VERSION "HNNBNNNYNNNNNNNNNNNNNNNNNNNNNNNNNNNNNNNNNN/4/%%%/4/'%**4NNN///"

NS_ :

BS_:

BU_: BAP_Tester BedienDisp_mi BedienDisp_vo_mi CDI ConMod_CD DashCAM Gateway_Max ICC_IO_Node LSH OCU RDK_RS3 Sound_MIB_ab_Gen3 STH ZR_MIB_EINSTIEG_ab_Gen3 ZR_MIB_OPTION_ab_Gen3 ZR_MIB_TOP_ab_Gen3

BO_ 2589283936 AC_FES_Atmosphere_01: 8 Gateway_Max
 SG_ AC_FES_Atmosphere_AMB_RGB_1 : 16|24@1+ (1,0) [0|16777215] "Unit_None"  BedienDisp_mi
 SG_ AC_FES_Atmosphere_AMB_RGB_2 : 40|24@1+ (1,0) [0|16777215] "Unit_None"  BedienDisp_mi

BO_ 2589283937 AC_FES_Atmosphere_02: 8 Gateway_Max
 SG_ AC_FES_Atmosphere_AMB_RGB_3 : 16|24@1+ (1,0) [0|16777215] "Unit_None"  BedienDisp_mi
 SG_ AC_FES_Atmosphere_AMB_RGB_4 : 40|24@1+ (1,0) [0|16777215] "Unit_None"  BedienDisp_mi

BO_ 2589283938 AC_FES_Atmosphere_03: 8 Gateway_Max
 SG_ AC_FES_Atmosphere_AMB_RGB_5 : 16|24@1+ (1,0) [0|16777215] "Unit_None"  BedienDisp_mi
 SG_ AC_FES_Atmosphere_AMB_RGB_6 : 40|24@1+ (1,0) [0|16777215] "Unit_None"  BedienDisp_mi

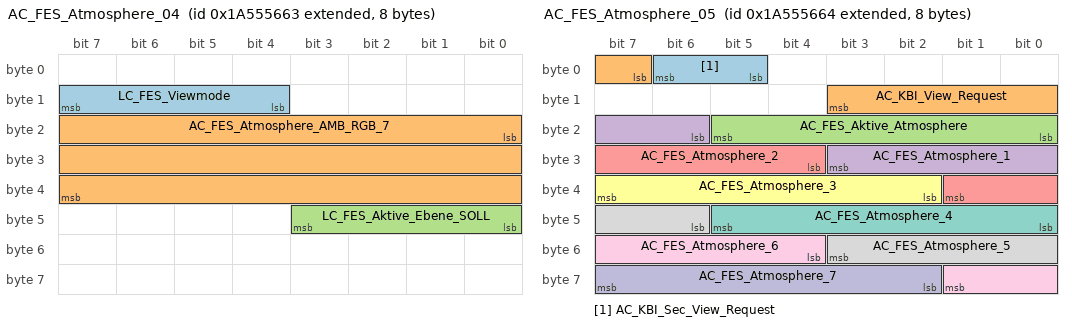
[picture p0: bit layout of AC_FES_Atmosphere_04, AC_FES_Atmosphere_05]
BO_ 2589283939 AC_FES_Atmosphere_04: 8 Gateway_Max
 SG_ LC_FES_Viewmode : 12|4@1+ (1.0,0.0) [0.0|15] ""  BedienDisp_mi
 SG_ AC_FES_Atmosphere_AMB_RGB_7 : 16|24@1+ (1,0) [0|16777215] "Unit_None"  BedienDisp_mi
 SG_ LC_FES_Aktive_Ebene_SOLL : 40|4@1+ (1.0,0.0) [0.0|15] ""  BedienDisp_mi

BO_ 2589283940 AC_FES_Atmosphere_05: 8 Gateway_Max
 SG_ AC_KBI_Sec_View_Request : 5|2@1+ (1.0,0.0) [0.0|3] ""  Gateway_Max
 SG_ AC_KBI_View_Request : 7|5@1+ (1.0,0.0) [0.0|31] ""  Gateway_Max
 SG_ AC_FES_Aktive_Atmosphere : 16|6@1+ (1.0,0.0) [0.0|63] ""  BedienDisp_mi,Gateway_Max
 SG_ AC_FES_Atmosphere_1 : 22|6@1+ (1.0,0.0) [0.0|63] ""  BedienDisp_mi,Gateway_Max
 SG_ AC_FES_Atmosphere_2 : 28|6@1+ (1.0,0.0) [0.0|63] ""  BedienDisp_mi,Gateway_Max
 SG_ AC_FES_Atmosphere_3 : 34|6@1+ (1.0,0.0) [0.0|63] ""  BedienDisp_mi,Gateway_Max
 SG_ AC_FES_Atmosphere_4 : 40|6@1+ (1.0,0.0) [0.0|63] ""  BedienDisp_mi,Gateway_Max
 SG_ AC_FES_Atmosphere_5 : 46|6@1+ (1.0,0.0) [0.0|63] ""  BedienDisp_mi,Gateway_Max
 SG_ AC_FES_Atmosphere_6 : 52|6@1+ (1.0,0.0) [0.0|63] ""  BedienDisp_mi,Gateway_Max
 SG_ AC_FES_Atmosphere_7 : 58|6@1+ (1.0,0.0) [0.0|63] ""  BedienDisp_mi,Gateway_Max

BO_ 680 ACC_14: 8 Gateway_Max
 SG_ ACA_Querfuehrung_Texte : 0|3@1+ (1.0,0.0) [0.0|7] ""  Vector__XXX
 SG_ ACA_Hinweistexte : 3|3@1+ (1.0,0.0) [0.0|7] ""  Vector__XXX
 SG_ ACC_FoD_Status : 6|2@1+ (1.0,0.0) [0.0|3] ""  Vector__XXX
 SG_ ACC_Texte_Abstandswarner : 8|2@1+ (1.0,0.0) [0.0|3] ""  Vector__XXX
 SG_ ACC_Vorz_Abstandswarner : 10|2@1+ (1.0,0.0) [0.0|3] ""  Vector__XXX
 SG_ ACC_Texte_Sekundaeranz : 12|4@1+ (1.0,0.0) [0.0|15] ""  Vector__XXX
 SG_ ACC_Status_Anzeige : 16|3@1+ (1.0,0.0) [0.0|7] ""  ZR_MIB_EINSTIEG_ab_Gen3,ZR_MIB_OPTION_ab_Gen3,ZR_MIB_TOP_ab_Gen3
 SG_ ACC_Akustik_03 : 19|3@1+ (1.0,0.0) [0.0|7] ""  Vector__XXX
 SG_ ACC_Geschw_Zielfahrzeug : 22|10@1+ (0.32,0) [0.00|326.72] "Unit_KiloMeterPerHour"  Vector__XXX
 SG_ ACC_Texte_02 : 32|6@1+ (1.0,0.0) [0.0|63] ""  Vector__XXX
 SG_ ACC_STA_Text : 38|1@1+ (1.0,0.0) [0.0|1] ""  Vector__XXX
 SG_ ACC_Status_Stauende : 39|1@1+ (1.0,0.0) [0.0|1] ""  Vector__XXX
 SG_ STA_Texte : 40|3@1+ (1.0,0.0) [0.0|7] ""  Vector__XXX
 SG_ AbstWarn_LRR_FAS_Fkt_Status : 43|2@1+ (1.0,0.0) [0.0|3] ""  Vector__XXX
 SG_ STA_Zusatzanz : 45|2@1+ (1.0,0.0) [0.0|3] ""  Vector__XXX
 SG_ FAS_Licht_Anf : 47|1@1+ (1.0,0.0) [0.0|1] ""  Vector__XXX
 SG_ ACC_Zeitluecke_Abstandswarner : 48|6@1+ (0.1,0) [0.0|6.0] "Unit_Secon"  Vector__XXX
 SG_ ACC_Abstand_Abstandswarner : 54|9@1+ (1,0) [0|508] ""  Vector__XXX
 SG_ ACC_Einheit_Abstandswarner : 63|1@1+ (1.0,0.0) [0.0|1] ""  Vector__XXX

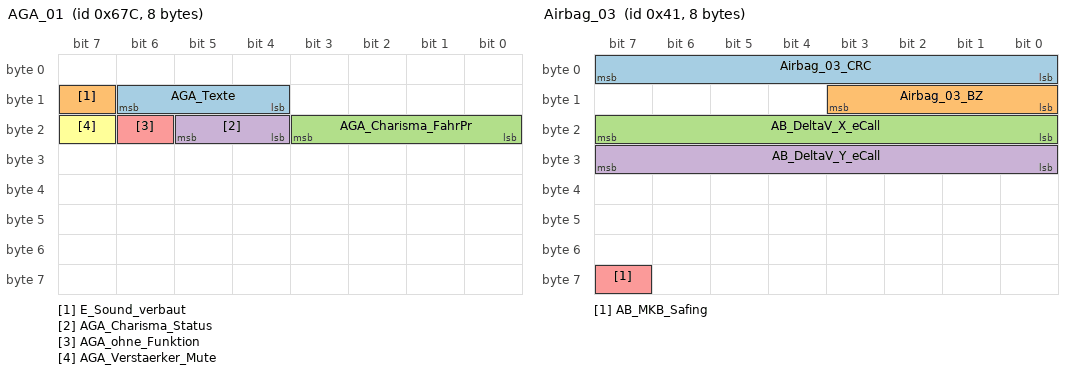
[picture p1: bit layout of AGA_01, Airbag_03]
BO_ 1660 AGA_01: 8 Gateway_Max
 SG_ AGA_Texte : 12|3@1+ (1.0,0.0) [0.0|7] ""  Vector__XXX
 SG_ E_Sound_verbaut : 15|1@1+ (1.0,0.0) [0.0|1] ""  Vector__XXX
 SG_ AGA_Charisma_FahrPr : 16|4@1+ (1.0,0.0) [0.0|15] ""  Vector__XXX
 SG_ AGA_Charisma_Status : 20|2@1+ (1.0,0.0) [0.0|3] ""  Vector__XXX
 SG_ AGA_ohne_Funktion : 22|1@1+ (1.0,0.0) [0.0|1] ""  Vector__XXX
 SG_ AGA_Verstaerker_Mute : 23|1@1+ (1.0,0.0) [0.0|1] ""  ZR_MIB_TOP_ab_Gen3

BO_ 64 Airbag_01: 8 Gateway_Max
 SG_ Airbag_01_CRC : 0|8@1+ (1,0) [0|255] ""  OCU
 SG_ Airbag_01_BZ : 8|4@1+ (1,0) [0|15] ""  OCU
 SG_ AB_RGS_Anst : 12|4@1+ (1.0,0.0) [0.0|15] ""  Vector__XXX
 SG_ AB_Front_Crash : 16|1@1+ (1.0,0.0) [0.0|1] ""  ConMod_CD,OCU
 SG_ AB_Heck_Crash : 17|1@1+ (1.0,0.0) [0.0|1] ""  ConMod_CD,OCU
 SG_ AB_SF_Crash : 18|1@1+ (1.0,0.0) [0.0|1] ""  ConMod_CD,OCU
 SG_ AB_SB_Crash : 19|1@1+ (1.0,0.0) [0.0|1] ""  ConMod_CD,OCU
 SG_ AB_Rollover_Crash : 20|1@1+ (1.0,0.0) [0.0|1] ""  ConMod_CD,OCU
 SG_ AB_Crash_Int : 21|3@1+ (1.0,0.0) [0.0|7] ""  ConMod_CD,LSH,OCU,STH,ZR_MIB_EINSTIEG_ab_Gen3,ZR_MIB_OPTION_ab_Gen3,ZR_MIB_TOP_ab_Gen3
 SG_ AB_Lampe : 24|1@1+ (1.0,0.0) [0.0|1] ""  OCU
 SG_ AB_Deaktiviert : 25|1@1+ (1.0,0.0) [0.0|1] ""  Vector__XXX
 SG_ AB_VB_deaktiviert : 26|1@1+ (1.0,0.0) [0.0|1] ""  OCU
 SG_ AB_Systemfehler : 27|1@1+ (1.0,0.0) [0.0|1] ""  ConMod_CD,OCU
 SG_ AB_Diagnose : 28|1@1+ (1.0,0.0) [0.0|1] ""  ConMod_CD,OCU
 SG_ AB_Stellgliedtest : 29|1@1+ (1.0,0.0) [0.0|1] ""  ConMod_CD,LSH,OCU,STH,ZR_MIB_EINSTIEG_ab_Gen3,ZR_MIB_OPTION_ab_Gen3,ZR_MIB_TOP_ab_Gen3
 SG_ AB_Erh_Auf_VB : 30|2@1+ (1.0,0.0) [0.0|3] ""  Vector__XXX
 SG_ AB_Gurtwarn_VF : 32|1@1+ (1.0,0.0) [0.0|1] ""  OCU
 SG_ AB_Gurtwarn_VB : 33|1@1+ (1.0,0.0) [0.0|1] ""  OCU
 SG_ AB_Anzeige_Fussg : 34|2@1+ (1.0,0.0) [0.0|3] ""  ConMod_CD,OCU
 SG_ AB_Texte_AKS : 36|2@1+ (1.0,0.0) [0.0|3] ""  OCU
 SG_ AB_PAO_Leuchte_Anf : 38|1@1+ (1.0,0.0) [0.0|1] ""  Vector__XXX
 SG_ AB_MKB_gueltig : 39|1@1+ (1.0,0.0) [0.0|1] ""  Vector__XXX
 SG_ AB_MKB_Anforderung : 40|1@1+ (1.0,0.0) [0.0|1] ""  Vector__XXX
 SG_ AB_Versorgungsspannung : 41|1@1+ (1.0,0.0) [0.0|1] ""  Vector__XXX
 SG_ AB_Deaktivierung_HV : 42|3@1+ (1.0,0.0) [0.0|7] ""  OCU
 SG_ AB_EDR_Trigger : 45|2@1+ (1.0,0.0) [0.0|3] ""  OCU
 SG_ AB_Belegung_VF : 47|2@1+ (1.0,0.0) [0.0|3] ""  BedienDisp_mi,OCU
 SG_ AB_Gurtschloss_FA_ext : 49|3@1+ (1.0,0.0) [0.0|7] ""  OCU
 SG_ AB_Gurtschloss_FA_ext_aktiv : 52|1@1+ (1.0,0.0) [0.0|1] ""  Vector__XXX
 SG_ AB_eCS_Error : 53|1@1+ (1.0,0.0) [0.0|1] ""  Vector__XXX
 SG_ ASM_Masterzeit_02 : 56|8@1+ (0.04,0) [0.00|10.16] "Unit_Secon"  Vector__XXX

BO_ 1312 Airbag_02: 8 Gateway_Max
 SG_ Airbag_02_CRC : 0|8@1+ (1,0) [0|255] ""  Vector__XXX
 SG_ Airbag_02_BZ : 8|4@1+ (1,0) [0|15] ""  Vector__XXX
 SG_ LoGeWa_Event_Kombiwarnung : 12|4@1+ (1.0,0.0) [0.0|15] ""  Vector__XXX
 SG_ AB_Anforderung_eCall : 16|1@1+ (1.0,0.0) [0.0|1] ""  Vector__XXX
 SG_ AB_Anprall_Seite_Beifahrer : 17|1@1+ (1.0,0.0) [0.0|1] ""  OCU
 SG_ AB_Anprall_Rollover : 18|1@1+ (1.0,0.0) [0.0|1] ""  Vector__XXX
 SG_ AB_Anprall_FGS : 19|1@1+ (1.0,0.0) [0.0|1] ""  OCU
 SG_ AB_Anprall_Front_Beifahrer : 20|1@1+ (1.0,0.0) [0.0|1] ""  OCU
 SG_ AB_Anprall_Front_Fahrer : 21|1@1+ (1.0,0.0) [0.0|1] ""  OCU
 SG_ AB_Anprall_Heck_Beifahrer : 22|1@1+ (1.0,0.0) [0.0|1] ""  Vector__XXX
 SG_ AB_Anprall_Heck_Fahrer : 23|1@1+ (1.0,0.0) [0.0|1] ""  Vector__XXX
 SG_ AB_Wickelklappung_Reihe2_MI : 24|2@1+ (1.0,0.0) [0.0|3] ""  Vector__XXX
 SG_ AB_Belegung_VB : 26|2@1+ (1.0,0.0) [0.0|3] ""  ConMod_CD,OCU,ZR_MIB_EINSTIEG_ab_Gen3,ZR_MIB_OPTION_ab_Gen3,ZR_MIB_TOP_ab_Gen3
 SG_ AB_Abschaltanf_SIH_BF : 28|1@1+ (1.0,0.0) [0.0|1] ""  Vector__XXX
 SG_ AB_Anprall_Seite_Fahrer : 29|1@1+ (1.0,0.0) [0.0|1] ""  OCU
 SG_ SC_PAO_Schriftzug_Anf : 30|2@1+ (1.0,0.0) [0.0|3] ""  Vector__XXX
 SG_ SC_PAO_ON_Anf : 32|2@1+ (1.0,0.0) [0.0|3] ""  Vector__XXX
 SG_ SC_PAO_OFF_Anf : 34|2@1+ (1.0,0.0) [0.0|3] ""  Vector__XXX
 SG_ AB_Crashschwere : 36|3@1+ (1.0,0.0) [0.0|7] ""  DashCAM,OCU
 SG_ AB_Anforderung_USM : 39|1@1+ (1.0,0.0) [0.0|1] ""  OCU
 SG_ AB_Gurtschloss_FA : 40|2@1+ (1.0,0.0) [0.0|3] ""  BedienDisp_mi,ConMod_CD,OCU,ZR_MIB_EINSTIEG_ab_Gen3,ZR_MIB_OPTION_ab_Gen3
 SG_ AB_Gurtschloss_BF : 42|2@1+ (1.0,0.0) [0.0|3] ""  ConMod_CD,OCU,ZR_MIB_EINSTIEG_ab_Gen3,ZR_MIB_OPTION_ab_Gen3,ZR_MIB_TOP_ab_Gen3
 SG_ AB_Gurtschloss_Reihe2_FA : 44|2@1+ (1.0,0.0) [0.0|3] ""  ConMod_CD,OCU,ZR_MIB_EINSTIEG_ab_Gen3,ZR_MIB_OPTION_ab_Gen3,ZR_MIB_TOP_ab_Gen3
 SG_ AB_Gurtschloss_Reihe2_MI : 46|2@1+ (1.0,0.0) [0.0|3] ""  ConMod_CD,OCU,ZR_MIB_EINSTIEG_ab_Gen3,ZR_MIB_OPTION_ab_Gen3,ZR_MIB_TOP_ab_Gen3
 SG_ AB_Gurtschloss_Reihe2_BF : 48|2@1+ (1.0,0.0) [0.0|3] ""  ConMod_CD,OCU,ZR_MIB_EINSTIEG_ab_Gen3,ZR_MIB_OPTION_ab_Gen3,ZR_MIB_TOP_ab_Gen3
 SG_ AB_Gurtschloss_Reihe3_FA : 50|2@1+ (1.0,0.0) [0.0|3] ""  ConMod_CD,OCU,ZR_MIB_EINSTIEG_ab_Gen3,ZR_MIB_OPTION_ab_Gen3
 SG_ AB_Gurtschloss_Reihe3_MI : 52|2@1+ (1.0,0.0) [0.0|3] ""  ConMod_CD,OCU,ZR_MIB_EINSTIEG_ab_Gen3,ZR_MIB_OPTION_ab_Gen3
 SG_ AB_Gurtschloss_Reihe3_BF : 54|2@1+ (1.0,0.0) [0.0|3] ""  ConMod_CD,OCU,ZR_MIB_EINSTIEG_ab_Gen3,ZR_MIB_OPTION_ab_Gen3
 SG_ AB_Sitzpos_Sens_FA : 56|2@1+ (1.0,0.0) [0.0|3] ""  OCU
 SG_ AB_Sitzpos_Sens_BF : 58|2@1+ (1.0,0.0) [0.0|3] ""  OCU
 SG_ AB_Wickelklappung_Reihe2_BF : 60|2@1+ (1.0,0.0) [0.0|3] ""  Vector__XXX
 SG_ AB_Wickelklappung_Reihe2_FA : 62|2@1+ (1.0,0.0) [0.0|3] ""  Vector__XXX

BO_ 65 Airbag_03: 8 Gateway_Max
 SG_ Airbag_03_CRC : 0|8@1+ (1,0) [0|255] ""  Vector__XXX
 SG_ Airbag_03_BZ : 8|4@1+ (1,0) [0|15] ""  Vector__XXX
 SG_ AB_DeltaV_X_eCall : 16|8@1+ (1,-128) [-126|126] "Unit_KiloMeterPerHour"  ConMod_CD
 SG_ AB_DeltaV_Y_eCall : 24|8@1+ (1,-128) [-126|126] "Unit_KiloMeterPerHour"  ConMod_CD
 SG_ AB_MKB_Safing : 63|1@1+ (1.0,0.0) [0.0|1] ""  Vector__XXX

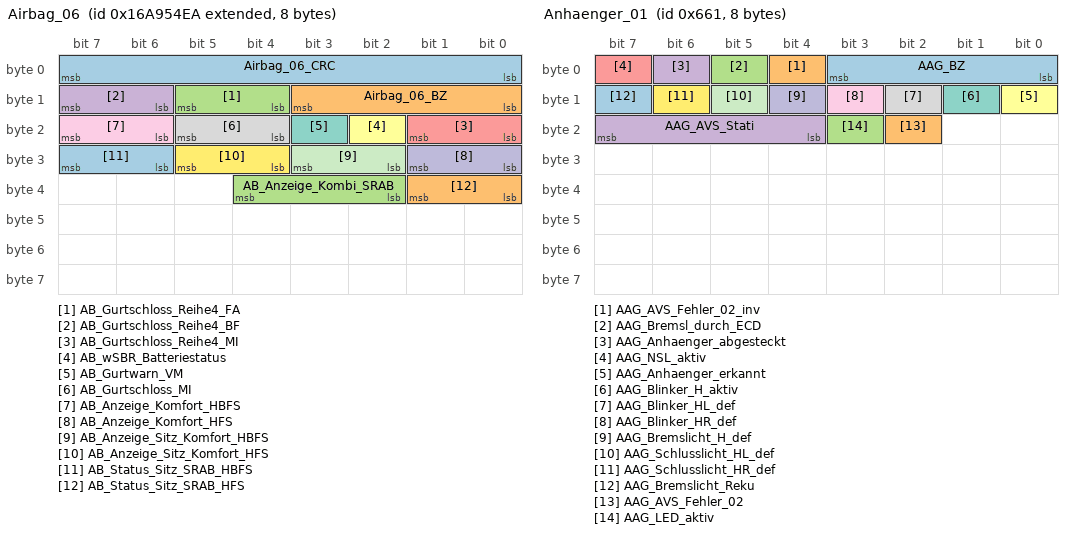
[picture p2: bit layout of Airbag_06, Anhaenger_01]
BO_ 2527679722 Airbag_06: 8 Gateway_Max
 SG_ Airbag_06_CRC : 0|8@1+ (1,0) [0|255] ""  Vector__XXX
 SG_ Airbag_06_BZ : 8|4@1+ (1,0) [0|15] ""  Vector__XXX
 SG_ AB_Gurtschloss_Reihe4_FA : 12|2@1+ (1.0,0.0) [0.0|3] ""  Vector__XXX
 SG_ AB_Gurtschloss_Reihe4_BF : 14|2@1+ (1.0,0.0) [0.0|3] ""  Vector__XXX
 SG_ AB_Gurtschloss_Reihe4_MI : 16|2@1+ (1.0,0.0) [0.0|3] ""  Vector__XXX
 SG_ AB_wSBR_Batteriestatus : 18|1@1+ (1.0,0.0) [0.0|1] ""  Vector__XXX
 SG_ AB_Gurtwarn_VM : 19|1@1+ (1.0,0.0) [0.0|1] ""  Vector__XXX
 SG_ AB_Gurtschloss_MI : 20|2@1+ (1.0,0.0) [0.0|3] ""  ConMod_CD
 SG_ AB_Anzeige_Komfort_HBFS : 22|2@1+ (1.0,0.0) [0.0|3] ""  Vector__XXX
 SG_ AB_Anzeige_Komfort_HFS : 24|2@1+ (1.0,0.0) [0.0|3] ""  Vector__XXX
 SG_ AB_Anzeige_Sitz_Komfort_HBFS : 26|2@1+ (1.0,0.0) [0.0|3] ""  Vector__XXX
 SG_ AB_Anzeige_Sitz_Komfort_HFS : 28|2@1+ (1.0,0.0) [0.0|3] ""  Vector__XXX
 SG_ AB_Status_Sitz_SRAB_HBFS : 30|2@1+ (1.0,0.0) [0.0|3] ""  Vector__XXX
 SG_ AB_Status_Sitz_SRAB_HFS : 32|2@1+ (1.0,0.0) [0.0|3] ""  Vector__XXX
 SG_ AB_Anzeige_Kombi_SRAB : 34|3@1+ (1.0,0.0) [0.0|7] ""  Vector__XXX

BO_ 1633 Anhaenger_01: 8 Gateway_Max
 SG_ AAG_BZ : 0|4@1+ (1,0) [0|15] ""  Vector__XXX
 SG_ AAG_AVS_Fehler_02_inv : 4|1@1+ (1.0,0.0) [0.0|1] ""  Vector__XXX
 SG_ AAG_Bremsl_durch_ECD : 5|1@1+ (1.0,0.0) [0.0|1] ""  Vector__XXX
 SG_ AAG_Anhaenger_abgesteckt : 6|1@1+ (1.0,0.0) [0.0|1] ""  OCU
 SG_ AAG_NSL_aktiv : 7|1@1+ (1.0,0.0) [0.0|1] ""  Vector__XXX
 SG_ AAG_Anhaenger_erkannt : 8|1@1+ (1.0,0.0) [0.0|1] ""  OCU,ZR_MIB_EINSTIEG_ab_Gen3,ZR_MIB_OPTION_ab_Gen3,ZR_MIB_TOP_ab_Gen3
 SG_ AAG_Blinker_H_aktiv : 9|1@1+ (1.0,0.0) [0.0|1] ""  Vector__XXX
 SG_ AAG_Blinker_HL_def : 10|1@1+ (1.0,0.0) [0.0|1] ""  Vector__XXX
 SG_ AAG_Blinker_HR_def : 11|1@1+ (1.0,0.0) [0.0|1] ""  Vector__XXX
 SG_ AAG_Bremslicht_H_def : 12|1@1+ (1.0,0.0) [0.0|1] ""  Vector__XXX
 SG_ AAG_Schlusslicht_HL_def : 13|1@1+ (1.0,0.0) [0.0|1] ""  Vector__XXX
 SG_ AAG_Schlusslicht_HR_def : 14|1@1+ (1.0,0.0) [0.0|1] ""  Vector__XXX
 SG_ AAG_Bremslicht_Reku : 15|1@1+ (1.0,0.0) [0.0|1] ""  Vector__XXX
 SG_ AAG_AVS_Fehler_02 : 18|1@1+ (1.0,0.0) [0.0|1] ""  Vector__XXX
 SG_ AAG_LED_aktiv : 19|1@1+ (1.0,0.0) [0.0|1] ""  OCU
 SG_ AAG_AVS_Stati : 20|4@1+ (1.0,0.0) [0.0|15] ""  Vector__XXX

BO_ 2549880935 AuthTime_eCall_Req: 8 Gateway_Max
 SG_ AuthTime_eCall_Req_Data : 0|64@1+ (1.0,0.0) [0.0|18446744073709551615] ""  ConMod_CD,OCU

BO_ 2550012007 AuthTime_eCall_Resp: 8 ConMod_CD
 SG_ AuthTime_eCall_Resp_Data : 0|64@1+ (1.0,0.0) [0.0|18446744073709551615] ""  Gateway_Max

BO_ 2536703232 BAP_ACC_ASG_01: 8 ZR_MIB_EINSTIEG_ab_Gen3
 SG_ BAP_ACC_ASG_01_Header : 0|8@1+ (1.0,0.0) [0.0|255] ""  Gateway_Max

BO_ 2536703234 BAP_ACC_ASG_03: 8 OCU
 SG_ BAP_ACC_ASG_03_Header : 0|8@1+ (1,0) [0|255] "Unit_None"  Gateway_Max

BO_ 2536703248 BAP_ACC_FSG_01: 8 Gateway_Max
 SG_ BAP_ACC_FSG_01_Header : 0|8@1+ (1.0,0.0) [0.0|255] ""  OCU,ZR_MIB_EINSTIEG_ab_Gen3,ZR_MIB_OPTION_ab_Gen3,ZR_MIB_TOP_ab_Gen3

BO_ 2536714496 BAP_Audio_ASG_01: 8 Gateway_Max
 SG_ BAP_Audio_ASG_01_Header : 0|8@1+ (1.0,0.0) [0.0|255] ""  ZR_MIB_EINSTIEG_ab_Gen3,ZR_MIB_OPTION_ab_Gen3,ZR_MIB_TOP_ab_Gen3

BO_ 2536714497 BAP_Audio_ASG_02: 8 Gateway_Max
 SG_ BAP_Audio_ASG_02_Header : 0|8@1+ (1.0,0.0) [0.0|255] ""  ZR_MIB_EINSTIEG_ab_Gen3,ZR_MIB_OPTION_ab_Gen3,ZR_MIB_TOP_ab_Gen3

BO_ 2536714498 BAP_Audio_ASG_03: 8 Gateway_Max
 SG_ BAP_Audio_ASG_03_Header : 0|8@1+ (1.0,0.0) [0.0|255] ""  Vector__XXX

BO_ 2536714499 BAP_Audio_ASG_04: 8 Gateway_Max
 SG_ BAP_Audio_ASG_04_Header : 0|8@1+ (1.0,0.0) [0.0|255] ""  Vector__XXX

BO_ 2536714504 BAP_Audio_ASG_09: 8 Gateway_Max
 SG_ BAP_Audio_ASG_09_Header : 0|64@1+ (1.0,0.0) [0.0|18446744073709551615] ""  ZR_MIB_OPTION_ab_Gen3

BO_ 2536714505 BAP_Audio_ASG_10: 8 Gateway_Max
 SG_ BAP_Audio_ASG_10_Header : 0|64@1+ (1.0,0.0) [0.0|18446744073709551615] ""  ZR_MIB_OPTION_ab_Gen3

BO_ 2536714506 BAP_Audio_ASG_11: 8 Gateway_Max
 SG_ BAP_Audio_ASG_11_Header : 0|64@1+ (1.0,0.0) [0.0|18446744073709551615] ""  ZR_MIB_OPTION_ab_Gen3

BO_ 2536714507 BAP_Audio_ASG_12: 8 Gateway_Max
 SG_ BAP_Audio_ASG_12_Header : 0|64@1+ (1.0,0.0) [0.0|18446744073709551615] ""  ZR_MIB_OPTION_ab_Gen3

BO_ 2536714512 BAP_Audio_FSG_01: 8 ZR_MIB_EINSTIEG_ab_Gen3
 SG_ BAP_Audio_FSG_01_Header : 0|8@1+ (1.0,0.0) [0.0|255] ""  Gateway_Max

BO_ 2536714513 BAP_Audio_FSG_02: 8 ZR_MIB_EINSTIEG_ab_Gen3
 SG_ BAP_Audio_FSG_02_Header : 0|8@1+ (1.0,0.0) [0.0|255] ""  Gateway_Max

BO_ 2536704256 BAP_Aussenlicht_ASG_01: 8 ZR_MIB_EINSTIEG_ab_Gen3
 SG_ BAP_Aussenlicht_ASG_01_Header : 0|8@1+ (1.0,0.0) [0.0|255] ""  Gateway_Max

BO_ 2536704257 BAP_Aussenlicht_ASG_02: 8 OCU
 SG_ BAP_Aussenlicht_ASG_02_Header : 0|8@1+ (1,0) [0|255] "Unit_None"  Gateway_Max

BO_ 2536704272 BAP_Aussenlicht_FSG_01: 8 Gateway_Max
 SG_ BAP_Aussenlicht_FSG_01_Header : 0|8@1+ (1.0,0.0) [0.0|255] ""  OCU,ZR_MIB_EINSTIEG_ab_Gen3,ZR_MIB_OPTION_ab_Gen3,ZR_MIB_TOP_ab_Gen3

BO_ 2536708864 BAP_AWV_ASG_01: 8 ZR_MIB_EINSTIEG_ab_Gen3
 SG_ BAP_AWV_ASG_01_Header : 0|8@1+ (1.0,0.0) [0.0|255] ""  Gateway_Max

BO_ 2536708866 BAP_AWV_ASG_03: 8 OCU
 SG_ BAP_AWV_ASG_03_Header : 0|8@1+ (1,0) [0|255] "Unit_None"  Gateway_Max

BO_ 2536708880 BAP_AWV_FSG_01: 8 Gateway_Max
 SG_ BAP_AWV_FSG_01_Header : 0|8@1+ (1.0,0.0) [0.0|255] ""  OCU,ZR_MIB_EINSTIEG_ab_Gen3,ZR_MIB_OPTION_ab_Gen3,ZR_MIB_TOP_ab_Gen3

BO_ 2536711424 BAP_BatteryControl_ASG_01: 8 ZR_MIB_EINSTIEG_ab_Gen3
 SG_ BAP_BatteryControl_ASG_01_Header : 0|8@1+ (1.0,0.0) [0.0|255] ""  Gateway_Max

BO_ 2536711425 BAP_BatteryControl_ASG_02: 8 OCU
 SG_ BAP_BatteryControl_ASG_02_Header : 0|8@1+ (1.0,0.0) [0.0|255] ""  Gateway_Max

BO_ 2536711440 BAP_BatteryControl_FSG_01: 8 Gateway_Max
 SG_ BAP_BatteryControl_FSG_01_Header : 0|8@1+ (1.0,0.0) [0.0|255] ""  OCU,ZR_MIB_EINSTIEG_ab_Gen3,ZR_MIB_OPTION_ab_Gen3,ZR_MIB_TOP_ab_Gen3

BO_ 2536705792 BAP_BC_ASG_01: 8 ZR_MIB_EINSTIEG_ab_Gen3
 SG_ BAP_BC_ASG_01_Header : 0|8@1+ (1.0,0.0) [0.0|255] ""  Gateway_Max

BO_ 2536705793 BAP_BC_ASG_02: 8 OCU
 SG_ BAP_BC_ASG_02_Header : 0|8@1+ (1.0,0.0) [0.0|255] ""  Gateway_Max

BO_ 2536705808 BAP_BC_FSG_01: 8 Gateway_Max
 SG_ BAP_BC_FSG_01_Header : 0|8@1+ (1.0,0.0) [0.0|255] ""  OCU,ZR_MIB_EINSTIEG_ab_Gen3,ZR_MIB_OPTION_ab_Gen3,ZR_MIB_TOP_ab_Gen3

BO_ 2536705809 BAP_BC_FSG_02: 8 Gateway_Max
 SG_ BAP_BC_FSG_02_Header : 0|64@1+ (1.0,0.0) [0.0|18446744073709551615] ""  OCU,ZR_MIB_EINSTIEG_ab_Gen3,ZR_MIB_OPTION_ab_Gen3,ZR_MIB_TOP_ab_Gen3

BO_ 2536710913 BAP_BCmE_ASG_02: 8 ZR_MIB_EINSTIEG_ab_Gen3
 SG_ BAP_BCmE_ASG_02_Header : 0|8@1+ (1.0,0.0) [0.0|255] ""  Gateway_Max

BO_ 2536710928 BAP_BCmE_FSG_01: 8 Gateway_Max
 SG_ BAP_BCmE_FSG_01_Header : 0|8@1+ (1.0,0.0) [0.0|255] ""  ZR_MIB_EINSTIEG_ab_Gen3,ZR_MIB_OPTION_ab_Gen3,ZR_MIB_TOP_ab_Gen3

BO_ 2536711680 BAP_Brake_ASG_01: 8 ZR_MIB_EINSTIEG_ab_Gen3
 SG_ BAP_Brake_ASG_01_Header : 0|8@1+ (1.0,0.0) [0.0|255] ""  Gateway_Max

BO_ 2536711696 BAP_Brake_FSG_01: 8 Gateway_Max
 SG_ BAP_Brake_FSG_01_Header : 0|8@1+ (1.0,0.0) [0.0|255] ""  ZR_MIB_EINSTIEG_ab_Gen3,ZR_MIB_OPTION_ab_Gen3,ZR_MIB_TOP_ab_Gen3

BO_ 2536733184 BAP_BSMOIS2_ASG_01: 8 ZR_MIB_EINSTIEG_ab_Gen3
 SG_ BAP_BSMOIS2_ASG_01_Header : 0|64@1+ (1.0,0.0) [0.0|18446744073709551615] ""  Gateway_Max

BO_ 2536733200 BAP_BSMOIS2_FSG_01: 8 Gateway_Max
 SG_ BAP_BSMOIS2_FSG_01_Header : 0|64@1+ (1.0,0.0) [0.0|18446744073709551615] ""  ZR_MIB_EINSTIEG_ab_Gen3,ZR_MIB_OPTION_ab_Gen3

BO_ 2536733440 BAP_BSMOIS3_ASG_01: 8 ZR_MIB_EINSTIEG_ab_Gen3
 SG_ BAP_BSMOIS3_ASG_01_Header : 0|64@1+ (1.0,0.0) [0.0|18446744073709551615] ""  Gateway_Max

BO_ 2536733456 BAP_BSMOIS3_FSG_01: 8 Gateway_Max
 SG_ BAP_BSMOIS3_FSG_01_Header : 0|64@1+ (1.0,0.0) [0.0|18446744073709551615] ""  ZR_MIB_EINSTIEG_ab_Gen3,ZR_MIB_OPTION_ab_Gen3

BO_ 2536732160 BAP_BSMOIS_ASG_01: 8 ZR_MIB_EINSTIEG_ab_Gen3
 SG_ BAP_BSMOIS_ASG_01_Header : 0|64@1+ (1.0,0.0) [0.0|18446744073709551615] ""  Gateway_Max

BO_ 2536732176 BAP_BSMOIS_FSG_01: 8 Gateway_Max
 SG_ BAP_BSMOIS_FSG_01_Header : 0|64@1+ (1.0,0.0) [0.0|18446744073709551615] ""  ZR_MIB_EINSTIEG_ab_Gen3,ZR_MIB_OPTION_ab_Gen3

BO_ 2536734976 BAP_California_ASG_01: 8 ZR_MIB_EINSTIEG_ab_Gen3
 SG_ BAP_California_ASG_01_Header : 0|64@1+ (1.0,0.0) [0.0|18446744073709551615] ""  Gateway_Max

BO_ 2536734992 BAP_California_FSG_01: 8 Gateway_Max
 SG_ BAP_California_FSG_01_Header : 0|64@1+ (1.0,0.0) [0.0|18446744073709551615] ""  ZR_MIB_EINSTIEG_ab_Gen3,ZR_MIB_OPTION_ab_Gen3

BO_ 2536726786 BAP_Car2X_ASG_03: 8 ZR_MIB_EINSTIEG_ab_Gen3
 SG_ BAP_Car2X_ASG_03_Header : 0|64@1+ (1.0,0.0) [0.0|18446744073709551615] ""  Gateway_Max

BO_ 2536726802 BAP_Car2X_FSG_03: 8 Gateway_Max
 SG_ BAP_Car2X_FSG_03_Header : 0|64@1+ (1.0,0.0) [0.0|18446744073709551615] ""  ZR_MIB_EINSTIEG_ab_Gen3,ZR_MIB_OPTION_ab_Gen3

BO_ 2536707840 BAP_Charisma_ASG_01: 8 ZR_MIB_EINSTIEG_ab_Gen3
 SG_ BAP_Charisma_ASG_01_Header : 0|8@1+ (1.0,0.0) [0.0|255] ""  Gateway_Max

BO_ 2536707844 BAP_Charisma_ASG_05: 8 OCU
 SG_ BAP_Charisma_ASG_05_Header : 0|8@1+ (1,0) [0|255] "Unit_None"  Gateway_Max

BO_ 2536707856 BAP_Charisma_FSG_01: 8 Gateway_Max
 SG_ BAP_Charisma_FSG_01_Header : 0|8@1+ (1.0,0.0) [0.0|255] ""  OCU,ZR_MIB_EINSTIEG_ab_Gen3,ZR_MIB_OPTION_ab_Gen3,ZR_MIB_TOP_ab_Gen3

BO_ 2536726528 BAP_ClimateDiag_ASG_01: 8 ZR_MIB_EINSTIEG_ab_Gen3
 SG_ BAP_ClimateDiag_ASG_01_Header : 0|64@1+ (1.0,0.0) [0.0|18446744073709551615] ""  Gateway_Max

BO_ 2536726544 BAP_ClimateDiag_FSG_01: 8 Gateway_Max
 SG_ BAP_ClimateDiag_FSG_01_Header : 0|64@1+ (1.0,0.0) [0.0|18446744073709551615] ""  ZR_MIB_EINSTIEG_ab_Gen3,ZR_MIB_OPTION_ab_Gen3

BO_ 2536767264 BAP_Debug_Cmd: 8 BAP_Tester
 SG_ BAP_Debug_Cmd : 0|16@1+ (1.0,0.0) [0.0|65535] ""  Gateway_Max,OCU,RDK_RS3,ZR_MIB_EINSTIEG_ab_Gen3,ZR_MIB_OPTION_ab_Gen3,ZR_MIB_TOP_ab_Gen3

BO_ 2536767280 BAP_Debug_Data: 8 Gateway_Max
 SG_ BAP_Debug_Data : 0|64@1+ (1.0,0.0) [0.0|18446744073709551615] ""  BAP_Tester

BO_ 2536719616 BAP_DisplayConfig_ASG_01: 8 ZR_MIB_TOP_ab_Gen3
 SG_ BAP_DisplayConfig_ASG_01_Header : 0|8@1+ (1,0) [0|255] "Unit_None"  Gateway_Max

BO_ 2536719617 BAP_DisplayConfig_ASG_02: 8 Vector__XXX
 SG_ BAP_DisplayConfig_ASG_02_Header : 0|64@1+ (1.0,0.0) [0.0|18446744073709551615] ""  Gateway_Max

BO_ 2536719632 BAP_DisplayConfig_FSG_01: 8 Gateway_Max
 SG_ BAP_DisplayConfig_FSG_01_Header : 0|8@1+ (1,0) [0|255] "Unit_None"  ZR_MIB_TOP_ab_Gen3

BO_ 2536705280 BAP_Doorlocking_ASG_01: 8 ZR_MIB_EINSTIEG_ab_Gen3
 SG_ BAP_Doorlocking_ASG_01_Header : 0|8@1+ (1.0,0.0) [0.0|255] ""  Gateway_Max

BO_ 2536705282 BAP_Doorlocking_ASG_03: 8 OCU
 SG_ BAP_Doorlocking_ASG_03_Header : 0|8@1+ (1.0,0.0) [0.0|255] ""  Gateway_Max

BO_ 2536705296 BAP_Doorlocking_FSG_01: 8 Gateway_Max
 SG_ BAP_Doorlocking_FSG_01_Header : 0|8@1+ (1.0,0.0) [0.0|255] ""  OCU,ZR_MIB_EINSTIEG_ab_Gen3,ZR_MIB_OPTION_ab_Gen3,ZR_MIB_TOP_ab_Gen3

BO_ 2536727296 BAP_Doors2_ASG_01: 8 OCU
 SG_ BAP_Doors2_ASG_01_Header : 0|64@1+ (1.0,0.0) [0.0|18446744073709551615] ""  Gateway_Max

BO_ 2536727312 BAP_Doors2_FSG_01: 8 Gateway_Max
 SG_ BAP_Doors2_FSG_01_Header : 0|64@1+ (1.0,0.0) [0.0|18446744073709551615] ""  OCU

BO_ 2536724736 BAP_Doors_ASG_01: 8 OCU
 SG_ BAP_Doors_ASG_01_Header : 0|8@1+ (1,0) [0|255] "Unit_None"  Gateway_Max

BO_ 2536724752 BAP_Doors_FSG_01: 8 Gateway_Max
 SG_ BAP_Doors_FSG_01_Header : 0|8@1+ (1,0) [0|255] "Unit_None"  OCU

BO_ 2536734208 BAP_DrivingDynamics_ASG_01: 8 ZR_MIB_OPTION_ab_Gen3
 SG_ BAP_DrivingDynamics_ASG_01_Hdr : 0|64@1+ (1.0,0.0) [0.0|18446744073709551615] ""  Gateway_Max

BO_ 2536734224 BAP_DrivingDynamics_FSG_01: 8 Gateway_Max
 SG_ BAP_DrivingDynamics_FSG_01_Hdr : 0|64@1+ (1.0,0.0) [0.0|18446744073709551615] ""  ZR_MIB_OPTION_ab_Gen3

BO_ 2536715008 BAP_eCall_ASG_01: 8 Gateway_Max
 SG_ BAP_eCall_ASG_01_Header : 0|8@1+ (1.0,0.0) [0.0|255] ""  Gateway_Max,OCU

BO_ 2536715024 BAP_eCall_FSG_01: 8 Gateway_Max
 SG_ BAP_eCall_FSG_01_Header : 0|8@1+ (1.0,0.0) [0.0|255] ""  Gateway_Max,ZR_MIB_EINSTIEG_ab_Gen3,ZR_MIB_OPTION_ab_Gen3,ZR_MIB_TOP_ab_Gen3

BO_ 2536717312 BAP_EfficiencyAssist_ASG_01: 8 ZR_MIB_EINSTIEG_ab_Gen3
 SG_ BAP_EfficAssist_ASG_01_Header : 0|8@1+ (1.0,0.0) [0.0|255] ""  Gateway_Max

BO_ 2536717328 BAP_EfficiencyAssist_FSG_01: 8 Gateway_Max
 SG_ BAP_EfficAssist_FSG_01_Header : 0|8@1+ (1.0,0.0) [0.0|255] ""  ZR_MIB_EINSTIEG_ab_Gen3,ZR_MIB_OPTION_ab_Gen3,ZR_MIB_TOP_ab_Gen3

BO_ 2536706816 BAP_Einheiten_ASG_01: 8 ZR_MIB_EINSTIEG_ab_Gen3
 SG_ BAP_Einheiten_ASG_01_Header : 0|8@1+ (1.0,0.0) [0.0|255] ""  Gateway_Max

BO_ 2536706819 BAP_Einheiten_ASG_04: 8 OCU
 SG_ BAP_Einheiten_ASG_04_Header : 0|8@1+ (1,0) [0|255] "Unit_None"  Gateway_Max

BO_ 2536706832 BAP_Einheiten_FSG_01: 8 Gateway_Max
 SG_ BAP_Einheiten_FSG_01_Header : 0|8@1+ (1.0,0.0) [0.0|255] ""  OCU,ZR_MIB_EINSTIEG_ab_Gen3,ZR_MIB_OPTION_ab_Gen3,ZR_MIB_TOP_ab_Gen3

BO_ 2536725760 BAP_EngFunctions_ASG_01: 8 ZR_MIB_EINSTIEG_ab_Gen3
 SG_ BAP_EngFunctions_ASG_01_Header : 0|8@1+ (1,0) [0|255] "Unit_None"  Gateway_Max

BO_ 2536725776 BAP_EngFunctions_FSG_01: 8 Gateway_Max
 SG_ BAP_EngFunctions_FSG_01_Header : 0|8@1+ (1,0) [0|255] "Unit_None"  ZR_MIB_EINSTIEG_ab_Gen3,ZR_MIB_OPTION_ab_Gen3,ZR_MIB_TOP_ab_Gen3

BO_ 2536724480 BAP_ENI2_ASG_01: 8 ZR_MIB_EINSTIEG_ab_Gen3
 SG_ BAP_ENI2_ASG_01_Header : 0|8@1+ (1,0) [0|255] "Unit_None"  Gateway_Max

BO_ 2536724481 BAP_ENI2_ASG_02: 8 ZR_MIB_EINSTIEG_ab_Gen3
 SG_ BAP_ENI2_ASG_02_Header : 0|8@1+ (1,0) [0|255] "Unit_None"  Gateway_Max

BO_ 2536724496 BAP_ENI2_FSG_01: 8 Gateway_Max
 SG_ BAP_ENI2_FSG_01_Header : 0|8@1+ (1,0) [0|255] "Unit_None"  ZR_MIB_EINSTIEG_ab_Gen3,ZR_MIB_OPTION_ab_Gen3,ZR_MIB_TOP_ab_Gen3

BO_ 2536724497 BAP_ENI2_FSG_02: 8 Gateway_Max
 SG_ BAP_ENI2_FSG_02_Header : 0|8@1+ (1,0) [0|255] "Unit_None"  ZR_MIB_EINSTIEG_ab_Gen3,ZR_MIB_OPTION_ab_Gen3,ZR_MIB_TOP_ab_Gen3

BO_ 2536730112 BAP_ENI3_ASG_01: 8 Vector__XXX
 SG_ BAP_ENI3_ASG_01_Header : 0|64@1+ (1.0,0.0) [0.0|18446744073709551615] ""  OCU

BO_ 2536730113 BAP_ENI3_ASG_02: 8 Vector__XXX
 SG_ BAP_ENI3_ASG_02_Header : 0|64@1+ (1.0,0.0) [0.0|18446744073709551615] ""  OCU

BO_ 2536730128 BAP_ENI3_FSG_01: 8 OCU
 SG_ BAP_ENI3_FSG_01_Header : 0|64@1+ (1.0,0.0) [0.0|18446744073709551615] ""  Vector__XXX

BO_ 2536730129 BAP_ENI3_FSG_02: 8 OCU
 SG_ BAP_ENI3_FSG_02_Header : 0|64@1+ (1.0,0.0) [0.0|18446744073709551615] ""  Vector__XXX

BO_ 2536716032 BAP_ENI_ASG_01: 8 ZR_MIB_EINSTIEG_ab_Gen3
 SG_ BAP_ENI_ASG_01_Header : 0|8@1+ (1.0,0.0) [0.0|255] ""  Gateway_Max,OCU

BO_ 2536716033 BAP_ENI_ASG_02: 8 ZR_MIB_EINSTIEG_ab_Gen3
 SG_ BAP_ENI_ASG_02_Header : 0|8@1+ (1,0) [0|255] "Unit_None"  Gateway_Max,OCU

BO_ 2536716048 BAP_ENI_FSG_01: 8 Gateway_Max
 SG_ BAP_ENI_FSG_01_Header : 0|8@1+ (1.0,0.0) [0.0|255] ""  ZR_MIB_EINSTIEG_ab_Gen3,ZR_MIB_OPTION_ab_Gen3,ZR_MIB_TOP_ab_Gen3

BO_ 2536716049 BAP_ENI_FSG_02: 8 Gateway_Max
 SG_ BAP_ENI_FSG_02_Header : 0|8@1+ (1.0,0.0) [0.0|255] ""  ZR_MIB_EINSTIEG_ab_Gen3,ZR_MIB_OPTION_ab_Gen3,ZR_MIB_TOP_ab_Gen3

BO_ 2536721664 BAP_FAS_Profiles_ASG_01: 8 ZR_MIB_EINSTIEG_ab_Gen3
 SG_ BAP_FAS_Profiles_ASG_01_Header : 0|8@1+ (1,0) [0|255] "Unit_None"  Gateway_Max

BO_ 2536721680 BAP_FAS_Profiles_FSG_01: 8 Gateway_Max
 SG_ BAP_FAS_Profiles_FSG_01_Header : 0|8@1+ (1,0) [0|255] "Unit_None"  ZR_MIB_EINSTIEG_ab_Gen3,ZR_MIB_OPTION_ab_Gen3,ZR_MIB_TOP_ab_Gen3

BO_ 2536707072 BAP_Homelink_ASG_01: 8 ZR_MIB_TOP_ab_Gen3
 SG_ BAP_Homelink_ASG_01_Header : 0|64@1+ (1.0,0.0) [0.0|18446744073709551615] ""  Gateway_Max

BO_ 2536707088 BAP_Homelink_FSG_01: 8 Gateway_Max
 SG_ BAP_Homelink_FSG_01_Header : 0|64@1+ (1.0,0.0) [0.0|18446744073709551615] ""  ZR_MIB_TOP_ab_Gen3

BO_ 2536702976 BAP_HUD_ASG_01: 8 ZR_MIB_EINSTIEG_ab_Gen3
 SG_ BAP_HUD_ASG_01_Header : 0|8@1+ (1.0,0.0) [0.0|255] ""  Gateway_Max

BO_ 2536702978 BAP_HUD_ASG_03: 8 OCU
 SG_ BAP_HUD_ASG_03_Header : 0|8@1+ (1,0) [0|255] "Unit_None"  Gateway_Max

BO_ 2536702992 BAP_HUD_FSG_01: 8 Gateway_Max
 SG_ BAP_HUD_FSG_01_Header : 0|8@1+ (1.0,0.0) [0.0|255] ""  OCU,ZR_MIB_EINSTIEG_ab_Gen3,ZR_MIB_OPTION_ab_Gen3,ZR_MIB_TOP_ab_Gen3

BO_ 2536709120 BAP_Hybrid_ASG_01: 8 ZR_MIB_EINSTIEG_ab_Gen3
 SG_ BAP_Hybrid_ASG_01_Header : 0|8@1+ (1.0,0.0) [0.0|255] ""  Gateway_Max

BO_ 2536709136 BAP_Hybrid_FSG_01: 8 Gateway_Max
 SG_ BAP_Hybrid_FSG_01_Header : 0|8@1+ (1.0,0.0) [0.0|255] ""  ZR_MIB_EINSTIEG_ab_Gen3,ZR_MIB_OPTION_ab_Gen3,ZR_MIB_TOP_ab_Gen3

BO_ 2536722944 BAP_IAA_PSO_ASG_01: 8 ZR_MIB_EINSTIEG_ab_Gen3
 SG_ BAP_IAA_PSO_ASG_01_Header : 0|8@1+ (1,0) [0|255] "Unit_None"  Gateway_Max,OCU

BO_ 2536722945 BAP_IAA_PSO_ASG_02: 8 Gateway_Max
 SG_ BAP_IAA_PSO_ASG_02_Header : 0|8@1+ (1,0) [0|255] "Unit_None"  OCU

BO_ 2536722946 BAP_IAA_PSO_ASG_03: 8 Gateway_Max
 SG_ BAP_IAA_PSO_ASG_03_Header : 0|8@1+ (1,0) [0|255] "Unit_None"  OCU

BO_ 2536722960 BAP_IAA_PSO_FSG_01: 8 Gateway_Max
 SG_ BAP_IAA_PSO_FSG_01_Header : 0|8@1+ (1,0) [0|255] "Unit_None"  Gateway_Max,ZR_MIB_EINSTIEG_ab_Gen3,ZR_MIB_OPTION_ab_Gen3,ZR_MIB_TOP_ab_Gen3

BO_ 2536722434 BAP_InfoSettings_ASG_03: 8 Gateway_Max
 SG_ BAP_InfoSettings_ASG_03_Header : 0|64@1+ (1.0,0.0) [0.0|18446744073709551615] ""  ZR_MIB_EINSTIEG_ab_Gen3,ZR_MIB_OPTION_ab_Gen3,ZR_MIB_TOP_ab_Gen3

BO_ 2536722448 BAP_InfoSettings_FSG_01: 8 ZR_MIB_EINSTIEG_ab_Gen3
 SG_ BAP_InfoSettings_FSG_01_Header : 0|8@1+ (1,0) [0|255] "Unit_None"  Gateway_Max,OCU

BO_ 2536704000 BAP_Innenlicht_ASG_01: 8 ZR_MIB_EINSTIEG_ab_Gen3
 SG_ BAP_Innenlicht_ASG_01_Header : 0|8@1+ (1.0,0.0) [0.0|255] ""  Gateway_Max

BO_ 2536704001 BAP_Innenlicht_ASG_02: 8 OCU
 SG_ BAP_Innenlicht_ASG_02_Header : 0|8@1+ (1,0) [0|255] "Unit_None"  Gateway_Max

BO_ 2536704016 BAP_Innenlicht_FSG_01: 8 Gateway_Max
 SG_ BAP_Innenlicht_FSG_01_Header : 0|8@1+ (1.0,0.0) [0.0|255] ""  OCU,ZR_MIB_EINSTIEG_ab_Gen3,ZR_MIB_OPTION_ab_Gen3,ZR_MIB_TOP_ab_Gen3

BO_ 2536702208 BAP_Klima1_ASG_01: 8 ZR_MIB_EINSTIEG_ab_Gen3
 SG_ BAP_Klima1_ASG_01_Header : 0|64@1+ (1.0,0.0) [0.0|18446744073709551615] ""  Gateway_Max

BO_ 2536702224 BAP_Klima1_FSG_01: 8 Gateway_Max
 SG_ BAP_Klima1_FSG_01_Header : 0|64@1+ (1.0,0.0) [0.0|18446744073709551615] ""  ZR_MIB_EINSTIEG_ab_Gen3,ZR_MIB_OPTION_ab_Gen3,ZR_MIB_TOP_ab_Gen3

BO_ 2536702464 BAP_Klima2_ASG_01: 8 ZR_MIB_EINSTIEG_ab_Gen3
 SG_ BAP_Klima2_ASG_01_Header : 0|64@1+ (1.0,0.0) [0.0|18446744073709551615] ""  Gateway_Max

BO_ 2536702480 BAP_Klima2_FSG_01: 8 Gateway_Max
 SG_ BAP_Klima2_FSG_01_Header : 0|8@1+ (1.0,0.0) [0.0|255] ""  ZR_MIB_EINSTIEG_ab_Gen3,ZR_MIB_OPTION_ab_Gen3,ZR_MIB_TOP_ab_Gen3

BO_ 2536718848 BAP_KlimaMaster_ASG_01: 8 ZR_MIB_EINSTIEG_ab_Gen3
 SG_ BAP_KlimaMaster_ASG_01_Header : 0|8@1+ (1,0) [0|255] "Unit_None"  Gateway_Max

BO_ 2536718849 BAP_KlimaMaster_ASG_02: 8 OCU
 SG_ BAP_KlimaMaster_ASG_02_Header : 0|8@1+ (1,0) [0|255] "Unit_None"  Gateway_Max

BO_ 2536718864 BAP_KlimaMaster_FSG_01: 8 Gateway_Max
 SG_ BAP_KlimaMaster_FSG_01_Header : 0|8@1+ (1,0) [0|255] "Unit_None"  OCU,ZR_MIB_EINSTIEG_ab_Gen3,ZR_MIB_OPTION_ab_Gen3,ZR_MIB_TOP_ab_Gen3

BO_ 2536708352 BAP_LDW_ASG_01: 8 ZR_MIB_EINSTIEG_ab_Gen3
 SG_ BAP_LDW_ASG_01_Header : 0|8@1+ (1.0,0.0) [0.0|255] ""  Gateway_Max

BO_ 2536708354 BAP_LDW_ASG_03: 8 OCU
 SG_ BAP_LDW_ASG_03_Header : 0|8@1+ (1,0) [0|255] "Unit_None"  Gateway_Max

BO_ 2536708368 BAP_LDW_FSG_01: 8 Gateway_Max
 SG_ BAP_LDW_FSG_01_Header : 0|8@1+ (1.0,0.0) [0.0|255] ""  OCU,ZR_MIB_EINSTIEG_ab_Gen3,ZR_MIB_OPTION_ab_Gen3,ZR_MIB_TOP_ab_Gen3

BO_ 2536715264 BAP_MFL_ASG_01: 8 Gateway_Max
 SG_ BAP_MFL_ASG_01_Header : 0|8@1+ (1.0,0.0) [0.0|255] ""  ZR_MIB_TOP_ab_Gen3

BO_ 2536715280 BAP_MFL_FSG_01: 8 ZR_MIB_TOP_ab_Gen3
 SG_ BAP_MFL_FSG_01_Header : 0|8@1+ (1.0,0.0) [0.0|255] ""  Gateway_Max

BO_ 2536705536 BAP_Mirror_ASG_01: 8 ZR_MIB_EINSTIEG_ab_Gen3
 SG_ BAP_Mirror_ASG_01_Header : 0|8@1+ (1.0,0.0) [0.0|255] ""  Gateway_Max

BO_ 2536705537 BAP_Mirror_ASG_02: 8 OCU
 SG_ BAP_Mirror_ASG_02_Header : 0|8@1+ (1,0) [0|255] "Unit_None"  Gateway_Max

BO_ 2536705552 BAP_Mirror_FSG_01: 8 Gateway_Max
 SG_ BAP_Mirror_FSG_01_Header : 0|8@1+ (1.0,0.0) [0.0|255] ""  OCU,ZR_MIB_EINSTIEG_ab_Gen3,ZR_MIB_OPTION_ab_Gen3,ZR_MIB_TOP_ab_Gen3

BO_ 2536710656 BAP_MKE_ASG_01: 8 ZR_MIB_EINSTIEG_ab_Gen3
 SG_ BAP_MKE_ASG_01_Header : 0|8@1+ (1.0,0.0) [0.0|255] ""  Gateway_Max

BO_ 2536710672 BAP_MKE_FSG_01: 8 Gateway_Max
 SG_ BAP_MKE_FSG_01_Header : 0|8@1+ (1.0,0.0) [0.0|255] ""  ZR_MIB_EINSTIEG_ab_Gen3,ZR_MIB_OPTION_ab_Gen3,ZR_MIB_TOP_ab_Gen3

BO_ 2536732416 BAP_MobDevKey_ASG_01: 8 ZR_MIB_OPTION_ab_Gen3
 SG_ BAP_MobDevKey_ASG_01_Header : 0|64@1+ (1.0,0.0) [0.0|18446744073709551615] ""  Gateway_Max

BO_ 2536732417 BAP_MobDevKey_ASG_02: 8 OCU
 SG_ BAP_MobDevKey_ASG_02_Header : 0|64@1+ (1.0,0.0) [0.0|18446744073709551615] ""  Gateway_Max

BO_ 2536732432 BAP_MobDevKey_FSG_01: 8 Gateway_Max
 SG_ BAP_MobDevKey_FSG_01_Header : 0|64@1+ (1.0,0.0) [0.0|18446744073709551615] ""  OCU,ZR_MIB_OPTION_ab_Gen3

BO_ 2536734464 BAP_MobDevKeyOnline_ASG_01: 8 Gateway_Max
 SG_ BAP_MobDevKeyOnline_ASG_01_Heade : 0|64@1+ (1.0,0.0) [0.0|18446744073709551615] ""  OCU

BO_ 2536734480 BAP_MobDevKeyOnline_FSG_01: 8 OCU
 SG_ BAP_MobDevKeyOnline_FSG_01_Heade : 0|64@1+ (1.0,0.0) [0.0|18446744073709551615] ""  Gateway_Max

BO_ 2536714752 BAP_Navigation_ASG_01: 8 Gateway_Max
 SG_ BAP_Navigation_ASG_01_Header : 0|8@1+ (1.0,0.0) [0.0|255] ""  ZR_MIB_EINSTIEG_ab_Gen3,ZR_MIB_OPTION_ab_Gen3,ZR_MIB_TOP_ab_Gen3

BO_ 2536714753 BAP_Navigation_ASG_02: 8 Gateway_Max
 SG_ BAP_Navigation_ASG_02_Header : 0|8@1+ (1.0,0.0) [0.0|255] ""  ZR_MIB_EINSTIEG_ab_Gen3,ZR_MIB_OPTION_ab_Gen3,ZR_MIB_TOP_ab_Gen3

BO_ 2536714754 BAP_Navigation_ASG_03: 8 Gateway_Max
 SG_ BAP_Navigation_ASG_03_Header : 0|8@1+ (1.0,0.0) [0.0|255] ""  ZR_MIB_EINSTIEG_ab_Gen3,ZR_MIB_OPTION_ab_Gen3,ZR_MIB_TOP_ab_Gen3

BO_ 2536714755 BAP_Navigation_ASG_04: 8 Gateway_Max
 SG_ BAP_Navigation_ASG_04_Header : 0|8@1+ (1.0,0.0) [0.0|255] ""  ZR_MIB_EINSTIEG_ab_Gen3,ZR_MIB_OPTION_ab_Gen3,ZR_MIB_TOP_ab_Gen3

BO_ 2536714768 BAP_Navigation_FSG_01: 8 ZR_MIB_EINSTIEG_ab_Gen3
 SG_ BAP_Navigation_FSG_01_Header : 0|8@1+ (1.0,0.0) [0.0|255] ""  Gateway_Max

BO_ 2536714769 BAP_Navigation_FSG_02: 8 ZR_MIB_EINSTIEG_ab_Gen3
 SG_ BAP_Navigation_FSG_02_Header : 0|8@1+ (1.0,0.0) [0.0|255] ""  Gateway_Max

BO_ 2536712704 BAP_OnlineFunction_ASG_01: 8 Gateway_Max
 SG_ BAP_OnlineFunction_ASG_01_Header : 0|8@1+ (1,0) [0|255] "Unit_None"  ZR_MIB_OPTION_ab_Gen3,ZR_MIB_TOP_ab_Gen3

BO_ 2536712705 BAP_OnlineFunction_ASG_02: 8 Gateway_Max
 SG_ BAP_OnlineFunction_ASG_02_Header : 0|8@1+ (1,0) [0|255] "Unit_None"  ZR_MIB_OPTION_ab_Gen3,ZR_MIB_TOP_ab_Gen3

BO_ 2536712720 BAP_OnlineFunction_FSG_01: 8 ZR_MIB_OPTION_ab_Gen3
 SG_ BAP_OnlineFunction_FSG_01_Header : 0|8@1+ (1,0) [0|255] "Unit_None"  Gateway_Max

BO_ 2536704512 BAP_OPS_ASG_01: 8 ZR_MIB_EINSTIEG_ab_Gen3
 SG_ BAP_OPS_ASG_01_Header : 0|8@1+ (1.0,0.0) [0.0|255] ""  Gateway_Max

BO_ 2536704516 BAP_OPS_ASG_05: 8 OCU
 SG_ BAP_OPS_ASG_05_Header : 0|8@1+ (1,0) [0|255] "Unit_None"  Gateway_Max

BO_ 2536704528 BAP_OPS_FSG_01: 8 Gateway_Max
 SG_ BAP_OPS_FSG_01_Header : 0|8@1+ (1.0,0.0) [0.0|255] ""  OCU,ZR_MIB_EINSTIEG_ab_Gen3,ZR_MIB_OPTION_ab_Gen3,ZR_MIB_TOP_ab_Gen3

BO_ 2536704529 BAP_OPS_FSG_02: 8 Gateway_Max
 SG_ BAP_OPS_FSG_02_Header : 0|8@1+ (1.0,0.0) [0.0|255] ""  OCU,ZR_MIB_EINSTIEG_ab_Gen3,ZR_MIB_OPTION_ab_Gen3,ZR_MIB_TOP_ab_Gen3

BO_ 2536723712 BAP_PaCo_ASG_01: 8 ZR_MIB_EINSTIEG_ab_Gen3
 SG_ BAP_PaCo_ASG_01_Header : 0|8@1+ (1,0) [0|255] "Unit_None"  Gateway_Max

BO_ 2536723714 BAP_PaCo_ASG_03: 8 OCU
 SG_ BAP_PaCo_ASG_03_Header : 0|64@1+ (1.0,0.0) [0.0|18446744073709551615] ""  Gateway_Max

BO_ 2536723728 BAP_PaCo_FSG_01: 8 Gateway_Max
 SG_ BAP_PaCo_FSG_01_Header : 0|8@1+ (1,0) [0|255] "Unit_None"  OCU,ZR_MIB_EINSTIEG_ab_Gen3,ZR_MIB_OPTION_ab_Gen3,ZR_MIB_TOP_ab_Gen3

BO_ 2536702720 BAP_ParkHeater_ASG_01: 8 ZR_MIB_EINSTIEG_ab_Gen3
 SG_ BAP_ParkHeater_ASG_01_Header : 0|8@1+ (1.0,0.0) [0.0|255] ""  Gateway_Max

BO_ 2536702721 BAP_ParkHeater_ASG_02: 8 OCU
 SG_ BAP_ParkHeater_ASG_02_Header : 0|8@1+ (1.0,0.0) [0.0|255] ""  Gateway_Max

BO_ 2536702736 BAP_ParkHeater_FSG_01: 8 Gateway_Max
 SG_ BAP_ParkHeater_FSG_01_Header : 0|8@1+ (1.0,0.0) [0.0|255] ""  OCU,ZR_MIB_EINSTIEG_ab_Gen3,ZR_MIB_OPTION_ab_Gen3,ZR_MIB_TOP_ab_Gen3

BO_ 2536734721 BAP_PlugAndCharge_ASG_02: 8 ZR_MIB_EINSTIEG_ab_Gen3
 SG_ BAP_PlugAndCharge_ASG_02_Header : 0|64@1+ (1.0,0.0) [0.0|18446744073709551615] ""  Gateway_Max

BO_ 2536734737 BAP_PlugAndCharge_FSG_02: 8 Gateway_Max
 SG_ BAP_PlugAndCharge_FSG_02_Header : 0|64@1+ (1.0,0.0) [0.0|18446744073709551615] ""  ZR_MIB_EINSTIEG_ab_Gen3,ZR_MIB_OPTION_ab_Gen3,ZR_MIB_TOP_ab_Gen3

BO_ 2536716544 BAP_RangeData_ASG_01: 8 ZR_MIB_TOP_ab_Gen3
 SG_ BAP_RangeData_ASG_01_Header : 0|8@1+ (1.0,0.0) [0.0|255] ""  Gateway_Max

BO_ 2536716560 BAP_RangeData_FSG_01: 8 Gateway_Max
 SG_ BAP_RangeData_FSG_01_Header : 0|8@1+ (1.0,0.0) [0.0|255] ""  ZR_MIB_TOP_ab_Gen3

BO_ 2536703744 BAP_RDK_ASG_01: 8 ZR_MIB_EINSTIEG_ab_Gen3
 SG_ BAP_RDK_ASG_01_Header : 0|8@1+ (1.0,0.0) [0.0|255] ""  Gateway_Max,RDK_RS3

BO_ 2536703745 BAP_RDK_ASG_02: 8 Gateway_Max
 SG_ BAP_RDK_ASG_02_Header : 0|8@1+ (1.0,0.0) [0.0|255] ""  RDK_RS3

BO_ 2536703760 BAP_RDK_FSG_01: 8 Gateway_Max
 SG_ BAP_RDK_FSG_01_Header : 0|8@1+ (1.0,0.0) [0.0|255] ""  Gateway_Max,ZR_MIB_EINSTIEG_ab_Gen3,ZR_MIB_OPTION_ab_Gen3,ZR_MIB_TOP_ab_Gen3

BO_ 2536728320 BAP_REM2_ASG_01: 8 OCU
 SG_ BAP_REM2_ASG_01_Header : 0|64@1+ (1.0,0.0) [0.0|18446744073709551615] ""  Gateway_Max

BO_ 2536728336 BAP_REM2_FSG_01: 8 Gateway_Max
 SG_ BAP_REM2_FSG_01_Header : 0|64@1+ (1.0,0.0) [0.0|18446744073709551615] ""  OCU

BO_ 2536728337 BAP_REM2_FSG_02: 8 Gateway_Max
 SG_ BAP_REM2_FSG_02_Header : 0|64@1+ (1.0,0.0) [0.0|18446744073709551615] ""  OCU

BO_ 2536725248 BAP_REM_ASG_01: 8 OCU
 SG_ BAP_REM_ASG_01_Header : 0|8@1+ (1,0) [0|255] "Unit_None"  Gateway_Max

BO_ 2536725264 BAP_REM_FSG_01: 8 Gateway_Max
 SG_ BAP_REM_FSG_01_Header : 0|8@1+ (1,0) [0|255] "Unit_None"  OCU

BO_ 2536725265 BAP_REM_FSG_02: 8 Gateway_Max
 SG_ BAP_REM_FSG_02_Header : 0|8@1+ (1,0) [0|255] "Unit_None"  OCU

BO_ 2536721920 BAP_RemoteServices_ASG_01: 8 OCU
 SG_ BAP_RemoteServices_ASG_01_Header : 0|8@1+ (1,0) [0|255] "Unit_None"  Gateway_Max

BO_ 2536721921 BAP_RemoteServices_ASG_02: 8 ZR_MIB_EINSTIEG_ab_Gen3
 SG_ BAP_RemoteServices_ASG_02_Header : 0|8@1+ (1,0) [0|255] "Unit_None"  Gateway_Max

BO_ 2536721936 BAP_RemoteServices_FSG_01: 8 Gateway_Max
 SG_ BAP_RemoteServices_FSG_01_Header : 0|8@1+ (1,0) [0|255] "Unit_None"  OCU,ZR_MIB_EINSTIEG_ab_Gen3,ZR_MIB_OPTION_ab_Gen3,ZR_MIB_TOP_ab_Gen3

BO_ 2536731904 BAP_RollingAbility_ASG_01: 8 ZR_MIB_EINSTIEG_ab_Gen3
 SG_ BAP_RollingAbility_ASG_01_Header : 0|64@1+ (1.0,0.0) [0.0|18446744073709551615] ""  Gateway_Max

BO_ 2536731920 BAP_RollingAbility_FSG_01: 8 Gateway_Max
 SG_ BAP_RollingAbility_FSG_01_Header : 0|64@1+ (1.0,0.0) [0.0|18446744073709551615] ""  ZR_MIB_EINSTIEG_ab_Gen3,ZR_MIB_OPTION_ab_Gen3,ZR_MIB_TOP_ab_Gen3

BO_ 2536730624 BAP_RSO_ASG_01: 8 OCU
 SG_ BAP_RSO_ASG_01_Header : 0|64@1+ (1.0,0.0) [0.0|18446744073709551615] ""  Gateway_Max

BO_ 2536730640 BAP_RSO_FSG_01: 8 Gateway_Max
 SG_ BAP_RSO_FSG_01_Header : 0|64@1+ (1.0,0.0) [0.0|18446744073709551615] ""  OCU

BO_ 2536704768 BAP_RVC_ASG_01: 8 ZR_MIB_EINSTIEG_ab_Gen3
 SG_ BAP_RVC_ASG_01_Header : 0|64@1+ (1.0,0.0) [0.0|18446744073709551615] ""  Gateway_Max

BO_ 2536704784 BAP_RVC_FSG_01: 8 Gateway_Max
 SG_ BAP_RVC_FSG_01_Header : 0|8@1+ (1.0,0.0) [0.0|255] ""  ZR_MIB_EINSTIEG_ab_Gen3,ZR_MIB_OPTION_ab_Gen3,ZR_MIB_TOP_ab_Gen3

BO_ 2536719872 BAP_SDS_ASG_01: 8 Gateway_Max
 SG_ BAP_SDS_ASG_01_Header : 0|8@1+ (1,0) [0|255] "Unit_None"  Vector__XXX

BO_ 2536719888 BAP_SDS_FSG_01: 8 Vector__XXX
 SG_ BAP_SDS_FSG_01_Header : 0|8@1+ (1,0) [0|255] "Unit_None"  Gateway_Max

BO_ 2536717056 BAP_SeatPneumatic_ASG_01: 8 ZR_MIB_EINSTIEG_ab_Gen3
 SG_ BAP_SeatPneumatic_ASG_01_Header : 0|8@1+ (1.0,0.0) [0.0|255] ""  Gateway_Max

BO_ 2536717057 BAP_SeatPneumatic_ASG_02: 8 OCU
 SG_ BAP_SeatPneumatic_ASG_02_Header : 0|64@1+ (1.0,0.0) [0.0|18446744073709551615] ""  Gateway_Max

BO_ 2536717072 BAP_SeatPneumatic_FSG_01: 8 Gateway_Max
 SG_ BAP_SeatPneumatic_FSG_01_Header : 0|8@1+ (1.0,0.0) [0.0|255] ""  OCU,ZR_MIB_EINSTIEG_ab_Gen3,ZR_MIB_OPTION_ab_Gen3,ZR_MIB_TOP_ab_Gen3

BO_ 2536735488 BAP_SecEvents2_ASG_01: 8 Gateway_Max
 SG_ BAP_SecEvents2_ASG_01_Header : 0|64@1+ (1.0,0.0) [0.0|18446744073709551615] ""  ZR_MIB_EINSTIEG_ab_Gen3,ZR_MIB_OPTION_ab_Gen3

BO_TX_BU_ 2589283936 :Gateway_Max,ZR_MIB_OPTION_ab_Gen3;
BO_TX_BU_ 2589283937 :Gateway_Max,ZR_MIB_OPTION_ab_Gen3;
BO_TX_BU_ 2589283938 :Gateway_Max,ZR_MIB_OPTION_ab_Gen3;
BO_TX_BU_ 2589283939 :Gateway_Max,ZR_MIB_OPTION_ab_Gen3;
BO_TX_BU_ 2589283940 :Gateway_Max,ZR_MIB_OPTION_ab_Gen3;
BO_TX_BU_ 2550012007 :ConMod_CD,OCU;
BO_TX_BU_ 2536703232 :ZR_MIB_EINSTIEG_ab_Gen3,ZR_MIB_OPTION_ab_Gen3,ZR_MIB_TOP_ab_Gen3;
BO_TX_BU_ 2536714512 :ZR_MIB_EINSTIEG_ab_Gen3,ZR_MIB_OPTION_ab_Gen3,ZR_MIB_TOP_ab_Gen3;
BO_TX_BU_ 2536714513 :ZR_MIB_EINSTIEG_ab_Gen3,ZR_MIB_OPTION_ab_Gen3,ZR_MIB_TOP_ab_Gen3;
BO_TX_BU_ 2536704256 :ZR_MIB_EINSTIEG_ab_Gen3,ZR_MIB_OPTION_ab_Gen3,ZR_MIB_TOP_ab_Gen3;
BO_TX_BU_ 2536708864 :ZR_MIB_EINSTIEG_ab_Gen3,ZR_MIB_OPTION_ab_Gen3,ZR_MIB_TOP_ab_Gen3;
BO_TX_BU_ 2536711424 :ZR_MIB_EINSTIEG_ab_Gen3,ZR_MIB_OPTION_ab_Gen3,ZR_MIB_TOP_ab_Gen3;
BO_TX_BU_ 2536705792 :ZR_MIB_EINSTIEG_ab_Gen3,ZR_MIB_OPTION_ab_Gen3,ZR_MIB_TOP_ab_Gen3;
BO_TX_BU_ 2536710913 :ZR_MIB_EINSTIEG_ab_Gen3,ZR_MIB_OPTION_ab_Gen3,ZR_MIB_TOP_ab_Gen3;
BO_TX_BU_ 2536711680 :ZR_MIB_EINSTIEG_ab_Gen3,ZR_MIB_OPTION_ab_Gen3,ZR_MIB_TOP_ab_Gen3;
BO_TX_BU_ 2536733184 :ZR_MIB_EINSTIEG_ab_Gen3,ZR_MIB_OPTION_ab_Gen3;
BO_TX_BU_ 2536733440 :ZR_MIB_EINSTIEG_ab_Gen3,ZR_MIB_OPTION_ab_Gen3;
BO_TX_BU_ 2536732160 :ZR_MIB_EINSTIEG_ab_Gen3,ZR_MIB_OPTION_ab_Gen3;
BO_TX_BU_ 2536734976 :ZR_MIB_EINSTIEG_ab_Gen3,ZR_MIB_OPTION_ab_Gen3;
BO_TX_BU_ 2536726786 :ZR_MIB_EINSTIEG_ab_Gen3,ZR_MIB_OPTION_ab_Gen3;
BO_TX_BU_ 2536707840 :ZR_MIB_EINSTIEG_ab_Gen3,ZR_MIB_OPTION_ab_Gen3,ZR_MIB_TOP_ab_Gen3;
BO_TX_BU_ 2536726528 :ZR_MIB_EINSTIEG_ab_Gen3,ZR_MIB_OPTION_ab_Gen3;
BO_TX_BU_ 2536767280 :Gateway_Max,OCU,RDK_RS3,ZR_MIB_EINSTIEG_ab_Gen3,ZR_MIB_OPTION_ab_Gen3,ZR_MIB_TOP_ab_Gen3;
BO_TX_BU_ 2536705280 :ZR_MIB_EINSTIEG_ab_Gen3,ZR_MIB_OPTION_ab_Gen3,ZR_MIB_TOP_ab_Gen3;
BO_TX_BU_ 2536715008 :Gateway_Max,ZR_MIB_EINSTIEG_ab_Gen3,ZR_MIB_OPTION_ab_Gen3,ZR_MIB_TOP_ab_Gen3;
BO_TX_BU_ 2536715024 :Gateway_Max,OCU;
BO_TX_BU_ 2536717312 :ZR_MIB_EINSTIEG_ab_Gen3,ZR_MIB_OPTION_ab_Gen3,ZR_MIB_TOP_ab_Gen3;
BO_TX_BU_ 2536706816 :ZR_MIB_EINSTIEG_ab_Gen3,ZR_MIB_OPTION_ab_Gen3,ZR_MIB_TOP_ab_Gen3;
BO_TX_BU_ 2536725760 :ZR_MIB_EINSTIEG_ab_Gen3,ZR_MIB_OPTION_ab_Gen3,ZR_MIB_TOP_ab_Gen3;
BO_TX_BU_ 2536724480 :ZR_MIB_EINSTIEG_ab_Gen3,ZR_MIB_OPTION_ab_Gen3,ZR_MIB_TOP_ab_Gen3;
BO_TX_BU_ 2536724481 :ZR_MIB_EINSTIEG_ab_Gen3,ZR_MIB_OPTION_ab_Gen3,ZR_MIB_TOP_ab_Gen3;
BO_TX_BU_ 2536716032 :ZR_MIB_EINSTIEG_ab_Gen3,ZR_MIB_OPTION_ab_Gen3,ZR_MIB_TOP_ab_Gen3;
BO_TX_BU_ 2536716033 :ZR_MIB_EINSTIEG_ab_Gen3,ZR_MIB_OPTION_ab_Gen3,ZR_MIB_TOP_ab_Gen3;
BO_TX_BU_ 2536716048 :Gateway_Max,OCU;
BO_TX_BU_ 2536716049 :Gateway_Max,OCU;
BO_TX_BU_ 2536721664 :ZR_MIB_EINSTIEG_ab_Gen3,ZR_MIB_OPTION_ab_Gen3,ZR_MIB_TOP_ab_Gen3;
BO_TX_BU_ 2536702976 :ZR_MIB_EINSTIEG_ab_Gen3,ZR_MIB_OPTION_ab_Gen3,ZR_MIB_TOP_ab_Gen3;
BO_TX_BU_ 2536709120 :ZR_MIB_EINSTIEG_ab_Gen3,ZR_MIB_OPTION_ab_Gen3,ZR_MIB_TOP_ab_Gen3;
BO_TX_BU_ 2536722944 :ZR_MIB_EINSTIEG_ab_Gen3,ZR_MIB_OPTION_ab_Gen3,ZR_MIB_TOP_ab_Gen3;
BO_TX_BU_ 2536722960 :Gateway_Max,OCU;
BO_TX_BU_ 2536722434 :Gateway_Max,OCU;
BO_TX_BU_ 2536722448 :ZR_MIB_EINSTIEG_ab_Gen3,ZR_MIB_OPTION_ab_Gen3,ZR_MIB_TOP_ab_Gen3;
BO_TX_BU_ 2536704000 :ZR_MIB_EINSTIEG_ab_Gen3,ZR_MIB_OPTION_ab_Gen3,ZR_MIB_TOP_ab_Gen3;
BO_TX_BU_ 2536702208 :ZR_MIB_EINSTIEG_ab_Gen3,ZR_MIB_OPTION_ab_Gen3,ZR_MIB_TOP_ab_Gen3;
BO_TX_BU_ 2536702464 :ZR_MIB_EINSTIEG_ab_Gen3,ZR_MIB_OPTION_ab_Gen3,ZR_MIB_TOP_ab_Gen3;
BO_TX_BU_ 2536718848 :ZR_MIB_EINSTIEG_ab_Gen3,ZR_MIB_OPTION_ab_Gen3,ZR_MIB_TOP_ab_Gen3;
BO_TX_BU_ 2536708352 :ZR_MIB_EINSTIEG_ab_Gen3,ZR_MIB_OPTION_ab_Gen3,ZR_MIB_TOP_ab_Gen3;
BO_TX_BU_ 2536705536 :ZR_MIB_EINSTIEG_ab_Gen3,ZR_MIB_OPTION_ab_Gen3,ZR_MIB_TOP_ab_Gen3;
BO_TX_BU_ 2536710656 :ZR_MIB_EINSTIEG_ab_Gen3,ZR_MIB_OPTION_ab_Gen3,ZR_MIB_TOP_ab_Gen3;
BO_TX_BU_ 2536714768 :ZR_MIB_EINSTIEG_ab_Gen3,ZR_MIB_OPTION_ab_Gen3,ZR_MIB_TOP_ab_Gen3;
BO_TX_BU_ 2536714769 :ZR_MIB_EINSTIEG_ab_Gen3,ZR_MIB_OPTION_ab_Gen3,ZR_MIB_TOP_ab_Gen3;
BO_TX_BU_ 2536712720 :ZR_MIB_OPTION_ab_Gen3,ZR_MIB_TOP_ab_Gen3;
BO_TX_BU_ 2536704512 :ZR_MIB_EINSTIEG_ab_Gen3,ZR_MIB_OPTION_ab_Gen3,ZR_MIB_TOP_ab_Gen3;
BO_TX_BU_ 2536723712 :ZR_MIB_EINSTIEG_ab_Gen3,ZR_MIB_OPTION_ab_Gen3,ZR_MIB_TOP_ab_Gen3;
BO_TX_BU_ 2536702720 :ZR_MIB_EINSTIEG_ab_Gen3,ZR_MIB_OPTION_ab_Gen3,ZR_MIB_TOP_ab_Gen3;
BO_TX_BU_ 2536734721 :ZR_MIB_EINSTIEG_ab_Gen3,ZR_MIB_OPTION_ab_Gen3,ZR_MIB_TOP_ab_Gen3;
BO_TX_BU_ 2536703744 :ZR_MIB_EINSTIEG_ab_Gen3,ZR_MIB_OPTION_ab_Gen3,ZR_MIB_TOP_ab_Gen3;
BO_TX_BU_ 2536703760 :Gateway_Max,RDK_RS3;
BO_TX_BU_ 2536721921 :ZR_MIB_EINSTIEG_ab_Gen3,ZR_MIB_OPTION_ab_Gen3,ZR_MIB_TOP_ab_Gen3;
BO_TX_BU_ 2536731904 :ZR_MIB_EINSTIEG_ab_Gen3,ZR_MIB_OPTION_ab_Gen3,ZR_MIB_TOP_ab_Gen3;
BO_TX_BU_ 2536704768 :ZR_MIB_EINSTIEG_ab_Gen3,ZR_MIB_OPTION_ab_Gen3,ZR_MIB_TOP_ab_Gen3;
BO_TX_BU_ 2536717056 :ZR_MIB_EINSTIEG_ab_Gen3,ZR_MIB_OPTION_ab_Gen3,ZR_MIB_TOP_ab_Gen3;
BO_TX_BU_ 2536735488 :Gateway_Max,OCU;

CM_ "ICANHS_V14.09F Generated by BusNet_NG_Produktiv 9.25.5";
CM_ BU_ BedienDisp_mi "ist FES 2.0 ";
CM_ BU_ ConMod_CD "DFL Kürzel: eCall";
CM_ BU_ DashCAM "DFL-Kürzel: DCAM
im MIB3 OI an ETH Switch Port 4";
CM_ BU_ ICC_IO_Node "DFL-Kürzel: Info_El

Hat CAN und ETH";
CM_ BU_ LSH "Das LSH ist die Luftzusatz Standheizung für den Crafter NF basierend auf MQB";
CM_ BU_ OCU "OCU im MQB2020";
CM_ BU_ RDK_RS3 "Reifen-Druck-Kontrolle MQBw_Baseline";
CM_ BU_ Sound_MIB_ab_Gen3 "Soundverstärker ab MIB3";
CM_ BU_ STH "Standheizung im MQB2020";
CM_ BU_ ZR_MIB_EINSTIEG_ab_Gen3 "Einstiegsinfotainment ab MIB Generation 3";
CM_ BU_ ZR_MIB_OPTION_ab_Gen3 "Zentralrechner ab MIB3";

CM_ BO_ 1660 "MLBevo";
CM_ BO_ 1633 "ab MQB 7.2";
CM_ BO_ 2536717312 "BAP ASG message EfficiencyAssist (PEA)<br>
Sender: HU (MIB)
Receiver: MSG";
CM_ BO_ 2536717328 "BAP FSG message EfficiencyAssist (PEA)<br>
Sender: MSG<br>
Receiver: HU (MIB)";

CM_ SG_ 2589283936 AC_FES_Atmosphere_AMB_RGB_1 "Signalwert enthält den RGB Vorauswahl-Farbwert für die jeweilige FES Profilposition.
....._RGB_1 = Vorauswahl Farbwert für FES Profilposition 1
....._RGB_2 = Vorauswahl Farbwert für FES Profilposition 2
....";
CM_ SG_ 2589283936 AC_FES_Atmosphere_AMB_RGB_2 "Signalwert enthält den RGB Vorauswahl-Farbwert für die jeweilige FES Profilposition.
....._RGB_1 = Vorauswahl Farbwert für FES Profilposition 1
....._RGB_2 = Vorauswahl Farbwert für FES Profilposition 2
....";

CM_ SG_ 2589283937 AC_FES_Atmosphere_AMB_RGB_3 "Signalwert enthält den RGB Vorauswahl-Farbwert für die jeweilige FES Profilposition.
....._RGB_1 = Vorauswahl Farbwert für FES Profilposition 1
....._RGB_2 = Vorauswahl Farbwert für FES Profilposition 2
....";
CM_ SG_ 2589283937 AC_FES_Atmosphere_AMB_RGB_4 "Signalwert enthält den RGB Vorauswahl-Farbwert für die jeweilige FES Profilposition.
....._RGB_1 = Vorauswahl Farbwert für FES Profilposition 1
....._RGB_2 = Vorauswahl Farbwert für FES Profilposition 2
....";

CM_ SG_ 2589283938 AC_FES_Atmosphere_AMB_RGB_5 "Signalwert enthält den RGB Vorauswahl-Farbwert für die jeweilige FES Profilposition.
....._RGB_1 = Vorauswahl Farbwert für FES Profilposition 1
....._RGB_2 = Vorauswahl Farbwert für FES Profilposition 2
....";
CM_ SG_ 2589283938 AC_FES_Atmosphere_AMB_RGB_6 "Signalwert enthält den RGB Vorauswahl-Farbwert für die jeweilige FES Profilposition.
....._RGB_1 = Vorauswahl Farbwert für FES Profilposition 1
....._RGB_2 = Vorauswahl Farbwert für FES Profilposition 2
....";

CM_ SG_ 2589283939 AC_FES_Atmosphere_AMB_RGB_7 "Signalwert enthält den RGB Vorauswahl-Farbwert für die jeweilige FES Profilposition.
....._RGB_1 = Vorauswahl Farbwert für FES Profilposition 1
....._RGB_2 = Vorauswahl Farbwert für FES Profilposition 2
....";
CM_ SG_ 2589283939 LC_FES_Aktive_Ebene_SOLL "Gibt die im Fahrerlebnisschalter zu setzende Bedienebne z.B. FPA,  ATMOSPHERES,... vor";
CM_ SG_ 2589283939 LC_FES_Viewmode "Gibt die im Fahrerlebnisschalter zu setzenden Anzeige-Modus z.B. SELECTION oder IDLE vor";

CM_ SG_ 2589283940 AC_FES_Aktive_Atmosphere "Signal enthält die  ID des aktiven Atmosphere-Soll-Profils";
CM_ SG_ 2589283940 AC_FES_Atmosphere_1 "Signal enthält die ATMosphere Profil-ID, die auf der jeweiligen Fahrerlebnisschalter-Position  gezeigt werden soll.";
CM_ SG_ 2589283940 AC_FES_Atmosphere_2 "Signal enthält die ATMosphere Profil-ID, die auf der jeweiligen Fahrerlebnisschalter-Position  gezeigt werden soll.";
CM_ SG_ 2589283940 AC_FES_Atmosphere_3 "Signal enthält die ATMosphere Profil-ID, die auf der jeweiligen Fahrerlebnisschalter-Position  gezeigt werden soll.";
CM_ SG_ 2589283940 AC_FES_Atmosphere_4 "Signal enthält die ATMosphere Profil-ID, die auf der jeweiligen Fahrerlebnisschalter-Position  gezeigt werden soll.";
CM_ SG_ 2589283940 AC_FES_Atmosphere_5 "Signal enthält die ATMosphere Profil-ID, die auf der jeweiligen Fahrerlebnisschalter-Position  gezeigt werden soll.";
CM_ SG_ 2589283940 AC_FES_Atmosphere_6 "Signal enthält die ATMosphere Profil-ID, die auf der jeweiligen Fahrerlebnisschalter-Position  gezeigt werden soll.";
CM_ SG_ 2589283940 AC_FES_Atmosphere_7 "Signal enthält die ATMosphere Profil-ID, die auf der jeweiligen Fahrerlebnisschalter-Position  gezeigt werden soll.";
CM_ SG_ 2589283940 AC_KBI_Sec_View_Request "Von ATM angeforderter Anzeigezustand der Nebenanzeigen im Kombiinstrument";
CM_ SG_ 2589283940 AC_KBI_View_Request "Vom Atmospheres Controller beim Kombi angeforderter View";

CM_ SG_ 680 AbstWarn_LRR_FAS_Fkt_Status "Rückmeldung des Funktionsstatus an FAS ProfileMaster";
CM_ SG_ 680 ACA_Hinweistexte "Anzeigesignal für Hinweise zur Fahrerbedienenhandlung";
CM_ SG_ 680 ACA_Querfuehrung_Texte "Signal zur Ansteuerung von Fahrerhinweisen der Querführung in ACA im Mitteldisplay";
CM_ SG_ 680 ACC_Abstand_Abstandswarner "Signal dient zur Anzeige des Abstands im Kombi
Hinweis: das Signal ist mit dem Signal ACC_Einheit_Abstandswarner zu interpretieren";
CM_ SG_ 680 ACC_Akustik_03 "Ansteuerung der zugehörigen Akustik im Kombiinstrument, solange die entsprechende Bitkombination gesetzt ist.";
CM_ SG_ 680 ACC_Einheit_Abstandswarner "Einheit zu Signal ACC_Abstand_Abstandswarner";
CM_ SG_ 680 ACC_FoD_Status "Informiert den TSK und Kombi, ob die ACC-Funktion freigeschaltet ist oder nicht.";
CM_ SG_ 680 ACC_Geschw_Zielfahrzeug "Nur Porsche E2 und Bentley BY636: Zur grafischen Darstellung der Geschwindigkeit eines im ACC Regelbetrieb erkannten Zielobjektes bzw, vorausfahrenden Objektes. ACC ermittelt nach der Vorschrift: Vom Kombi eingelesene 'angezeigte Geschwindigkeit' plus TO_";
CM_ SG_ 680 ACC_STA_Text "ACC_STA_Text wird gesendet wenn aktiv regelt.";
CM_ SG_ 680 ACC_Status_Anzeige "Status nur zur Defintion von Anzeige im Kombi. Hinweis: Wird für die spez. VW-Anzeige (überlappende Anzeigebereiche) verwendet. Vom AUDI-ACC im Rahmen der Modulstrategie zu bedienen.";
CM_ SG_ 680 ACC_Status_Stauende "Information, ob ACC auf ein Stauende auf Basis von Car2X reagiert.";
CM_ SG_ 680 ACC_Texte_02 "Zusätzliches Signal zu 'ACC_Texte_Primaeranz', welches Warnungen und Fahrerhinweise bzgl. ACC im Mitteldisplay des Kombis anzeigt.";
CM_ SG_ 680 ACC_Texte_Abstandswarner "Signal zur Ansteuerung von Fahrer- und Warnhinweisen des Abstandswarners im Mitteldisplay";
CM_ SG_ 680 ACC_Texte_Sekundaeranz "Textdefinitionen für Anzeige ACC, Tempolimitassistent und Kurvenassistent";
CM_ SG_ 680 ACC_Vorz_Abstandswarner "Vorzeichen der Abstandsanzeige und -warnung";
CM_ SG_ 680 ACC_Zeitluecke_Abstandswarner "Anzeige der aktuellen Zeitluecke zum vorausfahrenden Fahrzeug";
CM_ SG_ 680 FAS_Licht_Anf "Anforderung zum Einschalten des Assistenzfahrlicht";
CM_ SG_ 680 STA_Texte "Signal, welches Warnungen und Fahrerhinweise bzgl. der Funktion STA im Kombi anzeigt";
CM_ SG_ 680 STA_Zusatzanz "Für Anzeigen der STA-Funktion im Mitteldisplay";

CM_ SG_ 1660 AGA_Charisma_FahrPr "MLBevo: Aktuelles Fahrprogramm des Charisma-Teilnehmers (siehe Systemlastenheft Drive Select)
MQB: Istwert der Kennlinie (siehe Systemlastenheft MQB FPA)";
CM_ SG_ 1660 AGA_Charisma_Status "Rückmeldung an den Charisma-Master

Wert 0x3 ist nur für Fahrzeuge ab MQB relevant";
CM_ SG_ 1660 AGA_ohne_Funktion "Aussensoundsteuergerät ohne Funktion (Gesetzliche Anforderung, Fahrzeugnutzer muss informiert werden).";
CM_ SG_ 1660 AGA_Texte "Texte zur Anzeige im Kombi";
CM_ SG_ 1660 AGA_Verstaerker_Mute "Freischaltung Verstaerkerkanal";
CM_ SG_ 1660 E_Sound_verbaut "Signal dient zur Unterscheidung der beiden SGs 'aktive AGA' und 'e-sound' durch das Kombii. Beide SGs nutzen identische Signale und gleiche Diagnoseadresse.";

CM_ SG_ 64 AB_Anzeige_Fussg "Anzeige für ausgelöste Fussgängerschutz-Aktuatorik";
CM_ SG_ 64 AB_Belegung_VF "Belegungserkennung vorne Fahrer.";
CM_ SG_ 64 AB_Crash_Int "Crash_Intensität_1 = fahrzeugabhängige Reaktionen im Crash
Crash_Intensität_2 = fahrzeugabhängige Reaktionen im Crash
Crash_Intensität_3 = fahrzeugabhängige Reaktionen im Crash

Die jeweiligen fahrzeugabhängigen Reaktionen im Crash sind in einem separ";
CM_ SG_ 64 AB_Deaktiviert "Airbag oder Gurtstraffer wurden per Anpassung deaktiviert: Aktualisierung erst nach Selbsttest";
CM_ SG_ 64 AB_Deaktivierung_HV "Deaktivierung des HV-Systems und der HV-Teilnehmer im Crash (u.a. Hybrid- und Elektrofahrzeuge)";
CM_ SG_ 64 AB_Diagnose "Airbag in Diagnose";
CM_ SG_ 64 AB_eCS_Error "Signal zur Anforderung der Anzeige von Störungen im System der elektrischen Gurtverriegelung";
CM_ SG_ 64 AB_EDR_Trigger "Triggerbedingung zur dezentralen Aufzeichnung unfallrelevanter Daten im Event Data Recorder";
CM_ SG_ 64 AB_Erh_Auf_VB "Der Fahrer soll bei einem Statuswechsel des Beifahrerairbags (ausgelöst durch die Beifahrerinsassenerkennung oder den Schlüsselschloßschalter) aufmerksam gemacht werden durch eine Anzeige im Kombi. Nur Audi: gültig für: AB2 (4-Türer AU352), B7, C6, D3";
CM_ SG_ 64 AB_Front_Crash "Bit wird bei Überschreitung der Gurtstraffer-, US- und RdW-Schwelle gesetzt";
CM_ SG_ 64 AB_Gurtschloss_FA_ext "Das Ergebnis der Basisfunktion 'Plausibilisierung Gurtschloss' des Verlassenskonzepts wird im Signal dargestellt.";
CM_ SG_ 64 AB_Gurtschloss_FA_ext_aktiv "Über dieses Signal wird signalisiert ob die Erweiterte Gurtdiagnose (Ergebnis wird im Signal AB_Gurtschloss_FA_ext dargestellt) aktiviert oder deaktiviert ist.";
CM_ SG_ 64 AB_Gurtwarn_VB "Beifahrer hat Gurt nicht gesteckt, Anzeige im Kombi";
CM_ SG_ 64 AB_Gurtwarn_VF "Fahrer hat Gurt nicht gesteckt, Anzeige im Kombi";
CM_ SG_ 64 AB_Heck_Crash "Wird für alle neu anlaufenden Projekte umgesetzt: AB8.4, Audi8/VW8";
CM_ SG_ 64 AB_Lampe "Sicherheitswarnlampe im Kombi wird vom Airbag-SG angesteuert; Zustand der Lampe wird auf dem CAN-Bus ausgegeben (auch Blinkinformation).";
CM_ SG_ 64 AB_MKB_Anforderung "Anforderung Multi-Kollisions-Bremsung";
CM_ SG_ 64 AB_MKB_gueltig "Multi-Kollisions-Bremsung im Airbag freigeschaltet";
CM_ SG_ 64 AB_PAO_Leuchte_Anf "Anforderung an die Passenger-Airbag-Off Leuchte in der Dachkonsole (ein / aus), Einsatz nur bei PAG";
CM_ SG_ 64 AB_RGS_Anst "PreCrash-Ansteuerung reversibler Gurtstraffer (Aktivierung und Kraftniveau)

10xx = deaktiviert";
CM_ SG_ 64 AB_Rollover_Crash "Wird im B6/B7 Cabrio und New Beetle Cabrio bedient. ";
CM_ SG_ 64 AB_SB_Crash "Z.Zt. nur in Verbindung mit Crash-Intensität >= 100b (Kraftstoffpumpenabschaltung) verwendet.
";
CM_ SG_ 64 AB_SF_Crash "Z.Zt. nur in Verbindung mit Crash-Intensität >= 100b (Kraftstoffpumpenabschaltung) verwendet.";
CM_ SG_ 64 AB_Stellgliedtest "Information, ob Airbag im Stellgliedtest ist, um eine Notrufauflösung beim Stellgliedtest zu verhindern";
CM_ SG_ 64 AB_Systemfehler "Systemfehler Ggf. wird Warnlampe dauernd eingeschaltet.";
CM_ SG_ 64 AB_Texte_AKS "Textanzeige für pyrotechnische Auslösung der aktiven Kopfstütze (AKS)";
CM_ SG_ 64 AB_VB_deaktiviert "Als Option vorgehalten, Beifahrerairbag wurden per Schlüsselschalter oder Insassenerkennung deaktiviert";
CM_ SG_ 64 AB_Versorgungsspannung "Übertragung der Plausibilitätsinformation Kl.15-Last vs. Kl.15-CAN.
Bedienung im Fall Kl.15-Last 'EIN' und Kl.15-CAN 'AUS' mit Ausgabe Warnung/Akustik im Kombi.";
CM_ SG_ 64 Airbag_01_CRC "Für MLB:
'Berechnung siehe Lastenheft 'Kommunikationsabsicherung für FlexRay und CAN''

Ab MQB und MLBevo:
'Berechnung siehe Lastenheft 'End-to-End Kommunikationsabsicherung''

Endwerte siehe Begleitdokument 'S-PDU Kennungsfolgen'";
CM_ SG_ 64 ASM_Masterzeit_02 "Masterzeit für alle ASM Sender";

CM_ SG_ 1312 AB_Abschaltanf_SIH_BF "Die Insassenerkennung auf der Beifahrerseite fordert bei Übertemperatur eine Abschaltung der Sitzheizung an. Die Übertemperatur kann bei niederohmigen Nebenschlüssen der Sitzheizungsmatte als Folge von zu hohem resultierenden Strom auftreten.";
CM_ SG_ 1312 AB_Anforderung_eCall "Trigger für Car2X Steuergerät das ein eCall Ereignis erkannt wurde.";
CM_ SG_ 1312 AB_Anforderung_USM "Trigger für Gateway (OBDC) und MIB/MMI, dass ein USM-Ereignis erkannt wurde.";
CM_ SG_ 1312 AB_Anprall_FGS "Uebermittlung der Lage einer Kollision, Fussgaengerschutz-Aktorik";
CM_ SG_ 1312 AB_Anprall_Front_Beifahrer "Uebermittlung der Lage einer Kollision, Anprallzone Front Beifahrerseite";
CM_ SG_ 1312 AB_Anprall_Front_Fahrer "Uebermittlung der Lage einer Kollision, Anprallzone Front Fahrerseite";
CM_ SG_ 1312 AB_Anprall_Heck_Beifahrer "Uebermittlung der Lage einer Kollision, Anprallzone Beifahrerseite hinten";
CM_ SG_ 1312 AB_Anprall_Heck_Fahrer "Uebermittlung der Lage einer Kollision, Anprallzone Fahrerseite hinten";
CM_ SG_ 1312 AB_Anprall_Rollover "Uebermittlung der Lage einer Kollision, Rollover erkannt";
CM_ SG_ 1312 AB_Anprall_Seite_Beifahrer "Uebermittlung der Lage einer Kollision, Anprallzone Beifahrerseite Seite";
CM_ SG_ 1312 AB_Anprall_Seite_Fahrer "Uebermittlung der Lage einer Kollision, Anprallzone Fahrerseite Seite";
CM_ SG_ 1312 AB_Belegung_VB "Belegungserkennung vorne Beifahrer. Wird in US-Steuergeräten über Bladder-Matte bedient, optional bei RdW, falls SBE_EuroNCAP entschieden wird.";
CM_ SG_ 1312 AB_Crashschwere "Übermittlung der Crashschwere an das Gateway (OBDC)";
CM_ SG_ 1312 AB_Gurtschloss_BF "Gurtschlossstatus Beifahrerseite";
CM_ SG_ 1312 AB_Gurtschloss_FA "Gurtschlosstatatus Fahrerseite";
CM_ SG_ 1312 AB_Gurtschloss_Reihe2_BF "Gurtschlossstatus 2. Reihe Beifahrerseite,  Mehrausstattung";
CM_ SG_ 1312 AB_Gurtschloss_Reihe2_FA "Gurtschlossstatus 2. Reihe Fahrerseite, Mehrausstattung";
CM_ SG_ 1312 AB_Gurtschloss_Reihe2_MI "Gurtschlossstatus 2. Reihe Mitte,  Mehrausstattung";
CM_ SG_ 1312 AB_Gurtschloss_Reihe3_BF "Gurtschlossstatus 3. Reihe Beifahrerseite,  Mehrausstattung";
CM_ SG_ 1312 AB_Gurtschloss_Reihe3_FA "Gurtschlossstatus 3. Reihe Fahrerseite,  Mehrausstattung";
CM_ SG_ 1312 AB_Gurtschloss_Reihe3_MI "Gurtschlossstatus 3. Reihe Mitte,  Mehrausstattung";
CM_ SG_ 1312 AB_Sitzpos_Sens_BF "Ausgabe Sitzposition Beifahrer";
CM_ SG_ 1312 AB_Sitzpos_Sens_FA "Ausgabe Sitzposition Fahrer";
CM_ SG_ 1312 AB_Wickelklappung_Reihe2_BF "Status Wickelklappung 2. Reihe Beifahrerseite, Mehrausstattung";
CM_ SG_ 1312 AB_Wickelklappung_Reihe2_FA "Status Wickelklappung 2. Reihe Fahrerseite, Mehrausstattung";
CM_ SG_ 1312 AB_Wickelklappung_Reihe2_MI "Status Wickelklappung 2. Reihe Mitte, Mehrausstattung";
CM_ SG_ 1312 Airbag_02_CRC "Für MLB:
'Berechnung siehe Lastenheft 'Kommunikationsabsicherung für FlexRay und CAN''

Ab MQB und MLBevo:
'Berechnung siehe Lastenheft 'End-to-End Kommunikationsabsicherung''

Endwerte siehe Begleitdokument 'S-PDU Kennungsfolgen'";
CM_ SG_ 1312 LoGeWa_Event_Kombiwarnung "Event für Kombiwarnung";
CM_ SG_ 1312 SC_PAO_OFF_Anf "Sollwert für LED 'OFF' in Anzeige Passenger Airbag On/Off";
CM_ SG_ 1312 SC_PAO_ON_Anf "Sollwert für LED 'ON' in Anzeige Passenger Airbag On/Off";
CM_ SG_ 1312 SC_PAO_Schriftzug_Anf "Sollwert für LED 'PASSENGER AIRBAG' in Anzeige Passenger Airbag On/Off";

CM_ SG_ 65 AB_DeltaV_X_eCall "Transmission of the DeltaV longitudinal during Crash (0-250ms) as additional information for eCall";
CM_ SG_ 65 AB_DeltaV_Y_eCall "Transmission of the DeltaV lateral during Crash (0-250ms) as additional information for eCall";
CM_ SG_ 65 AB_MKB_Safing "Safing für Multi-Kollisions-Bremsung";
CM_ SG_ 65 Airbag_03_CRC "Für MLB:
'Berechnung siehe Lastenheft 'Kommunikationsabsicherung für FlexRay und CAN''

Ab MQB und MLBevo:
'Berechnung siehe Lastenheft 'End-to-End Kommunikationsabsicherung''

Endwerte siehe Begleitdokument 'S-PDU Kennungsfolgen'";

CM_ SG_ 2527679722 AB_Anzeige_Kombi_SRAB "Status SRAB HMI";
CM_ SG_ 2527679722 AB_Anzeige_Komfort_HBFS "Komfortposition überschritten HBFS";
CM_ SG_ 2527679722 AB_Anzeige_Komfort_HFS "Komfortposition überschritten HFS";
CM_ SG_ 2527679722 AB_Anzeige_Sitz_Komfort_HBFS "Sitzdisplay Komfortposition überschritten HBFS";
CM_ SG_ 2527679722 AB_Anzeige_Sitz_Komfort_HFS "Sitzdisplay Komfortposition überschritten HFS";
CM_ SG_ 2527679722 AB_Gurtschloss_MI "Gurtschloss-Status 1. Reihe Mitte
Ersteinsetzer: T6PA";
CM_ SG_ 2527679722 AB_Gurtschloss_Reihe4_BF "Gurtschlossstatus 4. Reihe Beifahrerseite,  Mehrausstattung";
CM_ SG_ 2527679722 AB_Gurtschloss_Reihe4_FA "Gurtschlossstatus 4. Reihe Fahrerseite, Mehrausstattung";
CM_ SG_ 2527679722 AB_Gurtschloss_Reihe4_MI "Gurtschlossstatus 4. Reihe Mitte,  Mehrausstattung";
CM_ SG_ 2527679722 AB_Gurtwarn_VM "Beifahrer auf mittlerem Sitz (Nutzfahrzeug) hat Gurt nicht gesteckt, Anzeige im Kombi";
CM_ SG_ 2527679722 AB_Status_Sitz_SRAB_HBFS "Status SRAB Sitzdisplay HBFS";
CM_ SG_ 2527679722 AB_Status_Sitz_SRAB_HFS "Status SRAB Sitzdisplay HFS";
CM_ SG_ 2527679722 AB_wSBR_Batteriestatus "Anzeige einer schwachen Batterie in einer Sitzeinheit des wSBR-Systems im Kombi.";
CM_ SG_ 2527679722 Airbag_06_BZ "4bit Botschaftszähler, wird mit jeder Sendebotschaft inkrementiert";
CM_ SG_ 2527679722 Airbag_06_CRC "Für MLB:
Berechnung siehe Lastenheft 'Kommunikationsabsicherung für FlexRay und CAN'
Ab MQB und MLBevo:
Berechnung siehe Lastenheft 'End-to-End Kommunikationsabsicherung'

Endwerte siehe Begleitdokument 'S-PDU Kennungsfolgen'";

CM_ SG_ 1633 AAG_Anhaenger_abgesteckt "Anhaenger wurde bei Kl. 15 aus abgesteckt";
CM_ SG_ 1633 AAG_Anhaenger_erkannt "Erkennung Anhaenger ";
CM_ SG_ 1633 AAG_AVS_Fehler_02 "Fehler AVS";
CM_ SG_ 1633 AAG_AVS_Fehler_02_inv "Fehler AVS (inverses Signal)";
CM_ SG_ 1633 AAG_AVS_Stati "Status AVS (bei abnehmbarer oder mech.schwenkbarer Anhängerkupplung ist der Status immer 0)";
CM_ SG_ 1633 AAG_Blinker_H_aktiv "Status: Anhaenger Blinker aktiv";
CM_ SG_ 1633 AAG_Blinker_HL_def "Anhaenger Blinker links defekt";
CM_ SG_ 1633 AAG_Blinker_HR_def "Anhaenger Blinker rechts defekt";
CM_ SG_ 1633 AAG_Bremsl_durch_ECD "Bremslicht durch ECD aktiv";
CM_ SG_ 1633 AAG_Bremslicht_H_def "Anhaenger Bremslicht defekt";
CM_ SG_ 1633 AAG_Bremslicht_Reku "AAG_Bremslicht_Reku meldet zyklisch den empfangenen Zustand des CAN-Signals MO_Bremslicht_Reku zurück.";
CM_ SG_ 1633 AAG_BZ "4bit-Botschaftszaehler, wird in jeder Sendebotschaft inkrementiert

";
CM_ SG_ 1633 AAG_LED_aktiv "Dieses Signal sendet der Beleuchtungsart des Anhängers (LED oder Lampe)
Bei LED aktiv erfolgt kein Kaltüberwachung";
CM_ SG_ 1633 AAG_NSL_aktiv "Anhaenger Nebelschlusslicht aktiv";
CM_ SG_ 1633 AAG_Schlusslicht_HL_def "Anhaenger Schlußlicht links defekt";
CM_ SG_ 1633 AAG_Schlusslicht_HR_def "Anhaenger Schlußlicht rechts defekt";

CM_ SG_ 2549880935 AuthTime_eCall_Req_Data "AuthTime - Authentische Zeit
ISO-TP Datenkanal - FID2NA
Request Funktion 0x18 AuthTime

Funktion Authentische Zeit an OCU (Request)";

CM_ SG_ 2550012007 AuthTime_eCall_Resp_Data "AuthTime - Authentische Zeit
ISO-TP Datenkanal - FID2NA
Response Knoten 0x67 eCall (OCU)

Knoten OCU an Funktion AuthTime (Response)";

CM_ SG_ 2536703234 BAP_ACC_ASG_03_Header "ACC Anzeigesteuergeraet";

CM_ SG_ 2536714504 BAP_Audio_ASG_09_Header "Audio Anzeigesteuergeraet MCC4 ABT-Display HFS 1";

CM_ SG_ 2536714505 BAP_Audio_ASG_10_Header "Audio Anzeigesteuergeraet MCC4 ABT-Display HBFS 1";

CM_ SG_ 2536714506 BAP_Audio_ASG_11_Header "Zweites ASG für Audio Katalog MCC4 ABT-Display HFS 2";

CM_ SG_ 2536714507 BAP_Audio_ASG_12_Header "Zweites ASG für Audio Katalog MCC4 ABT-Display HBFS 2";

CM_ SG_ 2536704257 BAP_Aussenlicht_ASG_02_Header "Aussenlicht Anzeigesteuergeraet";

CM_ SG_ 2536708866 BAP_AWV_ASG_03_Header "AWV Anzeigesteuergeraet";

CM_ SG_ 2536705809 BAP_BC_FSG_02_Header "BC Funktionssteuergeraet zweites Sendesignal
(zusätzliches Signal für abzusichernde Inhalte)";

CM_ SG_ 2536733184 BAP_BSMOIS2_ASG_01_Header "BSMOIS Anzeigesteuergeraet
(2. Instanz BSIS right - blind spot information system)";

CM_ SG_ 2536733200 BAP_BSMOIS2_FSG_01_Header "BSMOIS Funktionssteuergeraet
(2. Instanz BSIS right - blind spot information system)";

CM_ SG_ 2536733440 BAP_BSMOIS3_ASG_01_Header "BSMOIS Anzeigesteuergeraet
(3. Instanz BSIS left - blind spot information system)";

CM_ SG_ 2536733456 BAP_BSMOIS3_FSG_01_Header "BSMOIS Funktionssteuergeraet
(3. Instanz hier BSIS left - blind spot information system)";

CM_ SG_ 2536732160 BAP_BSMOIS_ASG_01_Header "BSMOIS Anzeigesteuergeraet
(hier MOIS - moving off information system)";

CM_ SG_ 2536732176 BAP_BSMOIS_FSG_01_Header "BSMOIS Funktionssteuergeraet
(hier MOIS - moving off information system)";

CM_ SG_ 2536734976 BAP_California_ASG_01_Header "California Anzeigesteuergerät";

CM_ SG_ 2536734992 BAP_California_FSG_01_Header "California Funktionssteuergeraet";

CM_ SG_ 2536726786 BAP_Car2X_ASG_03_Header "Car2X-Objekte Anzeigesteuergerät3";

CM_ SG_ 2536726802 BAP_Car2X_FSG_03_Header "Car2X-Objekte Funktionssteuergeraet";

CM_ SG_ 2536707844 BAP_Charisma_ASG_05_Header "Charisma  Anzeigesteuergeraet";

CM_ SG_ 2536726528 BAP_ClimateDiag_ASG_01_Header "Climate-Diagnose Anzeigesteuergerät";

CM_ SG_ 2536726544 BAP_ClimateDiag_FSG_01_Header "Climate-Diagnose Funktionssteuergerät";

CM_ SG_ 2536719616 BAP_DisplayConfig_ASG_01_Header "Display Config Anzeigesteuergeraet";

CM_ SG_ 2536719617 BAP_DisplayConfig_ASG_02_Header "Display Config Anzeigesteuergeraet";

CM_ SG_ 2536719632 BAP_DisplayConfig_FSG_01_Header "Display Konfiguration Funktionssteuergeraet Kombi";

CM_ SG_ 2536727296 BAP_Doors2_ASG_01_Header "BAP Strecke für Tür Beifahrerseite
Anzeigesteuergerät
(Im-/Export PSO2.0)";

CM_ SG_ 2536727312 BAP_Doors2_FSG_01_Header "BAP Strecke für Tür Beifahrerseite
Funktionssteuergerät
(Im-/Export PSO2.0)";

CM_ SG_ 2536724736 BAP_Doors_ASG_01_Header "Doors
Anzeigesteuergerät";

CM_ SG_ 2536724752 BAP_Doors_FSG_01_Header "BAP Strecke für Türen
Funktionssteuergerät
(Im-/Export PSO2.0)";

CM_ SG_ 2536734208 BAP_DrivingDynamics_ASG_01_Hdr "Allradkachel
Anzeigesteuergerät";

CM_ SG_ 2536734224 BAP_DrivingDynamics_FSG_01_Hdr "BAP Strecke für Allradkachel
Funktionssteuergerät";

CM_ SG_ 2536717312 BAP_EfficAssist_ASG_01_Header "BAP Data dummy";

CM_ SG_ 2536717328 BAP_EfficAssist_FSG_01_Header "BAP dummy data";

CM_ SG_ 2536706819 BAP_Einheiten_ASG_04_Header "Einheiten Anzeigesteuergeraet";

CM_ SG_ 2536725760 BAP_EngFunctions_ASG_01_Header "EngineFunctions
Anzeigesteuergeraet";

CM_ SG_ 2536725776 BAP_EngFunctions_FSG_01_Header "EngineFunctions
Funktionssteuergeraet";

CM_ SG_ 2536724480 BAP_ENI2_ASG_01_Header "zweite Instanz für ENI für Online-Update für DDA
zweite FSG-Botschaft (DDA)";

CM_ SG_ 2536724481 BAP_ENI2_ASG_02_Header "zweite Instanz für ENI für Online-Update für DDA
zweite ASG-Botschaft (MIB)";

CM_ SG_ 2536724496 BAP_ENI2_FSG_01_Header "zweite Instanz für ENI für Online-Update für DDA
zweite FSG-Botschaft (DDA)";

CM_ SG_ 2536724497 BAP_ENI2_FSG_02_Header "zweite Instanz für ENI für Online-Update für DDA
zweite FSG-Botschaft (DDA)";

CM_ SG_ 2536730112 BAP_ENI3_ASG_01_Header "dritte Instanz für ENI
langsame ASG-Botschaft";

CM_ SG_ 2536730113 BAP_ENI3_ASG_02_Header "dritte Instanz für ENI
schnelle ASG-Botschaft";

CM_ SG_ 2536730128 BAP_ENI3_FSG_01_Header "dritte Instanz für ENI
langsame FSG-Botschaft";

CM_ SG_ 2536730129 BAP_ENI3_FSG_02_Header "dritte Instanz für ENI
schnelle FSG-Botschaft";

CM_ SG_ 2536716033 BAP_ENI_ASG_02_Header "ENI Anzeigesteuergeraet";

CM_ SG_ 2536721664 BAP_FAS_Profiles_ASG_01_Header "FAS Profiles Anzeigesteuergeraet";

CM_ SG_ 2536721680 BAP_FAS_Profiles_FSG_01_Header "FAS Profiles Funktionssteuergeraet";

CM_ SG_ 2536707072 BAP_Homelink_ASG_01_Header "Homelink Anzeigesteuergeraet";

CM_ SG_ 2536707088 BAP_Homelink_FSG_01_Header "Homelink Funktionssteuergeraet";

CM_ SG_ 2536702978 BAP_HUD_ASG_03_Header "HUD Anzeigesteuergeraet 3";

CM_ SG_ 2536722944 BAP_IAA_PSO_ASG_01_Header "BAP Strecke für IAA & PSO
Anzeigesteuergeräte MIB";

CM_ SG_ 2536722945 BAP_IAA_PSO_ASG_02_Header "BAP Strecke für IAA & PSO
Anzeigesteuergeräte KI";

CM_ SG_ 2536722946 BAP_IAA_PSO_ASG_03_Header "BAP Strecke für IAA & PSO
Anzeigesteuergeräte BCM";

CM_ SG_ 2536722960 BAP_IAA_PSO_FSG_01_Header "BAP Strecke für IAA & PSO";

CM_ SG_ 2536722434 BAP_InfoSettings_ASG_03_Header "BAP Strecke für Infotainment Settings Anzeigesteuergerät";

CM_ SG_ 2536722448 BAP_InfoSettings_FSG_01_Header "BAP Strecke für Infotainment Settings Übergabe am Kombi

Relevant nur für A1 NF und Q3 NF";

CM_ SG_ 2536704001 BAP_Innenlicht_ASG_02_Header "Innenlicht Anzeigesteuergeraet 2";

CM_ SG_ 2536702208 BAP_Klima1_ASG_01_Header "BAP_Klima1_ASG_01";

CM_ SG_ 2536702224 BAP_Klima1_FSG_01_Header "BAP-Klima1_FSG_01";

CM_ SG_ 2536702464 BAP_Klima2_ASG_01_Header "BAP_Klima2_ASG_01";

CM_ SG_ 2536718848 BAP_KlimaMaster_ASG_01_Header "KlimaMaster Anzeigesteuergeraet1";

CM_ SG_ 2536718849 BAP_KlimaMaster_ASG_02_Header "KlimaMaster Anzeigesteuergeraet2";

CM_ SG_ 2536718864 BAP_KlimaMaster_FSG_01_Header "KlimaMaster Funktionssteuergeraet";

CM_ SG_ 2536708354 BAP_LDW_ASG_03_Header "LDW Anzeigesteuergeraet";

CM_ SG_ 2536705537 BAP_Mirror_ASG_02_Header "Mirror Anzeigesteuergeraet";

CM_ SG_ 2536732416 BAP_MobDevKey_ASG_01_Header "MobDevKey Anzeigesteuergeraet 01";

CM_ SG_ 2536732417 BAP_MobDevKey_ASG_02_Header "MobDevKey Anzeigesteuergeraet 02";

CM_ SG_ 2536732432 BAP_MobDevKey_FSG_01_Header "MobDevKey Funktionssteuergeraet 01";

CM_ SG_ 2536734464 BAP_MobDevKeyOnline_ASG_01_Heade "MobDevKeyOnline Anzeigesteuergeraet 01";

CM_ SG_ 2536734480 BAP_MobDevKeyOnline_FSG_01_Heade "MobDevKeyOnline Funktionssteuergeraet 01";

CM_ SG_ 2536712704 BAP_OnlineFunction_ASG_01_Header "OnlineFunctions Anzeigesteuergeraet";

CM_ SG_ 2536712705 BAP_OnlineFunction_ASG_02_Header "OnlineFunctions Anzeigesteuergeraet";

CM_ SG_ 2536712720 BAP_OnlineFunction_FSG_01_Header "OnlineFunctions Funktionssteuergeraet";

CM_ SG_ 2536704516 BAP_OPS_ASG_05_Header "OPS Anzeigesteuergeraet 5";

CM_ SG_ 2536723712 BAP_PaCo_ASG_01_Header "PaCo Anzeigesteuergeraet";

CM_ SG_ 2536723714 BAP_PaCo_ASG_03_Header "PaCo Anzeigesteuergeraet3";

CM_ SG_ 2536723728 BAP_PaCo_FSG_01_Header "PaCo Funktionssteuergeraet";

CM_ SG_ 2536734721 BAP_PlugAndCharge_ASG_02_Header "Signal für PnC, HV-Laden";

CM_ SG_ 2536734737 BAP_PlugAndCharge_FSG_02_Header "Signal für PnC, HV-Laden";

CM_ SG_ 2536728320 BAP_REM2_ASG_01_Header "REM Anzeigesteuergeraet
(REM=road experience management)";

CM_ SG_ 2536728336 BAP_REM2_FSG_01_Header "REM Funktionssteuergeraet
(REM=road experience management)";

CM_ SG_ 2536728337 BAP_REM2_FSG_02_Header "REM Funktionssteuergeraet
(REM=road experience management) 
fast signal";

CM_ SG_ 2536725248 BAP_REM_ASG_01_Header "REM Anzeigesteuergeraet
(REM=road experience management)";

CM_ SG_ 2536725264 BAP_REM_FSG_01_Header "REM Funktionssteuergeraet
(REM=road experience management)";

CM_ SG_ 2536725265 BAP_REM_FSG_02_Header "REM Funktionssteuergeraet
(REM=road experience management) 
fast signal";

CM_ SG_ 2536721920 BAP_RemoteServices_ASG_01_Header "RemoteServices Anzeigesteuergeraet";

CM_ SG_ 2536721921 BAP_RemoteServices_ASG_02_Header "RemoteServices Anzeigesteuergeraet";

CM_ SG_ 2536721936 BAP_RemoteServices_FSG_01_Header "RemoteServices Funktionssteuergeraet";

CM_ SG_ 2536731904 BAP_RollingAbility_ASG_01_Header "RollingAbility ASG-Botschaft";

CM_ SG_ 2536731920 BAP_RollingAbility_FSG_01_Header "RollingAbility FSG-Botschaft";

CM_ SG_ 2536730624 BAP_RSO_ASG_01_Header "RemoteStartOnline ASG1-Botschaft";

CM_ SG_ 2536730640 BAP_RSO_FSG_01_Header "RemoteStartOnline FSG-Botschaft";

CM_ SG_ 2536704768 BAP_RVC_ASG_01_Header "Datenkanal für BAP-Katalog RVC";

CM_ SG_ 2536719872 BAP_SDS_ASG_01_Header "Sprach-Dialog-System Anzeigesteuergeraet";

CM_ SG_ 2536719888 BAP_SDS_FSG_01_Header "Sprach-Dialog-System
Funktionssteuergeraet";

CM_ SG_ 2536717057 BAP_SeatPneumatic_ASG_02_Header "Bap für SeatPneumatic";

CM_ SG_ 2536735488 BAP_SecEvents2_ASG_01_Header "Security Events für IDS (Intrusion Detection System)
LSG ID - 131dez (SecurityEvents2)";

BA_DEF_  "DBName" STRING;
BA_DEF_  "GenNWMApBusSleep" STRING;
BA_DEF_  "GenNWMApCanNormal" STRING;
BA_DEF_  "GenNWMApCanOff" STRING;
BA_DEF_  "GenNWMApCanOn" STRING;
BA_DEF_  "GenNWMApCanSleep" STRING;
BA_DEF_  "GenNWMApCanWakeUp" STRING;
BA_DEF_  "GenNWMGotoMode_Awake" STRING;
BA_DEF_  "GenNWMGotoMode_BusSleep" STRING;
BA_DEF_  "GenNWMSleepTime" INT 0 1000000;
BA_DEF_  "GenNWMTalkNM" STRING;
BA_DEF_  "Manufacturer" STRING;
BA_DEF_  "NmhBaseAddress" HEX 0 536870911;
BA_DEF_  "NmhMessageCount" INT 0 1024;
BA_DEF_  "NmType" STRING;
BA_DEF_  "VAGTP20_SetupMessageCount" INT 0 255;
BA_DEF_  "VAGTP20_SetupStartAddress" HEX 0 2047;
BA_DEF_  "VersionDay" INT 1 31;
BA_DEF_  "VersionMonth" INT 1 12;
BA_DEF_  "VersionWeek" INT 1 52;
BA_DEF_  "VersionYear" INT 0 99;
BA_DEF_  "VersionNumber" INT 0 65535;
BA_DEF_  "BusType" STRING;
BA_DEF_  "Baudrate" INT 1 1000000;
BA_DEF_  "SamplePointMin" INT 1 100;
BA_DEF_  "SamplePointMax" INT 1 100;
BA_DEF_  "SyncJumpWidthMin" INT 1 4;
BA_DEF_  "SyncJumpWidthMax" INT 1 4;
BA_DEF_  "NBTMin" INT 1 30;
BA_DEF_  "NBTMax" INT 1 30;
BA_DEF_  "NmhTimeoutTimer" INT 0 65535;
BA_DEF_  "NmhWaitBusSleepTimer" INT 0 65535;
BA_DEF_  "NmhPrepareBusSleepTimer" INT 0 65535;
BA_DEF_  "NmhLongTimer" INT 0 65535;
BA_DEF_  "NmhNStart" INT 0 255;
BA_DEF_ BU_  "GenNodAutoGenDsp" ENUM "No", "Yes";
BA_DEF_ BU_  "GenNodAutoGenSnd" ENUM "No", "Yes";
BA_DEF_ BU_  "GenNodSleepTime" INT 0 1000000;
BA_DEF_ BU_  "ILUsed" ENUM "No", "Yes";
BA_DEF_ BU_  "ECUVariantDefault" ENUM "No", "Yes";
BA_DEF_ BU_  "ECUVariantGroup" STRING;
BA_DEF_ BU_  "NodeLayerModules" STRING;
BA_DEF_ BU_  "NmhNode" ENUM "No", "Yes";
BA_DEF_ BU_  "NmNode" ENUM "No", "Yes";
BA_DEF_REL_ BU_SG_REL_  "GenSigTimeoutTime" INT 0 65535;
BA_DEF_ BO_  "DiagRequest" ENUM "No", "Yes";
BA_DEF_ BO_  "DiagResponse" ENUM "No", "Yes";
BA_DEF_ BO_  "DiagState" ENUM "No", "Yes";
BA_DEF_ BO_  "GenMsgChkConstant" HEX 0 4095;
BA_DEF_ BO_  "GenMsgCycleTime" INT 0 65535;
BA_DEF_ BO_  "GenMsgCycleTimeFast" INT 0 65535;
BA_DEF_ BO_  "GenMsgDelayTime" INT 0 100000;
BA_DEF_ BO_  "GenMsgILSupport" ENUM "No", "Yes";
BA_DEF_ BO_  "GenMsgNrOfRepetition" INT 0 100;
BA_DEF_ BO_  "GenMsgPDUConstants" STRING;
BA_DEF_ BO_  "GenMsgSendType" ENUM "Cyclic", "not_used", "not_used", "not_used", "not_used", "not_used", "not_used", "IfActive", "NoMsgSendType";
BA_DEF_ BO_  "GenMsgStartDelayTime" INT 0 100000;
BA_DEF_ BO_  "NmMessage" ENUM "No", "Yes";
BA_DEF_ BO_  "NmhMessage" ENUM "No", "Yes";
BA_DEF_ BO_  "MsgType" ENUM "Application", "NM ", "NMH", "TP2.0", "ISO-TP ", "BAP", "EID", "KS", "XCP_PRE_CONFIGURED", "XCP_RUNTIME_CONFIGURED";
BA_DEF_ BO_  "VAGTP20_API" HEX 0 255;
BA_DEF_ BO_  "VAGTP20_DynConnection" ENUM "No", "Yes";
BA_DEF_ BO_  "VAGTP20_DynSetup" ENUM "No", "Yes";
BA_DEF_ BO_  "VAGTP20_StatConnection" ENUM "No", "Yes";
BA_DEF_ SG_  "GenSigActiveRepetitions" INT -2147483648 2147483647;
BA_DEF_ SG_  "GenSigInactiveValue" INT -2147483648 2147483647;
BA_DEF_ SG_  "GenSigSendType" ENUM "Cyclic", "OnWrite", "OnWriteWithRepetition", "OnChange", "OnChangeWithRepetition", "IfActive", "IfActiveWithRepetition", "NoSigSendType", "OnChangeAndIfActive", "OnChangeAndIfActiveWithRepetition";
BA_DEF_ SG_  "GenSigStartValue" INT -2147483648 2147483647;
BA_DEF_ SG_  "NWM-WakeupAllowed" ENUM "No", "Yes";
BA_DEF_ SG_  "GenSigFuncType" ENUM "NoFunction", "MsgCounter", "CRC-8", "XOR", "XOR-2", "DatedBit", "SW-Kl15", "CHK", "Constant", "Protocol", "CRC-8-SAE_J1850", "CRC-32", "DataLength", "DataID", "MsgCounter16", "SOK-Signatur", "Cluster";
BA_DEF_ SG_  "GenSigSwitchedByIgnition" ENUM "No", "Yes";
BA_DEF_ SG_  "Fehlerwert" HEX 0 2147483647;
BA_DEF_ SG_  "GenSigMissingSourceValue" HEX 0 2147483647;
BA_DEF_DEF_  "DBName" "";
BA_DEF_DEF_  "GenNWMApBusSleep" "";
BA_DEF_DEF_  "GenNWMApCanNormal" "";
BA_DEF_DEF_  "GenNWMApCanOff" "";
BA_DEF_DEF_  "GenNWMApCanOn" "";
BA_DEF_DEF_  "GenNWMApCanSleep" "";
BA_DEF_DEF_  "GenNWMApCanWakeUp" "";
BA_DEF_DEF_  "GenNWMGotoMode_Awake" "";
BA_DEF_DEF_  "GenNWMGotoMode_BusSleep" "";
BA_DEF_DEF_  "GenNWMSleepTime" 0;
BA_DEF_DEF_  "GenNWMTalkNM" "";
BA_DEF_DEF_  "Manufacturer" "";
BA_DEF_DEF_  "NmhBaseAddress" 0;
BA_DEF_DEF_  "NmhMessageCount" 1;
BA_DEF_DEF_  "NmType" "None";
BA_DEF_DEF_  "VAGTP20_SetupMessageCount" 0;
BA_DEF_DEF_  "VAGTP20_SetupStartAddress" 0;
BA_DEF_DEF_  "VersionDay" 9;
BA_DEF_DEF_  "VersionMonth" 5;
BA_DEF_DEF_  "VersionWeek" 19;
BA_DEF_DEF_  "VersionYear" 23;
BA_DEF_DEF_  "VersionNumber" 0;
BA_DEF_DEF_  "BusType" "";
BA_DEF_DEF_  "Baudrate" 1;
BA_DEF_DEF_  "SamplePointMin" 1;
BA_DEF_DEF_  "SamplePointMax" 1;
BA_DEF_DEF_  "SyncJumpWidthMin" 1;
BA_DEF_DEF_  "SyncJumpWidthMax" 1;
BA_DEF_DEF_  "NBTMin" 10;
BA_DEF_DEF_  "NBTMax" 20;
BA_DEF_DEF_  "NmhTimeoutTimer" 0;
BA_DEF_DEF_  "NmhWaitBusSleepTimer" 0;
BA_DEF_DEF_  "NmhPrepareBusSleepTimer" 0;
BA_DEF_DEF_  "NmhLongTimer" 0;
BA_DEF_DEF_  "NmhNStart" 0;
BA_DEF_DEF_  "GenNodAutoGenDsp" "Yes";
BA_DEF_DEF_  "GenNodAutoGenSnd" "Yes";
BA_DEF_DEF_  "GenNodSleepTime" 0;
BA_DEF_DEF_  "ILUsed" "Yes";
BA_DEF_DEF_  "ECUVariantDefault" "Yes";
BA_DEF_DEF_  "ECUVariantGroup" "";
BA_DEF_DEF_  "NodeLayerModules" "";
BA_DEF_DEF_  "NmhNode" "Yes";
BA_DEF_DEF_  "NmNode" "No";
BA_DEF_DEF_REL_  "GenSigTimeoutTime" 0;
BA_DEF_DEF_  "DiagRequest" "No";
BA_DEF_DEF_  "DiagResponse" "No";
BA_DEF_DEF_  "DiagState" "No";
BA_DEF_DEF_  "GenMsgChkConstant" 0;
BA_DEF_DEF_  "GenMsgCycleTime" 0;
BA_DEF_DEF_  "GenMsgCycleTimeFast" 0;
BA_DEF_DEF_  "GenMsgDelayTime" 0;
BA_DEF_DEF_  "GenMsgILSupport" "No";
BA_DEF_DEF_  "GenMsgNrOfRepetition" 0;
BA_DEF_DEF_  "GenMsgPDUConstants" "";
BA_DEF_DEF_  "GenMsgSendType" "NoMsgSendType";
BA_DEF_DEF_  "GenMsgStartDelayTime" 0;
BA_DEF_DEF_  "NmMessage" "No";
BA_DEF_DEF_  "NmhMessage" "No";
BA_DEF_DEF_  "MsgType" "Application";
BA_DEF_DEF_  "VAGTP20_API" 0;
BA_DEF_DEF_  "VAGTP20_DynConnection" "No";
BA_DEF_DEF_  "VAGTP20_DynSetup" "No";
BA_DEF_DEF_  "VAGTP20_StatConnection" "No";
BA_DEF_DEF_  "GenSigActiveRepetitions" 0;
BA_DEF_DEF_  "GenSigInactiveValue" 0;
BA_DEF_DEF_  "GenSigSendType" "NoSigSendType";
BA_DEF_DEF_  "GenSigStartValue" 0;
BA_DEF_DEF_  "NWM-WakeupAllowed" "No";
BA_DEF_DEF_  "GenSigFuncType" "NoFunction";
BA_DEF_DEF_  "GenSigSwitchedByIgnition" "Yes";
BA_DEF_DEF_  "Fehlerwert" 0;
BA_DEF_DEF_  "GenSigMissingSourceValue" 0;
BA_  "DBName" "ICANHS";
BA_  "GenNWMApBusSleep" "NMIndNetSDN()";
BA_  "GenNWMApCanNormal" "apCanNormal()";
BA_  "GenNWMApCanOff" "NMIndnetOff()";
BA_  "GenNWMApCanOn" "NMIndnetOn()";
BA_  "GenNWMApCanSleep" "apCanSleep()";
BA_  "GenNWMApCanWakeUp" "apCanWakeUp()";
BA_  "GenNWMGotoMode_Awake" "Nmh_ReqNetOn()";
BA_  "GenNWMGotoMode_BusSleep" "Nmh_ReqNetOff()";
BA_  "GenNWMSleepTime" 4000;
BA_  "GenNWMTalkNM" "Nmh_ReqNetOn()";
BA_  "Manufacturer" "VAG";
BA_  "NmhBaseAddress" 452984832;
BA_  "NmhMessageCount" 1024;
BA_  "NmType" "NM-High";
BA_  "VAGTP20_SetupMessageCount" 128;
BA_  "VAGTP20_SetupStartAddress" 512;
BA_  "VersionNumber" 9;
BA_  "BusType" "CAN";
BA_  "Baudrate" 500000;
BA_  "SamplePointMin" 80;
BA_  "SamplePointMax" 84;
BA_  "SyncJumpWidthMin" 2;
BA_  "SyncJumpWidthMax" 4;
BA_  "NmhTimeoutTimer" 1000;
BA_  "NmhWaitBusSleepTimer" 750;
BA_  "NmhPrepareBusSleepTimer" 500;
BA_  "NmhLongTimer" 200;
BA_  "NmhNStart" 20;
BA_ "GenNodSleepTime" BU_ BAP_Tester 4000;
BA_ "ECUVariantGroup" BU_ BAP_Tester "BAP";
BA_ "NmhNode" BU_ BAP_Tester 0;
BA_ "GenNodSleepTime" BU_ BedienDisp_mi 4000;
BA_ "NodeLayerModules" BU_ BedienDisp_mi "NMHigh.DLL";
BA_ "GenNodSleepTime" BU_ BedienDisp_vo_mi 4000;
BA_ "NodeLayerModules" BU_ BedienDisp_vo_mi "NMHigh.DLL";
BA_ "GenNodSleepTime" BU_ CDI 4000;
BA_ "GenNodSleepTime" BU_ ConMod_CD 4000;
BA_ "NodeLayerModules" BU_ ConMod_CD "NMHigh.DLL";
BA_ "GenNodSleepTime" BU_ DashCAM 4000;
BA_ "GenNodSleepTime" BU_ Gateway_Max 4000;
BA_ "ECUVariantGroup" BU_ Gateway_Max "Gateway";
BA_ "NodeLayerModules" BU_ Gateway_Max "NMHigh.DLL";
BA_ "GenNodSleepTime" BU_ ICC_IO_Node 4000;
BA_ "NodeLayerModules" BU_ ICC_IO_Node "NMHigh.DLL";
BA_ "GenNodSleepTime" BU_ LSH 4000;
BA_ "NodeLayerModules" BU_ LSH "NMHigh.DLL";
BA_ "GenNodSleepTime" BU_ OCU 4000;
BA_ "NodeLayerModules" BU_ OCU "NMHigh.DLL";
BA_ "GenNodSleepTime" BU_ RDK_RS3 4000;
BA_ "ECUVariantGroup" BU_ RDK_RS3 "RDK";
BA_ "NodeLayerModules" BU_ RDK_RS3 "NMHigh.DLL";
BA_ "GenNodSleepTime" BU_ Sound_MIB_ab_Gen3 4000;
BA_ "GenNodSleepTime" BU_ STH 4000;
BA_ "NodeLayerModules" BU_ STH "NMHigh.DLL";
BA_ "GenNodSleepTime" BU_ ZR_MIB_EINSTIEG_ab_Gen3 4000;
BA_ "ECUVariantDefault" BU_ ZR_MIB_EINSTIEG_ab_Gen3 0;
BA_ "ECUVariantGroup" BU_ ZR_MIB_EINSTIEG_ab_Gen3 "ZR";
BA_ "NodeLayerModules" BU_ ZR_MIB_EINSTIEG_ab_Gen3 "NMHigh.DLL";
BA_ "GenNodSleepTime" BU_ ZR_MIB_OPTION_ab_Gen3 4000;
BA_ "ECUVariantDefault" BU_ ZR_MIB_OPTION_ab_Gen3 0;
BA_ "ECUVariantGroup" BU_ ZR_MIB_OPTION_ab_Gen3 "ZR";
BA_ "NodeLayerModules" BU_ ZR_MIB_OPTION_ab_Gen3 "NMHigh.DLL";
BA_ "GenNodSleepTime" BU_ ZR_MIB_TOP_ab_Gen3 4000;
BA_ "ECUVariantDefault" BU_ ZR_MIB_TOP_ab_Gen3 0;
BA_ "ECUVariantGroup" BU_ ZR_MIB_TOP_ab_Gen3 "ZR";
BA_ "NodeLayerModules" BU_ ZR_MIB_TOP_ab_Gen3 "NMHigh.DLL";
BA_ "GenMsgCycleTime" BO_ 2589283936 1000;
BA_ "GenMsgILSupport" BO_ 2589283936 1;
BA_ "GenMsgSendType" BO_ 2589283936 0;
BA_ "GenMsgCycleTime" BO_ 2589283937 1000;
BA_ "GenMsgILSupport" BO_ 2589283937 1;
BA_ "GenMsgSendType" BO_ 2589283937 0;
BA_ "GenMsgCycleTime" BO_ 2589283938 1000;
BA_ "GenMsgILSupport" BO_ 2589283938 1;
BA_ "GenMsgSendType" BO_ 2589283938 0;
BA_ "GenMsgCycleTime" BO_ 2589283939 1000;
BA_ "GenMsgCycleTimeFast" BO_ 2589283939 100;
BA_ "GenMsgDelayTime" BO_ 2589283939 50;
BA_ "GenMsgILSupport" BO_ 2589283939 1;
BA_ "GenMsgNrOfRepetition" BO_ 2589283939 5;
BA_ "GenMsgSendType" BO_ 2589283939 0;
BA_ "GenMsgCycleTime" BO_ 2589283940 1000;
BA_ "GenMsgCycleTimeFast" BO_ 2589283940 100;
BA_ "GenMsgDelayTime" BO_ 2589283940 50;
BA_ "GenMsgILSupport" BO_ 2589283940 1;
BA_ "GenMsgNrOfRepetition" BO_ 2589283940 5;
BA_ "GenMsgSendType" BO_ 2589283940 0;
BA_ "GenMsgCycleTime" BO_ 680 60;
BA_ "GenMsgILSupport" BO_ 680 1;
BA_ "GenMsgSendType" BO_ 680 0;
BA_ "GenMsgCycleTime" BO_ 1660 1000;
BA_ "GenMsgDelayTime" BO_ 1660 100;
BA_ "GenMsgILSupport" BO_ 1660 1;
BA_ "GenMsgSendType" BO_ 1660 0;
BA_ "GenMsgChkConstant" BO_ 64 64;
BA_ "GenMsgCycleTime" BO_ 64 40;
BA_ "GenMsgCycleTimeFast" BO_ 64 10;
BA_ "GenMsgDelayTime" BO_ 64 10;
BA_ "GenMsgILSupport" BO_ 64 1;
BA_ "GenMsgNrOfRepetition" BO_ 64 5;
BA_ "GenMsgPDUConstants" BO_ 64 "0x40,0x40,0x40,0x40,0x40,0x40,0x40,0x40,0x40,0x40,0x40,0x40,0x40,0x40,0x40,0x40";
BA_ "GenMsgSendType" BO_ 64 0;
BA_ "GenMsgChkConstant" BO_ 1312 68;
BA_ "GenMsgCycleTime" BO_ 1312 200;
BA_ "GenMsgDelayTime" BO_ 1312 20;
BA_ "GenMsgILSupport" BO_ 1312 1;
BA_ "GenMsgPDUConstants" BO_ 1312 "0x44,0x44,0x44,0x44,0x44,0x44,0x44,0x44,0x44,0x44,0x44,0x44,0x44,0x44,0x44,0x44";
BA_ "GenMsgSendType" BO_ 1312 0;
BA_ "GenMsgCycleTime" BO_ 65 1000;
BA_ "GenMsgCycleTimeFast" BO_ 65 10;
BA_ "GenMsgDelayTime" BO_ 65 10;
BA_ "GenMsgILSupport" BO_ 65 1;
BA_ "GenMsgNrOfRepetition" BO_ 65 5;
BA_ "GenMsgPDUConstants" BO_ 65 "0x93,0xb0,0x9d,0xf1,0x09,0xe8,0x88,0x5e,0x36,0xfa,0xa8,0xa1,0x67,0x84,0xca,0x4f";
BA_ "GenMsgSendType" BO_ 65 0;
BA_ "GenMsgCycleTime" BO_ 2527679722 200;
BA_ "GenMsgILSupport" BO_ 2527679722 1;
BA_ "GenMsgPDUConstants" BO_ 2527679722 "0x81,0x55,0xf0,0x94,0x56,0x5f,0xa4,0x5c,0x2f,0x61,0x48,0x01,0xf8,0xd7,0x33,0x87";
BA_ "GenMsgSendType" BO_ 2527679722 0;
BA_ "GenMsgCycleTime" BO_ 1633 100;
BA_ "GenMsgILSupport" BO_ 1633 1;
BA_ "GenMsgSendType" BO_ 1633 0;
BA_ "MsgType" BO_ 2549880935 4;
BA_ "MsgType" BO_ 2550012007 4;
BA_ "GenMsgCycleTimeFast" BO_ 2536703232 80;
BA_ "GenMsgSendType" BO_ 2536703232 7;
BA_ "MsgType" BO_ 2536703232 5;
BA_ "GenMsgCycleTimeFast" BO_ 2536703234 80;
BA_ "GenMsgSendType" BO_ 2536703234 7;
BA_ "MsgType" BO_ 2536703234 5;
BA_ "GenMsgCycleTime" BO_ 2536703248 1000;
BA_ "GenMsgCycleTimeFast" BO_ 2536703248 50;
BA_ "GenMsgSendType" BO_ 2536703248 7;
BA_ "MsgType" BO_ 2536703248 5;
BA_ "GenMsgCycleTimeFast" BO_ 2536714496 50;
BA_ "GenMsgSendType" BO_ 2536714496 7;
BA_ "MsgType" BO_ 2536714496 5;
BA_ "GenMsgCycleTimeFast" BO_ 2536714497 30;
BA_ "GenMsgSendType" BO_ 2536714497 7;
BA_ "MsgType" BO_ 2536714497 5;
BA_ "GenMsgCycleTimeFast" BO_ 2536714498 50;
BA_ "GenMsgSendType" BO_ 2536714498 7;
BA_ "MsgType" BO_ 2536714498 5;
BA_ "GenMsgCycleTimeFast" BO_ 2536714499 30;
BA_ "GenMsgSendType" BO_ 2536714499 7;
BA_ "MsgType" BO_ 2536714499 5;
BA_ "GenMsgCycleTimeFast" BO_ 2536714504 50;
BA_ "GenMsgSendType" BO_ 2536714504 7;
BA_ "MsgType" BO_ 2536714504 5;
BA_ "GenMsgCycleTimeFast" BO_ 2536714505 50;
BA_ "GenMsgSendType" BO_ 2536714505 7;
BA_ "MsgType" BO_ 2536714505 5;
BA_ "GenMsgCycleTimeFast" BO_ 2536714506 50;
BA_ "GenMsgSendType" BO_ 2536714506 7;
BA_ "MsgType" BO_ 2536714506 5;
BA_ "GenMsgCycleTimeFast" BO_ 2536714507 50;
BA_ "GenMsgSendType" BO_ 2536714507 7;
BA_ "MsgType" BO_ 2536714507 5;
BA_ "GenMsgCycleTime" BO_ 2536714512 1000;
BA_ "GenMsgCycleTimeFast" BO_ 2536714512 30;
BA_ "GenMsgSendType" BO_ 2536714512 7;
BA_ "MsgType" BO_ 2536714512 5;
BA_ "GenMsgCycleTime" BO_ 2536714513 1000;
BA_ "GenMsgCycleTimeFast" BO_ 2536714513 10;
BA_ "GenMsgSendType" BO_ 2536714513 7;
BA_ "MsgType" BO_ 2536714513 5;
BA_ "GenMsgCycleTimeFast" BO_ 2536704256 80;
BA_ "GenMsgSendType" BO_ 2536704256 7;
BA_ "MsgType" BO_ 2536704256 5;
BA_ "GenMsgCycleTimeFast" BO_ 2536704257 80;
BA_ "GenMsgSendType" BO_ 2536704257 7;
BA_ "MsgType" BO_ 2536704257 5;
BA_ "GenMsgCycleTime" BO_ 2536704272 1000;
BA_ "GenMsgCycleTimeFast" BO_ 2536704272 50;
BA_ "GenMsgSendType" BO_ 2536704272 7;
BA_ "MsgType" BO_ 2536704272 5;
BA_ "GenMsgCycleTimeFast" BO_ 2536708864 80;
BA_ "GenMsgSendType" BO_ 2536708864 7;
BA_ "MsgType" BO_ 2536708864 5;
BA_ "GenMsgCycleTimeFast" BO_ 2536708866 80;
BA_ "GenMsgSendType" BO_ 2536708866 7;
BA_ "MsgType" BO_ 2536708866 5;
BA_ "GenMsgCycleTime" BO_ 2536708880 1000;
BA_ "GenMsgCycleTimeFast" BO_ 2536708880 50;
BA_ "GenMsgSendType" BO_ 2536708880 7;
BA_ "MsgType" BO_ 2536708880 5;
BA_ "GenMsgCycleTimeFast" BO_ 2536711424 80;
BA_ "GenMsgSendType" BO_ 2536711424 7;
BA_ "MsgType" BO_ 2536711424 5;
BA_ "GenMsgCycleTimeFast" BO_ 2536711425 80;
BA_ "GenMsgSendType" BO_ 2536711425 7;
BA_ "MsgType" BO_ 2536711425 5;
BA_ "GenMsgCycleTime" BO_ 2536711440 1000;
BA_ "GenMsgCycleTimeFast" BO_ 2536711440 50;
BA_ "GenMsgSendType" BO_ 2536711440 7;
BA_ "MsgType" BO_ 2536711440 5;
BA_ "GenMsgCycleTimeFast" BO_ 2536705792 80;
BA_ "GenMsgSendType" BO_ 2536705792 7;
BA_ "MsgType" BO_ 2536705792 5;
BA_ "GenMsgCycleTimeFast" BO_ 2536705793 80;
BA_ "GenMsgSendType" BO_ 2536705793 7;
BA_ "MsgType" BO_ 2536705793 5;
BA_ "GenMsgCycleTime" BO_ 2536705808 1000;
BA_ "GenMsgCycleTimeFast" BO_ 2536705808 50;
BA_ "GenMsgSendType" BO_ 2536705808 7;
BA_ "MsgType" BO_ 2536705808 5;
BA_ "GenMsgCycleTime" BO_ 2536705809 1000;
BA_ "GenMsgCycleTimeFast" BO_ 2536705809 50;
BA_ "GenMsgSendType" BO_ 2536705809 7;
BA_ "MsgType" BO_ 2536705809 5;
BA_ "GenMsgCycleTimeFast" BO_ 2536710913 80;
BA_ "GenMsgSendType" BO_ 2536710913 7;
BA_ "MsgType" BO_ 2536710913 5;
BA_ "GenMsgCycleTime" BO_ 2536710928 1000;
BA_ "GenMsgCycleTimeFast" BO_ 2536710928 50;
BA_ "GenMsgSendType" BO_ 2536710928 7;
BA_ "MsgType" BO_ 2536710928 5;
BA_ "GenMsgCycleTimeFast" BO_ 2536711680 80;
BA_ "GenMsgSendType" BO_ 2536711680 7;
BA_ "MsgType" BO_ 2536711680 5;
BA_ "GenMsgCycleTime" BO_ 2536711696 1000;
BA_ "GenMsgCycleTimeFast" BO_ 2536711696 50;
BA_ "GenMsgSendType" BO_ 2536711696 7;
BA_ "MsgType" BO_ 2536711696 5;
BA_ "GenMsgCycleTimeFast" BO_ 2536733184 80;
BA_ "GenMsgSendType" BO_ 2536733184 7;
BA_ "MsgType" BO_ 2536733184 5;
BA_ "GenMsgCycleTime" BO_ 2536733200 1000;
BA_ "GenMsgCycleTimeFast" BO_ 2536733200 50;
BA_ "GenMsgSendType" BO_ 2536733200 7;
BA_ "MsgType" BO_ 2536733200 5;
BA_ "GenMsgCycleTimeFast" BO_ 2536733440 80;
BA_ "GenMsgSendType" BO_ 2536733440 7;
BA_ "MsgType" BO_ 2536733440 5;
BA_ "GenMsgCycleTime" BO_ 2536733456 1000;
BA_ "GenMsgCycleTimeFast" BO_ 2536733456 50;
BA_ "GenMsgSendType" BO_ 2536733456 7;
BA_ "MsgType" BO_ 2536733456 5;
BA_ "GenMsgCycleTimeFast" BO_ 2536732160 80;
BA_ "GenMsgSendType" BO_ 2536732160 7;
BA_ "MsgType" BO_ 2536732160 5;
BA_ "GenMsgCycleTime" BO_ 2536732176 1000;
BA_ "GenMsgCycleTimeFast" BO_ 2536732176 50;
BA_ "GenMsgSendType" BO_ 2536732176 7;
BA_ "MsgType" BO_ 2536732176 5;
BA_ "GenMsgCycleTimeFast" BO_ 2536734976 80;
BA_ "GenMsgSendType" BO_ 2536734976 7;
BA_ "MsgType" BO_ 2536734976 5;
BA_ "GenMsgCycleTime" BO_ 2536734992 1000;
BA_ "GenMsgCycleTimeFast" BO_ 2536734992 50;
BA_ "GenMsgSendType" BO_ 2536734992 7;
BA_ "MsgType" BO_ 2536734992 5;
BA_ "GenMsgCycleTimeFast" BO_ 2536726786 20;
BA_ "GenMsgSendType" BO_ 2536726786 7;
BA_ "MsgType" BO_ 2536726786 5;
BA_ "GenMsgCycleTime" BO_ 2536726802 1000;
BA_ "GenMsgCycleTimeFast" BO_ 2536726802 30;
BA_ "GenMsgSendType" BO_ 2536726802 7;
BA_ "MsgType" BO_ 2536726802 5;
BA_ "GenMsgCycleTimeFast" BO_ 2536707840 80;
BA_ "GenMsgSendType" BO_ 2536707840 7;
BA_ "MsgType" BO_ 2536707840 5;
BA_ "GenMsgCycleTimeFast" BO_ 2536707844 80;
BA_ "GenMsgSendType" BO_ 2536707844 7;
BA_ "MsgType" BO_ 2536707844 5;
BA_ "GenMsgCycleTime" BO_ 2536707856 1000;
BA_ "GenMsgCycleTimeFast" BO_ 2536707856 50;
BA_ "GenMsgSendType" BO_ 2536707856 7;
BA_ "MsgType" BO_ 2536707856 5;
BA_ "GenMsgCycleTimeFast" BO_ 2536726528 80;
BA_ "GenMsgSendType" BO_ 2536726528 7;
BA_ "MsgType" BO_ 2536726528 5;
BA_ "GenMsgCycleTime" BO_ 2536726544 1000;
BA_ "GenMsgCycleTimeFast" BO_ 2536726544 50;
BA_ "GenMsgSendType" BO_ 2536726544 7;
BA_ "MsgType" BO_ 2536726544 5;
BA_ "MsgType" BO_ 2536767264 5;
BA_ "MsgType" BO_ 2536767280 5;
BA_ "GenMsgCycleTimeFast" BO_ 2536719616 80;
BA_ "GenMsgSendType" BO_ 2536719616 7;
BA_ "MsgType" BO_ 2536719616 5;
BA_ "GenMsgCycleTimeFast" BO_ 2536719617 80;
BA_ "GenMsgSendType" BO_ 2536719617 7;
BA_ "MsgType" BO_ 2536719617 5;
BA_ "GenMsgCycleTime" BO_ 2536719632 1000;
BA_ "GenMsgCycleTimeFast" BO_ 2536719632 50;
BA_ "GenMsgSendType" BO_ 2536719632 7;
BA_ "MsgType" BO_ 2536719632 5;
BA_ "GenMsgCycleTimeFast" BO_ 2536705280 80;
BA_ "GenMsgSendType" BO_ 2536705280 7;
BA_ "MsgType" BO_ 2536705280 5;
BA_ "GenMsgCycleTimeFast" BO_ 2536705282 80;
BA_ "GenMsgSendType" BO_ 2536705282 7;
BA_ "MsgType" BO_ 2536705282 5;
BA_ "GenMsgCycleTime" BO_ 2536705296 1000;
BA_ "GenMsgCycleTimeFast" BO_ 2536705296 20;
BA_ "GenMsgSendType" BO_ 2536705296 7;
BA_ "MsgType" BO_ 2536705296 5;
BA_ "GenMsgCycleTimeFast" BO_ 2536727296 50;
BA_ "GenMsgSendType" BO_ 2536727296 7;
BA_ "MsgType" BO_ 2536727296 5;
BA_ "GenMsgCycleTime" BO_ 2536727312 1000;
BA_ "GenMsgCycleTimeFast" BO_ 2536727312 50;
BA_ "GenMsgSendType" BO_ 2536727312 7;
BA_ "MsgType" BO_ 2536727312 5;
BA_ "GenMsgCycleTimeFast" BO_ 2536724736 80;
BA_ "GenMsgSendType" BO_ 2536724736 7;
BA_ "MsgType" BO_ 2536724736 5;
BA_ "GenMsgCycleTime" BO_ 2536724752 1000;
BA_ "GenMsgCycleTimeFast" BO_ 2536724752 50;
BA_ "GenMsgSendType" BO_ 2536724752 7;
BA_ "MsgType" BO_ 2536724752 5;
BA_ "GenMsgCycleTimeFast" BO_ 2536734208 80;
BA_ "GenMsgSendType" BO_ 2536734208 7;
BA_ "MsgType" BO_ 2536734208 5;
BA_ "GenMsgCycleTime" BO_ 2536734224 1000;
BA_ "GenMsgCycleTimeFast" BO_ 2536734224 50;
BA_ "GenMsgSendType" BO_ 2536734224 7;
BA_ "MsgType" BO_ 2536734224 5;
BA_ "GenMsgCycleTimeFast" BO_ 2536715008 80;
BA_ "GenMsgSendType" BO_ 2536715008 7;
BA_ "MsgType" BO_ 2536715008 5;
BA_ "GenMsgCycleTime" BO_ 2536715024 1000;
BA_ "GenMsgCycleTimeFast" BO_ 2536715024 50;
BA_ "GenMsgSendType" BO_ 2536715024 7;
BA_ "MsgType" BO_ 2536715024 5;
BA_ "GenMsgCycleTimeFast" BO_ 2536717312 80;
BA_ "GenMsgSendType" BO_ 2536717312 7;
BA_ "MsgType" BO_ 2536717312 5;
BA_ "GenMsgCycleTime" BO_ 2536717328 1000;
BA_ "GenMsgCycleTimeFast" BO_ 2536717328 50;
BA_ "GenMsgSendType" BO_ 2536717328 7;
BA_ "MsgType" BO_ 2536717328 5;
BA_ "GenMsgCycleTimeFast" BO_ 2536706816 80;
BA_ "GenMsgSendType" BO_ 2536706816 7;
BA_ "MsgType" BO_ 2536706816 5;
BA_ "GenMsgCycleTimeFast" BO_ 2536706819 80;
BA_ "GenMsgSendType" BO_ 2536706819 7;
BA_ "MsgType" BO_ 2536706819 5;
BA_ "GenMsgCycleTime" BO_ 2536706832 1000;
BA_ "GenMsgCycleTimeFast" BO_ 2536706832 50;
BA_ "GenMsgSendType" BO_ 2536706832 7;
BA_ "MsgType" BO_ 2536706832 5;
BA_ "GenMsgCycleTimeFast" BO_ 2536725760 80;
BA_ "GenMsgSendType" BO_ 2536725760 7;
BA_ "MsgType" BO_ 2536725760 5;
BA_ "GenMsgCycleTime" BO_ 2536725776 1000;
BA_ "GenMsgCycleTimeFast" BO_ 2536725776 50;
BA_ "GenMsgSendType" BO_ 2536725776 7;
BA_ "MsgType" BO_ 2536725776 5;
BA_ "GenMsgCycleTimeFast" BO_ 2536724480 50;
BA_ "GenMsgSendType" BO_ 2536724480 7;
BA_ "MsgType" BO_ 2536724480 5;
BA_ "GenMsgCycleTimeFast" BO_ 2536724481 30;
BA_ "GenMsgSendType" BO_ 2536724481 7;
BA_ "MsgType" BO_ 2536724481 5;
BA_ "GenMsgCycleTime" BO_ 2536724496 1000;
BA_ "GenMsgCycleTimeFast" BO_ 2536724496 30;
BA_ "GenMsgSendType" BO_ 2536724496 7;
BA_ "MsgType" BO_ 2536724496 5;
BA_ "GenMsgCycleTime" BO_ 2536724497 1000;
BA_ "GenMsgCycleTimeFast" BO_ 2536724497 10;
BA_ "GenMsgSendType" BO_ 2536724497 7;
BA_ "MsgType" BO_ 2536724497 5;
BA_ "GenMsgCycleTimeFast" BO_ 2536730112 50;
BA_ "GenMsgSendType" BO_ 2536730112 7;
BA_ "MsgType" BO_ 2536730112 5;
BA_ "GenMsgCycleTimeFast" BO_ 2536730113 30;
BA_ "GenMsgSendType" BO_ 2536730113 7;
BA_ "MsgType" BO_ 2536730113 5;
BA_ "GenMsgCycleTime" BO_ 2536730128 1000;
BA_ "GenMsgCycleTimeFast" BO_ 2536730128 30;
BA_ "GenMsgSendType" BO_ 2536730128 7;
BA_ "MsgType" BO_ 2536730128 5;
BA_ "GenMsgCycleTime" BO_ 2536730129 1000;
BA_ "GenMsgCycleTimeFast" BO_ 2536730129 10;
BA_ "GenMsgSendType" BO_ 2536730129 7;
BA_ "MsgType" BO_ 2536730129 5;
BA_ "GenMsgCycleTimeFast" BO_ 2536716032 50;
BA_ "GenMsgSendType" BO_ 2536716032 7;
BA_ "MsgType" BO_ 2536716032 5;
BA_ "GenMsgCycleTimeFast" BO_ 2536716033 30;
BA_ "GenMsgSendType" BO_ 2536716033 7;
BA_ "MsgType" BO_ 2536716033 5;
BA_ "GenMsgCycleTime" BO_ 2536716048 1000;
BA_ "GenMsgCycleTimeFast" BO_ 2536716048 30;
BA_ "GenMsgSendType" BO_ 2536716048 7;
BA_ "MsgType" BO_ 2536716048 5;
BA_ "GenMsgCycleTime" BO_ 2536716049 1000;
BA_ "GenMsgCycleTimeFast" BO_ 2536716049 10;
BA_ "GenMsgSendType" BO_ 2536716049 7;
BA_ "MsgType" BO_ 2536716049 5;
BA_ "GenMsgCycleTimeFast" BO_ 2536721664 80;
BA_ "GenMsgSendType" BO_ 2536721664 7;
BA_ "MsgType" BO_ 2536721664 5;
BA_ "GenMsgCycleTime" BO_ 2536721680 1000;
BA_ "GenMsgCycleTimeFast" BO_ 2536721680 50;
BA_ "GenMsgSendType" BO_ 2536721680 7;
BA_ "MsgType" BO_ 2536721680 5;
BA_ "GenMsgCycleTimeFast" BO_ 2536707072 120;
BA_ "GenMsgSendType" BO_ 2536707072 7;
BA_ "MsgType" BO_ 2536707072 5;
BA_ "GenMsgCycleTime" BO_ 2536707088 1000;
BA_ "GenMsgCycleTimeFast" BO_ 2536707088 80;
BA_ "GenMsgSendType" BO_ 2536707088 7;
BA_ "MsgType" BO_ 2536707088 5;
BA_ "GenMsgCycleTimeFast" BO_ 2536702976 80;
BA_ "GenMsgSendType" BO_ 2536702976 7;
BA_ "MsgType" BO_ 2536702976 5;
BA_ "GenMsgCycleTimeFast" BO_ 2536702978 80;
BA_ "GenMsgSendType" BO_ 2536702978 7;
BA_ "MsgType" BO_ 2536702978 5;
BA_ "GenMsgCycleTime" BO_ 2536702992 1000;
BA_ "GenMsgCycleTimeFast" BO_ 2536702992 50;
BA_ "GenMsgSendType" BO_ 2536702992 7;
BA_ "MsgType" BO_ 2536702992 5;
BA_ "GenMsgCycleTimeFast" BO_ 2536709120 80;
BA_ "GenMsgSendType" BO_ 2536709120 7;
BA_ "MsgType" BO_ 2536709120 5;
BA_ "GenMsgCycleTime" BO_ 2536709136 1000;
BA_ "GenMsgCycleTimeFast" BO_ 2536709136 50;
BA_ "GenMsgSendType" BO_ 2536709136 7;
BA_ "MsgType" BO_ 2536709136 5;
BA_ "GenMsgCycleTimeFast" BO_ 2536722944 80;
BA_ "GenMsgSendType" BO_ 2536722944 7;
BA_ "MsgType" BO_ 2536722944 5;
BA_ "GenMsgCycleTimeFast" BO_ 2536722945 80;
BA_ "GenMsgSendType" BO_ 2536722945 7;
BA_ "MsgType" BO_ 2536722945 5;
BA_ "GenMsgCycleTimeFast" BO_ 2536722946 80;
BA_ "GenMsgSendType" BO_ 2536722946 7;
BA_ "MsgType" BO_ 2536722946 5;
BA_ "GenMsgCycleTime" BO_ 2536722960 1000;
BA_ "GenMsgCycleTimeFast" BO_ 2536722960 50;
BA_ "GenMsgSendType" BO_ 2536722960 7;
BA_ "MsgType" BO_ 2536722960 5;
BA_ "GenMsgCycleTimeFast" BO_ 2536722434 10;
BA_ "GenMsgSendType" BO_ 2536722434 7;
BA_ "MsgType" BO_ 2536722434 5;
BA_ "GenMsgCycleTime" BO_ 2536722448 1000;
BA_ "GenMsgCycleTimeFast" BO_ 2536722448 10;
BA_ "GenMsgSendType" BO_ 2536722448 7;
BA_ "MsgType" BO_ 2536722448 5;
BA_ "DiagState" BO_ 2536704000 1;
BA_ "GenMsgCycleTimeFast" BO_ 2536704000 80;
BA_ "GenMsgSendType" BO_ 2536704000 7;
BA_ "MsgType" BO_ 2536704000 5;
BA_ "GenMsgCycleTimeFast" BO_ 2536704001 50;
BA_ "GenMsgSendType" BO_ 2536704001 7;
BA_ "MsgType" BO_ 2536704001 5;
BA_ "GenMsgCycleTime" BO_ 2536704016 1000;
BA_ "GenMsgCycleTimeFast" BO_ 2536704016 50;
BA_ "GenMsgSendType" BO_ 2536704016 7;
BA_ "MsgType" BO_ 2536704016 5;
BA_ "GenMsgCycleTimeFast" BO_ 2536702208 80;
BA_ "GenMsgSendType" BO_ 2536702208 7;
BA_ "MsgType" BO_ 2536702208 5;
BA_ "GenMsgCycleTime" BO_ 2536702224 1000;
BA_ "GenMsgCycleTimeFast" BO_ 2536702224 50;
BA_ "GenMsgSendType" BO_ 2536702224 7;
BA_ "MsgType" BO_ 2536702224 5;
BA_ "GenMsgCycleTimeFast" BO_ 2536702464 80;
BA_ "GenMsgSendType" BO_ 2536702464 7;
BA_ "MsgType" BO_ 2536702464 5;
BA_ "GenMsgCycleTime" BO_ 2536702480 1000;
BA_ "GenMsgCycleTimeFast" BO_ 2536702480 50;
BA_ "GenMsgSendType" BO_ 2536702480 7;
BA_ "MsgType" BO_ 2536702480 5;
BA_ "GenMsgCycleTimeFast" BO_ 2536718848 80;
BA_ "GenMsgSendType" BO_ 2536718848 7;
BA_ "MsgType" BO_ 2536718848 5;
BA_ "GenMsgCycleTimeFast" BO_ 2536718849 80;
BA_ "GenMsgSendType" BO_ 2536718849 7;
BA_ "MsgType" BO_ 2536718849 5;
BA_ "GenMsgCycleTime" BO_ 2536718864 1000;
BA_ "GenMsgCycleTimeFast" BO_ 2536718864 50;
BA_ "GenMsgSendType" BO_ 2536718864 7;
BA_ "MsgType" BO_ 2536718864 5;
BA_ "GenMsgCycleTimeFast" BO_ 2536708352 80;
BA_ "GenMsgSendType" BO_ 2536708352 7;
BA_ "MsgType" BO_ 2536708352 5;
BA_ "GenMsgCycleTimeFast" BO_ 2536708354 80;
BA_ "GenMsgSendType" BO_ 2536708354 7;
BA_ "MsgType" BO_ 2536708354 5;
BA_ "GenMsgCycleTime" BO_ 2536708368 1000;
BA_ "GenMsgCycleTimeFast" BO_ 2536708368 50;
BA_ "GenMsgSendType" BO_ 2536708368 7;
BA_ "MsgType" BO_ 2536708368 5;
BA_ "GenMsgCycleTimeFast" BO_ 2536715264 80;
BA_ "GenMsgSendType" BO_ 2536715264 7;
BA_ "MsgType" BO_ 2536715264 5;
BA_ "GenMsgCycleTime" BO_ 2536715280 1000;
BA_ "GenMsgCycleTimeFast" BO_ 2536715280 50;
BA_ "GenMsgSendType" BO_ 2536715280 7;
BA_ "MsgType" BO_ 2536715280 5;
BA_ "GenMsgCycleTimeFast" BO_ 2536705536 80;
BA_ "GenMsgSendType" BO_ 2536705536 7;
BA_ "MsgType" BO_ 2536705536 5;
BA_ "GenMsgCycleTimeFast" BO_ 2536705537 80;
BA_ "GenMsgSendType" BO_ 2536705537 7;
BA_ "MsgType" BO_ 2536705537 5;
BA_ "GenMsgCycleTime" BO_ 2536705552 1000;
BA_ "GenMsgCycleTimeFast" BO_ 2536705552 50;
BA_ "GenMsgSendType" BO_ 2536705552 7;
BA_ "MsgType" BO_ 2536705552 5;
BA_ "GenMsgCycleTimeFast" BO_ 2536710656 80;
BA_ "GenMsgSendType" BO_ 2536710656 7;
BA_ "MsgType" BO_ 2536710656 5;
BA_ "GenMsgCycleTime" BO_ 2536710672 1000;
BA_ "GenMsgCycleTimeFast" BO_ 2536710672 50;
BA_ "GenMsgSendType" BO_ 2536710672 7;
BA_ "MsgType" BO_ 2536710672 5;
BA_ "GenMsgCycleTimeFast" BO_ 2536732416 80;
BA_ "GenMsgSendType" BO_ 2536732416 7;
BA_ "MsgType" BO_ 2536732416 5;
BA_ "GenMsgCycleTimeFast" BO_ 2536732417 80;
BA_ "GenMsgSendType" BO_ 2536732417 7;
BA_ "MsgType" BO_ 2536732417 5;
BA_ "GenMsgCycleTime" BO_ 2536732432 1000;
BA_ "GenMsgCycleTimeFast" BO_ 2536732432 50;
BA_ "GenMsgSendType" BO_ 2536732432 7;
BA_ "MsgType" BO_ 2536732432 5;
BA_ "GenMsgCycleTimeFast" BO_ 2536734464 80;
BA_ "GenMsgSendType" BO_ 2536734464 7;
BA_ "MsgType" BO_ 2536734464 5;
BA_ "GenMsgCycleTime" BO_ 2536734480 1000;
BA_ "GenMsgCycleTimeFast" BO_ 2536734480 50;
BA_ "GenMsgSendType" BO_ 2536734480 7;
BA_ "MsgType" BO_ 2536734480 5;
BA_ "GenMsgCycleTimeFast" BO_ 2536714752 30;
BA_ "GenMsgSendType" BO_ 2536714752 7;
BA_ "MsgType" BO_ 2536714752 5;
BA_ "GenMsgCycleTimeFast" BO_ 2536714753 50;
BA_ "GenMsgSendType" BO_ 2536714753 7;
BA_ "MsgType" BO_ 2536714753 5;
BA_ "GenMsgCycleTimeFast" BO_ 2536714754 30;
BA_ "GenMsgSendType" BO_ 2536714754 7;
BA_ "MsgType" BO_ 2536714754 5;
BA_ "GenMsgCycleTimeFast" BO_ 2536714755 50;
BA_ "GenMsgSendType" BO_ 2536714755 7;
BA_ "MsgType" BO_ 2536714755 5;
BA_ "GenMsgCycleTime" BO_ 2536714768 1000;
BA_ "GenMsgCycleTimeFast" BO_ 2536714768 30;
BA_ "GenMsgSendType" BO_ 2536714768 7;
BA_ "MsgType" BO_ 2536714768 5;
BA_ "GenMsgCycleTime" BO_ 2536714769 1000;
BA_ "GenMsgCycleTimeFast" BO_ 2536714769 10;
BA_ "GenMsgSendType" BO_ 2536714769 7;
BA_ "MsgType" BO_ 2536714769 5;
BA_ "GenMsgCycleTimeFast" BO_ 2536712704 80;
BA_ "GenMsgSendType" BO_ 2536712704 7;
BA_ "MsgType" BO_ 2536712704 5;
BA_ "GenMsgCycleTimeFast" BO_ 2536712705 80;
BA_ "GenMsgSendType" BO_ 2536712705 7;
BA_ "MsgType" BO_ 2536712705 5;
BA_ "GenMsgCycleTime" BO_ 2536712720 1000;
BA_ "GenMsgCycleTimeFast" BO_ 2536712720 50;
BA_ "GenMsgSendType" BO_ 2536712720 7;
BA_ "MsgType" BO_ 2536712720 5;
BA_ "GenMsgCycleTimeFast" BO_ 2536704512 80;
BA_ "GenMsgSendType" BO_ 2536704512 7;
BA_ "MsgType" BO_ 2536704512 5;
BA_ "GenMsgCycleTimeFast" BO_ 2536704516 80;
BA_ "GenMsgSendType" BO_ 2536704516 7;
BA_ "MsgType" BO_ 2536704516 5;
BA_ "GenMsgCycleTime" BO_ 2536704528 1000;
BA_ "GenMsgCycleTimeFast" BO_ 2536704528 50;
BA_ "GenMsgSendType" BO_ 2536704528 7;
BA_ "MsgType" BO_ 2536704528 5;
BA_ "GenMsgCycleTime" BO_ 2536704529 1000;
BA_ "GenMsgCycleTimeFast" BO_ 2536704529 50;
BA_ "GenMsgSendType" BO_ 2536704529 7;
BA_ "MsgType" BO_ 2536704529 5;
BA_ "GenMsgCycleTimeFast" BO_ 2536723712 20;
BA_ "GenMsgSendType" BO_ 2536723712 7;
BA_ "MsgType" BO_ 2536723712 5;
BA_ "GenMsgCycleTimeFast" BO_ 2536723714 80;
BA_ "GenMsgSendType" BO_ 2536723714 7;
BA_ "MsgType" BO_ 2536723714 5;
BA_ "GenMsgCycleTime" BO_ 2536723728 1000;
BA_ "GenMsgCycleTimeFast" BO_ 2536723728 20;
BA_ "GenMsgSendType" BO_ 2536723728 7;
BA_ "MsgType" BO_ 2536723728 5;
BA_ "GenMsgCycleTimeFast" BO_ 2536702720 80;
BA_ "GenMsgSendType" BO_ 2536702720 7;
BA_ "MsgType" BO_ 2536702720 5;
BA_ "GenMsgCycleTimeFast" BO_ 2536702721 80;
BA_ "GenMsgSendType" BO_ 2536702721 7;
BA_ "MsgType" BO_ 2536702721 5;
BA_ "GenMsgCycleTime" BO_ 2536702736 1000;
BA_ "GenMsgCycleTimeFast" BO_ 2536702736 50;
BA_ "GenMsgSendType" BO_ 2536702736 7;
BA_ "MsgType" BO_ 2536702736 5;
BA_ "GenMsgCycleTimeFast" BO_ 2536734721 80;
BA_ "GenMsgSendType" BO_ 2536734721 7;
BA_ "MsgType" BO_ 2536734721 5;
BA_ "GenMsgCycleTime" BO_ 2536734737 1000;
BA_ "GenMsgCycleTimeFast" BO_ 2536734737 50;
BA_ "GenMsgSendType" BO_ 2536734737 7;
BA_ "MsgType" BO_ 2536734737 5;
BA_ "GenMsgCycleTimeFast" BO_ 2536716544 80;
BA_ "GenMsgSendType" BO_ 2536716544 7;
BA_ "MsgType" BO_ 2536716544 5;
BA_ "GenMsgCycleTime" BO_ 2536716560 1000;
BA_ "GenMsgCycleTimeFast" BO_ 2536716560 50;
BA_ "GenMsgSendType" BO_ 2536716560 7;
BA_ "MsgType" BO_ 2536716560 5;
BA_ "GenMsgCycleTimeFast" BO_ 2536703744 80;
BA_ "GenMsgSendType" BO_ 2536703744 7;
BA_ "MsgType" BO_ 2536703744 5;
BA_ "GenMsgCycleTimeFast" BO_ 2536703745 80;
BA_ "GenMsgSendType" BO_ 2536703745 7;
BA_ "MsgType" BO_ 2536703745 5;
BA_ "GenMsgCycleTime" BO_ 2536703760 1000;
BA_ "GenMsgCycleTimeFast" BO_ 2536703760 50;
BA_ "GenMsgSendType" BO_ 2536703760 7;
BA_ "MsgType" BO_ 2536703760 5;
BA_ "GenMsgCycleTimeFast" BO_ 2536728320 80;
BA_ "GenMsgSendType" BO_ 2536728320 7;
BA_ "MsgType" BO_ 2536728320 5;
BA_ "GenMsgCycleTime" BO_ 2536728336 1000;
BA_ "GenMsgCycleTimeFast" BO_ 2536728336 30;
BA_ "GenMsgSendType" BO_ 2536728336 7;
BA_ "MsgType" BO_ 2536728336 5;
BA_ "GenMsgCycleTime" BO_ 2536728337 1000;
BA_ "GenMsgCycleTimeFast" BO_ 2536728337 10;
BA_ "GenMsgSendType" BO_ 2536728337 7;
BA_ "MsgType" BO_ 2536728337 5;
BA_ "GenMsgCycleTimeFast" BO_ 2536725248 80;
BA_ "GenMsgSendType" BO_ 2536725248 7;
BA_ "MsgType" BO_ 2536725248 5;
BA_ "GenMsgCycleTime" BO_ 2536725264 1000;
BA_ "GenMsgCycleTimeFast" BO_ 2536725264 50;
BA_ "GenMsgSendType" BO_ 2536725264 7;
BA_ "MsgType" BO_ 2536725264 5;
BA_ "GenMsgCycleTime" BO_ 2536725265 1000;
BA_ "GenMsgCycleTimeFast" BO_ 2536725265 20;
BA_ "GenMsgSendType" BO_ 2536725265 7;
BA_ "MsgType" BO_ 2536725265 5;
BA_ "GenMsgCycleTimeFast" BO_ 2536721920 80;
BA_ "GenMsgSendType" BO_ 2536721920 7;
BA_ "MsgType" BO_ 2536721920 5;
BA_ "GenMsgCycleTimeFast" BO_ 2536721921 80;
BA_ "GenMsgSendType" BO_ 2536721921 7;
BA_ "MsgType" BO_ 2536721921 5;
BA_ "GenMsgCycleTime" BO_ 2536721936 1000;
BA_ "GenMsgCycleTimeFast" BO_ 2536721936 50;
BA_ "GenMsgSendType" BO_ 2536721936 7;
BA_ "MsgType" BO_ 2536721936 5;
BA_ "GenMsgCycleTimeFast" BO_ 2536731904 80;
BA_ "GenMsgSendType" BO_ 2536731904 7;
BA_ "MsgType" BO_ 2536731904 5;
BA_ "GenMsgCycleTime" BO_ 2536731920 1000;
BA_ "GenMsgCycleTimeFast" BO_ 2536731920 50;
BA_ "GenMsgSendType" BO_ 2536731920 7;
BA_ "MsgType" BO_ 2536731920 5;
BA_ "GenMsgCycleTimeFast" BO_ 2536730624 80;
BA_ "GenMsgSendType" BO_ 2536730624 7;
BA_ "MsgType" BO_ 2536730624 5;
BA_ "GenMsgCycleTime" BO_ 2536730640 1000;
BA_ "GenMsgCycleTimeFast" BO_ 2536730640 50;
BA_ "GenMsgSendType" BO_ 2536730640 7;
BA_ "MsgType" BO_ 2536730640 5;
BA_ "GenMsgCycleTimeFast" BO_ 2536704768 80;
BA_ "GenMsgSendType" BO_ 2536704768 7;
BA_ "MsgType" BO_ 2536704768 5;
BA_ "GenMsgCycleTime" BO_ 2536704784 1000;
BA_ "GenMsgCycleTimeFast" BO_ 2536704784 50;
BA_ "GenMsgSendType" BO_ 2536704784 7;
BA_ "MsgType" BO_ 2536704784 5;
BA_ "GenMsgCycleTimeFast" BO_ 2536719872 80;
BA_ "GenMsgSendType" BO_ 2536719872 7;
BA_ "MsgType" BO_ 2536719872 5;
BA_ "GenMsgCycleTime" BO_ 2536719888 1000;
BA_ "GenMsgCycleTimeFast" BO_ 2536719888 50;
BA_ "GenMsgSendType" BO_ 2536719888 7;
BA_ "MsgType" BO_ 2536719888 5;
BA_ "GenMsgCycleTimeFast" BO_ 2536717056 80;
BA_ "GenMsgSendType" BO_ 2536717056 7;
BA_ "MsgType" BO_ 2536717056 5;
BA_ "GenMsgCycleTimeFast" BO_ 2536717057 80;
BA_ "GenMsgSendType" BO_ 2536717057 7;
BA_ "MsgType" BO_ 2536717057 5;
BA_ "GenMsgCycleTime" BO_ 2536717072 1000;
BA_ "GenMsgCycleTimeFast" BO_ 2536717072 50;
BA_ "GenMsgSendType" BO_ 2536717072 7;
BA_ "MsgType" BO_ 2536717072 5;
BA_ "GenMsgCycleTimeFast" BO_ 2536735488 80;
BA_ "GenMsgSendType" BO_ 2536735488 7;
BA_ "MsgType" BO_ 2536735488 5;
BA_ "GenSigSendType" SG_ 2589283936 AC_FES_Atmosphere_AMB_RGB_1 0;
BA_ "GenSigSwitchedByIgnition" SG_ 2589283936 AC_FES_Atmosphere_AMB_RGB_1 0;
BA_ "GenSigSendType" SG_ 2589283936 AC_FES_Atmosphere_AMB_RGB_2 0;
BA_ "GenSigSwitchedByIgnition" SG_ 2589283936 AC_FES_Atmosphere_AMB_RGB_2 0;
BA_ "GenSigSendType" SG_ 2589283937 AC_FES_Atmosphere_AMB_RGB_3 0;
BA_ "GenSigSwitchedByIgnition" SG_ 2589283937 AC_FES_Atmosphere_AMB_RGB_3 0;
BA_ "GenSigSendType" SG_ 2589283937 AC_FES_Atmosphere_AMB_RGB_4 0;
BA_ "GenSigSwitchedByIgnition" SG_ 2589283937 AC_FES_Atmosphere_AMB_RGB_4 0;
BA_ "GenSigSendType" SG_ 2589283938 AC_FES_Atmosphere_AMB_RGB_5 0;
BA_ "GenSigSwitchedByIgnition" SG_ 2589283938 AC_FES_Atmosphere_AMB_RGB_5 0;
BA_ "GenSigSendType" SG_ 2589283938 AC_FES_Atmosphere_AMB_RGB_6 0;
BA_ "GenSigSwitchedByIgnition" SG_ 2589283938 AC_FES_Atmosphere_AMB_RGB_6 0;
BA_ "GenSigSendType" SG_ 2589283939 AC_FES_Atmosphere_AMB_RGB_7 0;
BA_ "GenSigSwitchedByIgnition" SG_ 2589283939 AC_FES_Atmosphere_AMB_RGB_7 0;
BA_ "GenSigSendType" SG_ 2589283939 LC_FES_Aktive_Ebene_SOLL 4;
BA_ "GenSigSwitchedByIgnition" SG_ 2589283939 LC_FES_Aktive_Ebene_SOLL 0;
BA_ "GenSigSendType" SG_ 2589283939 LC_FES_Viewmode 4;
BA_ "GenSigSwitchedByIgnition" SG_ 2589283939 LC_FES_Viewmode 0;
BA_ "GenSigSendType" SG_ 2589283940 AC_FES_Aktive_Atmosphere 4;
BA_ "GenSigSwitchedByIgnition" SG_ 2589283940 AC_FES_Aktive_Atmosphere 0;
BA_ "GenSigSendType" SG_ 2589283940 AC_FES_Atmosphere_1 0;
BA_ "GenSigSwitchedByIgnition" SG_ 2589283940 AC_FES_Atmosphere_1 0;
BA_ "GenSigSendType" SG_ 2589283940 AC_FES_Atmosphere_2 0;
BA_ "GenSigSwitchedByIgnition" SG_ 2589283940 AC_FES_Atmosphere_2 0;
BA_ "GenSigSendType" SG_ 2589283940 AC_FES_Atmosphere_3 0;
BA_ "GenSigSwitchedByIgnition" SG_ 2589283940 AC_FES_Atmosphere_3 0;
BA_ "GenSigSendType" SG_ 2589283940 AC_FES_Atmosphere_4 0;
BA_ "GenSigSwitchedByIgnition" SG_ 2589283940 AC_FES_Atmosphere_4 0;
BA_ "GenSigSendType" SG_ 2589283940 AC_FES_Atmosphere_5 0;
BA_ "GenSigSwitchedByIgnition" SG_ 2589283940 AC_FES_Atmosphere_5 0;
BA_ "GenSigSendType" SG_ 2589283940 AC_FES_Atmosphere_6 0;
BA_ "GenSigSwitchedByIgnition" SG_ 2589283940 AC_FES_Atmosphere_6 0;
BA_ "GenSigSendType" SG_ 2589283940 AC_FES_Atmosphere_7 0;
BA_ "GenSigSwitchedByIgnition" SG_ 2589283940 AC_FES_Atmosphere_7 0;
BA_ "GenSigSendType" SG_ 2589283940 AC_KBI_Sec_View_Request 4;
BA_ "GenSigSwitchedByIgnition" SG_ 2589283940 AC_KBI_Sec_View_Request 0;
BA_ "GenSigSendType" SG_ 2589283940 AC_KBI_View_Request 4;
BA_ "GenSigSwitchedByIgnition" SG_ 2589283940 AC_KBI_View_Request 0;
BA_ "GenSigSendType" SG_ 680 AbstWarn_LRR_FAS_Fkt_Status 0;
BA_ "Fehlerwert" SG_ 680 AbstWarn_LRR_FAS_Fkt_Status 3;
BA_ "GenSigSendType" SG_ 680 ACA_Hinweistexte 0;
BA_ "GenSigSendType" SG_ 680 ACA_Querfuehrung_Texte 0;
BA_ "GenSigSendType" SG_ 680 ACC_Abstand_Abstandswarner 0;
BA_ "GenSigStartValue" SG_ 680 ACC_Abstand_Abstandswarner 511;
BA_ "GenSigSendType" SG_ 680 ACC_Akustik_03 0;
BA_ "GenSigSendType" SG_ 680 ACC_Einheit_Abstandswarner 0;
BA_ "GenSigSendType" SG_ 680 ACC_FoD_Status 0;
BA_ "GenSigSendType" SG_ 680 ACC_Geschw_Zielfahrzeug 0;
BA_ "NWM-WakeupAllowed" SG_ 680 ACC_Geschw_Zielfahrzeug 1;
BA_ "GenSigSendType" SG_ 680 ACC_STA_Text 0;
BA_ "GenSigSendType" SG_ 680 ACC_Status_Anzeige 0;
BA_ "GenSigSendType" SG_ 680 ACC_Status_Stauende 0;
BA_ "GenSigSwitchedByIgnition" SG_ 680 ACC_Status_Stauende 0;
BA_ "GenSigSendType" SG_ 680 ACC_Texte_02 0;
BA_ "GenSigSendType" SG_ 680 ACC_Texte_Abstandswarner 0;
BA_ "GenSigSendType" SG_ 680 ACC_Texte_Sekundaeranz 0;
BA_ "GenSigSendType" SG_ 680 ACC_Vorz_Abstandswarner 0;
BA_ "GenSigSendType" SG_ 680 ACC_Zeitluecke_Abstandswarner 0;
BA_ "GenSigStartValue" SG_ 680 ACC_Zeitluecke_Abstandswarner 63;
BA_ "GenSigSendType" SG_ 680 FAS_Licht_Anf 0;
BA_ "GenSigSendType" SG_ 680 STA_Texte 0;
BA_ "GenSigSendType" SG_ 680 STA_Zusatzanz 0;
BA_ "GenSigSendType" SG_ 1660 AGA_Charisma_FahrPr 3;
BA_ "GenSigSendType" SG_ 1660 AGA_Charisma_Status 3;
BA_ "GenSigSendType" SG_ 1660 AGA_ohne_Funktion 3;
BA_ "Fehlerwert" SG_ 1660 AGA_ohne_Funktion 1;
BA_ "GenSigSendType" SG_ 1660 AGA_Texte 3;
BA_ "GenSigSendType" SG_ 1660 AGA_Verstaerker_Mute 0;
BA_ "GenSigSwitchedByIgnition" SG_ 1660 AGA_Verstaerker_Mute 0;
BA_ "GenSigSendType" SG_ 1660 E_Sound_verbaut 0;
BA_ "GenSigSendType" SG_ 64 AB_Anzeige_Fussg 0;
BA_ "GenSigSwitchedByIgnition" SG_ 64 AB_Anzeige_Fussg 0;
BA_ "GenSigSendType" SG_ 64 AB_Belegung_VF 0;
BA_ "GenSigSwitchedByIgnition" SG_ 64 AB_Belegung_VF 0;
BA_ "Fehlerwert" SG_ 64 AB_Belegung_VF 1;
BA_ "GenSigSendType" SG_ 64 AB_Crash_Int 4;
BA_ "GenSigSwitchedByIgnition" SG_ 64 AB_Crash_Int 0;
BA_ "GenSigSendType" SG_ 64 AB_Deaktiviert 0;
BA_ "GenSigSwitchedByIgnition" SG_ 64 AB_Deaktiviert 0;
BA_ "GenSigSendType" SG_ 64 AB_Deaktivierung_HV 4;
BA_ "GenSigSwitchedByIgnition" SG_ 64 AB_Deaktivierung_HV 0;
BA_ "Fehlerwert" SG_ 64 AB_Deaktivierung_HV 7;
BA_ "GenSigSendType" SG_ 64 AB_Diagnose 0;
BA_ "GenSigSwitchedByIgnition" SG_ 64 AB_Diagnose 0;
BA_ "GenSigSendType" SG_ 64 AB_eCS_Error 0;
BA_ "GenSigSwitchedByIgnition" SG_ 64 AB_eCS_Error 0;
BA_ "GenSigSendType" SG_ 64 AB_EDR_Trigger 3;
BA_ "GenSigSwitchedByIgnition" SG_ 64 AB_EDR_Trigger 0;
BA_ "GenSigSendType" SG_ 64 AB_Erh_Auf_VB 0;
BA_ "GenSigSwitchedByIgnition" SG_ 64 AB_Erh_Auf_VB 0;
BA_ "GenSigSendType" SG_ 64 AB_Front_Crash 4;
BA_ "GenSigSwitchedByIgnition" SG_ 64 AB_Front_Crash 0;
BA_ "GenSigSendType" SG_ 64 AB_Gurtschloss_FA_ext 3;
BA_ "GenSigStartValue" SG_ 64 AB_Gurtschloss_FA_ext 6;
BA_ "GenSigSwitchedByIgnition" SG_ 64 AB_Gurtschloss_FA_ext 0;
BA_ "Fehlerwert" SG_ 64 AB_Gurtschloss_FA_ext 7;
BA_ "GenSigSendType" SG_ 64 AB_Gurtschloss_FA_ext_aktiv 0;
BA_ "GenSigSwitchedByIgnition" SG_ 64 AB_Gurtschloss_FA_ext_aktiv 0;
BA_ "GenSigSendType" SG_ 64 AB_Gurtwarn_VB 0;
BA_ "GenSigSwitchedByIgnition" SG_ 64 AB_Gurtwarn_VB 0;
BA_ "GenSigSendType" SG_ 64 AB_Gurtwarn_VF 0;
BA_ "GenSigSwitchedByIgnition" SG_ 64 AB_Gurtwarn_VF 0;
BA_ "GenSigSendType" SG_ 64 AB_Heck_Crash 4;
BA_ "GenSigSwitchedByIgnition" SG_ 64 AB_Heck_Crash 0;
BA_ "GenSigSendType" SG_ 64 AB_Lampe 0;
BA_ "GenSigStartValue" SG_ 64 AB_Lampe 1;
BA_ "GenSigSwitchedByIgnition" SG_ 64 AB_Lampe 0;
BA_ "GenSigSendType" SG_ 64 AB_MKB_Anforderung 4;
BA_ "GenSigSwitchedByIgnition" SG_ 64 AB_MKB_Anforderung 0;
BA_ "GenSigSendType" SG_ 64 AB_MKB_gueltig 0;
BA_ "GenSigSwitchedByIgnition" SG_ 64 AB_MKB_gueltig 0;
BA_ "GenSigSendType" SG_ 64 AB_PAO_Leuchte_Anf 0;
BA_ "GenSigStartValue" SG_ 64 AB_PAO_Leuchte_Anf 1;
BA_ "GenSigSwitchedByIgnition" SG_ 64 AB_PAO_Leuchte_Anf 0;
BA_ "GenSigSendType" SG_ 64 AB_RGS_Anst 3;
BA_ "GenSigStartValue" SG_ 64 AB_RGS_Anst 8;
BA_ "GenSigSwitchedByIgnition" SG_ 64 AB_RGS_Anst 0;
BA_ "GenSigSendType" SG_ 64 AB_Rollover_Crash 4;
BA_ "GenSigSwitchedByIgnition" SG_ 64 AB_Rollover_Crash 0;
BA_ "GenSigSendType" SG_ 64 AB_SB_Crash 4;
BA_ "GenSigSwitchedByIgnition" SG_ 64 AB_SB_Crash 0;
BA_ "GenSigSendType" SG_ 64 AB_SF_Crash 4;
BA_ "GenSigSwitchedByIgnition" SG_ 64 AB_SF_Crash 0;
BA_ "GenSigSendType" SG_ 64 AB_Stellgliedtest 0;
BA_ "GenSigSwitchedByIgnition" SG_ 64 AB_Stellgliedtest 0;
BA_ "GenSigSendType" SG_ 64 AB_Systemfehler 0;
BA_ "GenSigSwitchedByIgnition" SG_ 64 AB_Systemfehler 0;
BA_ "GenSigSendType" SG_ 64 AB_Texte_AKS 0;
BA_ "GenSigSwitchedByIgnition" SG_ 64 AB_Texte_AKS 0;
BA_ "GenSigSendType" SG_ 64 AB_VB_deaktiviert 0;
BA_ "GenSigStartValue" SG_ 64 AB_VB_deaktiviert 1;
BA_ "GenSigSwitchedByIgnition" SG_ 64 AB_VB_deaktiviert 0;
BA_ "GenSigSendType" SG_ 64 AB_Versorgungsspannung 0;
BA_ "GenSigSwitchedByIgnition" SG_ 64 AB_Versorgungsspannung 0;
BA_ "GenSigSendType" SG_ 64 Airbag_01_BZ 0;
BA_ "GenSigFuncType" SG_ 64 Airbag_01_BZ 1;
BA_ "GenSigSwitchedByIgnition" SG_ 64 Airbag_01_BZ 0;
BA_ "GenSigSendType" SG_ 64 Airbag_01_CRC 0;
BA_ "GenSigFuncType" SG_ 64 Airbag_01_CRC 2;
BA_ "GenSigSwitchedByIgnition" SG_ 64 Airbag_01_CRC 0;
BA_ "GenSigSendType" SG_ 64 ASM_Masterzeit_02 0;
BA_ "GenSigStartValue" SG_ 64 ASM_Masterzeit_02 255;
BA_ "GenSigSwitchedByIgnition" SG_ 64 ASM_Masterzeit_02 0;
BA_ "GenSigSendType" SG_ 1312 AB_Abschaltanf_SIH_BF 3;
BA_ "GenSigSendType" SG_ 1312 AB_Anforderung_eCall 0;
BA_ "GenSigSwitchedByIgnition" SG_ 1312 AB_Anforderung_eCall 0;
BA_ "GenSigSendType" SG_ 1312 AB_Anforderung_USM 0;
BA_ "GenSigSwitchedByIgnition" SG_ 1312 AB_Anforderung_USM 0;
BA_ "GenSigSendType" SG_ 1312 AB_Anprall_FGS 3;
BA_ "GenSigSendType" SG_ 1312 AB_Anprall_Front_Beifahrer 3;
BA_ "GenSigSendType" SG_ 1312 AB_Anprall_Front_Fahrer 3;
BA_ "GenSigSendType" SG_ 1312 AB_Anprall_Heck_Beifahrer 3;
BA_ "GenSigSendType" SG_ 1312 AB_Anprall_Heck_Fahrer 3;
BA_ "GenSigSendType" SG_ 1312 AB_Anprall_Rollover 3;
BA_ "GenSigSendType" SG_ 1312 AB_Anprall_Seite_Beifahrer 3;
BA_ "GenSigSendType" SG_ 1312 AB_Anprall_Seite_Fahrer 3;
BA_ "GenSigSendType" SG_ 1312 AB_Belegung_VB 0;
BA_ "GenSigSwitchedByIgnition" SG_ 1312 AB_Belegung_VB 0;
BA_ "Fehlerwert" SG_ 1312 AB_Belegung_VB 1;
BA_ "GenSigSendType" SG_ 1312 AB_Crashschwere 3;
BA_ "GenSigSwitchedByIgnition" SG_ 1312 AB_Crashschwere 0;
BA_ "Fehlerwert" SG_ 1312 AB_Crashschwere 7;
BA_ "GenSigSendType" SG_ 1312 AB_Gurtschloss_BF 3;
BA_ "GenSigStartValue" SG_ 1312 AB_Gurtschloss_BF 1;
BA_ "GenSigSwitchedByIgnition" SG_ 1312 AB_Gurtschloss_BF 0;
BA_ "GenSigSendType" SG_ 1312 AB_Gurtschloss_FA 3;
BA_ "GenSigStartValue" SG_ 1312 AB_Gurtschloss_FA 1;
BA_ "GenSigSwitchedByIgnition" SG_ 1312 AB_Gurtschloss_FA 0;
BA_ "GenSigSendType" SG_ 1312 AB_Gurtschloss_Reihe2_BF 3;
BA_ "GenSigStartValue" SG_ 1312 AB_Gurtschloss_Reihe2_BF 1;
BA_ "GenSigSwitchedByIgnition" SG_ 1312 AB_Gurtschloss_Reihe2_BF 0;
BA_ "GenSigSendType" SG_ 1312 AB_Gurtschloss_Reihe2_FA 3;
BA_ "GenSigStartValue" SG_ 1312 AB_Gurtschloss_Reihe2_FA 1;
BA_ "GenSigSwitchedByIgnition" SG_ 1312 AB_Gurtschloss_Reihe2_FA 0;
BA_ "GenSigSendType" SG_ 1312 AB_Gurtschloss_Reihe2_MI 3;
BA_ "GenSigStartValue" SG_ 1312 AB_Gurtschloss_Reihe2_MI 1;
BA_ "GenSigSwitchedByIgnition" SG_ 1312 AB_Gurtschloss_Reihe2_MI 0;
BA_ "GenSigSendType" SG_ 1312 AB_Gurtschloss_Reihe3_BF 3;
BA_ "GenSigStartValue" SG_ 1312 AB_Gurtschloss_Reihe3_BF 1;
BA_ "GenSigSwitchedByIgnition" SG_ 1312 AB_Gurtschloss_Reihe3_BF 0;
BA_ "GenSigSendType" SG_ 1312 AB_Gurtschloss_Reihe3_FA 3;
BA_ "GenSigStartValue" SG_ 1312 AB_Gurtschloss_Reihe3_FA 1;
BA_ "GenSigSwitchedByIgnition" SG_ 1312 AB_Gurtschloss_Reihe3_FA 0;
BA_ "GenSigSendType" SG_ 1312 AB_Gurtschloss_Reihe3_MI 3;
BA_ "GenSigStartValue" SG_ 1312 AB_Gurtschloss_Reihe3_MI 1;
BA_ "GenSigSwitchedByIgnition" SG_ 1312 AB_Gurtschloss_Reihe3_MI 0;
BA_ "GenSigSendType" SG_ 1312 AB_Sitzpos_Sens_BF 0;
BA_ "GenSigSwitchedByIgnition" SG_ 1312 AB_Sitzpos_Sens_BF 0;
BA_ "Fehlerwert" SG_ 1312 AB_Sitzpos_Sens_BF 1;
BA_ "GenSigSendType" SG_ 1312 AB_Sitzpos_Sens_FA 0;
BA_ "GenSigSwitchedByIgnition" SG_ 1312 AB_Sitzpos_Sens_FA 0;
BA_ "Fehlerwert" SG_ 1312 AB_Sitzpos_Sens_FA 1;
BA_ "GenSigSendType" SG_ 1312 AB_Wickelklappung_Reihe2_BF 3;
BA_ "GenSigStartValue" SG_ 1312 AB_Wickelklappung_Reihe2_BF 1;
BA_ "GenSigSwitchedByIgnition" SG_ 1312 AB_Wickelklappung_Reihe2_BF 0;
BA_ "GenSigSendType" SG_ 1312 AB_Wickelklappung_Reihe2_FA 3;
BA_ "GenSigStartValue" SG_ 1312 AB_Wickelklappung_Reihe2_FA 1;
BA_ "GenSigSwitchedByIgnition" SG_ 1312 AB_Wickelklappung_Reihe2_FA 0;
BA_ "GenSigSendType" SG_ 1312 AB_Wickelklappung_Reihe2_MI 3;
BA_ "GenSigStartValue" SG_ 1312 AB_Wickelklappung_Reihe2_MI 1;
BA_ "GenSigSwitchedByIgnition" SG_ 1312 AB_Wickelklappung_Reihe2_MI 0;
BA_ "GenSigSendType" SG_ 1312 Airbag_02_BZ 0;
BA_ "GenSigFuncType" SG_ 1312 Airbag_02_BZ 1;
BA_ "GenSigSwitchedByIgnition" SG_ 1312 Airbag_02_BZ 0;
BA_ "GenSigSendType" SG_ 1312 Airbag_02_CRC 0;
BA_ "GenSigFuncType" SG_ 1312 Airbag_02_CRC 2;
BA_ "GenSigSwitchedByIgnition" SG_ 1312 Airbag_02_CRC 0;
BA_ "GenSigSendType" SG_ 1312 LoGeWa_Event_Kombiwarnung 3;
BA_ "GenSigSwitchedByIgnition" SG_ 1312 LoGeWa_Event_Kombiwarnung 0;
BA_ "GenSigSendType" SG_ 1312 SC_PAO_OFF_Anf 3;
BA_ "GenSigSwitchedByIgnition" SG_ 1312 SC_PAO_OFF_Anf 0;
BA_ "GenSigSendType" SG_ 1312 SC_PAO_ON_Anf 3;
BA_ "GenSigSwitchedByIgnition" SG_ 1312 SC_PAO_ON_Anf 0;
BA_ "GenSigSendType" SG_ 1312 SC_PAO_Schriftzug_Anf 3;
BA_ "GenSigSwitchedByIgnition" SG_ 1312 SC_PAO_Schriftzug_Anf 0;
BA_ "GenSigSendType" SG_ 65 AB_DeltaV_X_eCall 0;
BA_ "GenSigSwitchedByIgnition" SG_ 65 AB_DeltaV_X_eCall 0;
BA_ "GenSigSendType" SG_ 65 AB_DeltaV_Y_eCall 0;
BA_ "GenSigSwitchedByIgnition" SG_ 65 AB_DeltaV_Y_eCall 0;
BA_ "GenSigSendType" SG_ 65 AB_MKB_Safing 4;
BA_ "GenSigSwitchedByIgnition" SG_ 65 AB_MKB_Safing 0;
BA_ "GenSigSendType" SG_ 65 Airbag_03_BZ 0;
BA_ "GenSigFuncType" SG_ 65 Airbag_03_BZ 1;
BA_ "GenSigSwitchedByIgnition" SG_ 65 Airbag_03_BZ 0;
BA_ "GenSigSendType" SG_ 65 Airbag_03_CRC 0;
BA_ "GenSigFuncType" SG_ 65 Airbag_03_CRC 2;
BA_ "GenSigSwitchedByIgnition" SG_ 65 Airbag_03_CRC 0;
BA_ "GenSigSendType" SG_ 2527679722 AB_Anzeige_Kombi_SRAB 0;
BA_ "GenSigSendType" SG_ 2527679722 AB_Anzeige_Komfort_HBFS 0;
BA_ "GenSigSendType" SG_ 2527679722 AB_Anzeige_Komfort_HFS 0;
BA_ "GenSigSendType" SG_ 2527679722 AB_Anzeige_Sitz_Komfort_HBFS 0;
BA_ "GenSigSendType" SG_ 2527679722 AB_Anzeige_Sitz_Komfort_HFS 0;
BA_ "GenSigSendType" SG_ 2527679722 AB_Gurtschloss_MI 0;
BA_ "GenSigStartValue" SG_ 2527679722 AB_Gurtschloss_MI 1;
BA_ "GenSigSwitchedByIgnition" SG_ 2527679722 AB_Gurtschloss_MI 0;
BA_ "GenSigSendType" SG_ 2527679722 AB_Gurtschloss_Reihe4_BF 0;
BA_ "GenSigStartValue" SG_ 2527679722 AB_Gurtschloss_Reihe4_BF 1;
BA_ "GenSigSwitchedByIgnition" SG_ 2527679722 AB_Gurtschloss_Reihe4_BF 0;
BA_ "GenSigSendType" SG_ 2527679722 AB_Gurtschloss_Reihe4_FA 0;
BA_ "GenSigStartValue" SG_ 2527679722 AB_Gurtschloss_Reihe4_FA 1;
BA_ "GenSigSwitchedByIgnition" SG_ 2527679722 AB_Gurtschloss_Reihe4_FA 0;
BA_ "GenSigSendType" SG_ 2527679722 AB_Gurtschloss_Reihe4_MI 0;
BA_ "GenSigStartValue" SG_ 2527679722 AB_Gurtschloss_Reihe4_MI 1;
BA_ "GenSigSwitchedByIgnition" SG_ 2527679722 AB_Gurtschloss_Reihe4_MI 0;
BA_ "GenSigSendType" SG_ 2527679722 AB_Gurtwarn_VM 0;
BA_ "GenSigSwitchedByIgnition" SG_ 2527679722 AB_Gurtwarn_VM 0;
BA_ "GenSigSendType" SG_ 2527679722 AB_Status_Sitz_SRAB_HBFS 0;
BA_ "GenSigStartValue" SG_ 2527679722 AB_Status_Sitz_SRAB_HBFS 2;
BA_ "GenSigSwitchedByIgnition" SG_ 2527679722 AB_Status_Sitz_SRAB_HBFS 0;
BA_ "Fehlerwert" SG_ 2527679722 AB_Status_Sitz_SRAB_HBFS 3;
BA_ "GenSigSendType" SG_ 2527679722 AB_Status_Sitz_SRAB_HFS 0;
BA_ "GenSigStartValue" SG_ 2527679722 AB_Status_Sitz_SRAB_HFS 2;
BA_ "Fehlerwert" SG_ 2527679722 AB_Status_Sitz_SRAB_HFS 3;
BA_ "GenSigSendType" SG_ 2527679722 AB_wSBR_Batteriestatus 0;
BA_ "GenSigSwitchedByIgnition" SG_ 2527679722 AB_wSBR_Batteriestatus 0;
BA_ "GenSigSendType" SG_ 2527679722 Airbag_06_BZ 0;
BA_ "GenSigFuncType" SG_ 2527679722 Airbag_06_BZ 1;
BA_ "GenSigSwitchedByIgnition" SG_ 2527679722 Airbag_06_BZ 0;
BA_ "GenSigSendType" SG_ 2527679722 Airbag_06_CRC 0;
BA_ "GenSigFuncType" SG_ 2527679722 Airbag_06_CRC 2;
BA_ "GenSigSwitchedByIgnition" SG_ 2527679722 Airbag_06_CRC 0;
BA_ "GenSigSendType" SG_ 1633 AAG_Anhaenger_abgesteckt 0;
BA_ "GenSigSwitchedByIgnition" SG_ 1633 AAG_Anhaenger_abgesteckt 0;
BA_ "GenSigSendType" SG_ 1633 AAG_Anhaenger_erkannt 0;
BA_ "NWM-WakeupAllowed" SG_ 1633 AAG_Anhaenger_erkannt 1;
BA_ "GenSigSwitchedByIgnition" SG_ 1633 AAG_Anhaenger_erkannt 0;
BA_ "GenSigSendType" SG_ 1633 AAG_AVS_Fehler_02 0;
BA_ "GenSigSwitchedByIgnition" SG_ 1633 AAG_AVS_Fehler_02 0;
BA_ "Fehlerwert" SG_ 1633 AAG_AVS_Fehler_02 1;
BA_ "GenSigSendType" SG_ 1633 AAG_AVS_Fehler_02_inv 0;
BA_ "GenSigStartValue" SG_ 1633 AAG_AVS_Fehler_02_inv 1;
BA_ "GenSigSwitchedByIgnition" SG_ 1633 AAG_AVS_Fehler_02_inv 0;
BA_ "GenSigSendType" SG_ 1633 AAG_AVS_Stati 0;
BA_ "GenSigSwitchedByIgnition" SG_ 1633 AAG_AVS_Stati 0;
BA_ "GenSigSendType" SG_ 1633 AAG_Blinker_H_aktiv 0;
BA_ "GenSigSwitchedByIgnition" SG_ 1633 AAG_Blinker_H_aktiv 0;
BA_ "GenSigSendType" SG_ 1633 AAG_Blinker_HL_def 0;
BA_ "GenSigSwitchedByIgnition" SG_ 1633 AAG_Blinker_HL_def 0;
BA_ "GenSigSendType" SG_ 1633 AAG_Blinker_HR_def 0;
BA_ "GenSigSwitchedByIgnition" SG_ 1633 AAG_Blinker_HR_def 0;
BA_ "GenSigSendType" SG_ 1633 AAG_Bremsl_durch_ECD 0;
BA_ "GenSigSwitchedByIgnition" SG_ 1633 AAG_Bremsl_durch_ECD 0;
BA_ "GenSigSendType" SG_ 1633 AAG_Bremslicht_H_def 0;
BA_ "GenSigSwitchedByIgnition" SG_ 1633 AAG_Bremslicht_H_def 0;
BA_ "GenSigSendType" SG_ 1633 AAG_Bremslicht_Reku 0;
BA_ "GenSigSwitchedByIgnition" SG_ 1633 AAG_Bremslicht_Reku 0;
BA_ "GenSigSendType" SG_ 1633 AAG_BZ 0;
BA_ "GenSigFuncType" SG_ 1633 AAG_BZ 1;
BA_ "GenSigSwitchedByIgnition" SG_ 1633 AAG_BZ 0;
BA_ "GenSigSendType" SG_ 1633 AAG_LED_aktiv 0;
BA_ "GenSigSwitchedByIgnition" SG_ 1633 AAG_LED_aktiv 0;
BA_ "GenSigSendType" SG_ 1633 AAG_NSL_aktiv 0;
BA_ "GenSigSwitchedByIgnition" SG_ 1633 AAG_NSL_aktiv 0;
BA_ "GenSigSendType" SG_ 1633 AAG_Schlusslicht_HL_def 0;
BA_ "GenSigSwitchedByIgnition" SG_ 1633 AAG_Schlusslicht_HL_def 0;
BA_ "GenSigSendType" SG_ 1633 AAG_Schlusslicht_HR_def 0;
BA_ "GenSigSwitchedByIgnition" SG_ 1633 AAG_Schlusslicht_HR_def 0;
BA_ "GenSigSendType" SG_ 2549880935 AuthTime_eCall_Req_Data 3;
BA_ "GenSigFuncType" SG_ 2549880935 AuthTime_eCall_Req_Data 9;
BA_ "GenSigSwitchedByIgnition" SG_ 2549880935 AuthTime_eCall_Req_Data 0;
BA_ "GenSigSendType" SG_ 2550012007 AuthTime_eCall_Resp_Data 3;
BA_ "GenSigFuncType" SG_ 2550012007 AuthTime_eCall_Resp_Data 9;
BA_ "GenSigSwitchedByIgnition" SG_ 2550012007 AuthTime_eCall_Resp_Data 0;
BA_ "GenSigSendType" SG_ 2536703232 BAP_ACC_ASG_01_Header 3;
BA_ "GenSigSwitchedByIgnition" SG_ 2536703232 BAP_ACC_ASG_01_Header 0;
BA_ "GenSigSendType" SG_ 2536703234 BAP_ACC_ASG_03_Header 3;
BA_ "GenSigSwitchedByIgnition" SG_ 2536703234 BAP_ACC_ASG_03_Header 0;
BA_ "GenSigSendType" SG_ 2536703248 BAP_ACC_FSG_01_Header 3;
BA_ "GenSigSwitchedByIgnition" SG_ 2536703248 BAP_ACC_FSG_01_Header 0;
BA_ "GenSigSendType" SG_ 2536714496 BAP_Audio_ASG_01_Header 3;
BA_ "GenSigSwitchedByIgnition" SG_ 2536714496 BAP_Audio_ASG_01_Header 0;
BA_ "GenSigSendType" SG_ 2536714497 BAP_Audio_ASG_02_Header 3;
BA_ "GenSigSwitchedByIgnition" SG_ 2536714497 BAP_Audio_ASG_02_Header 0;
BA_ "GenSigSendType" SG_ 2536714498 BAP_Audio_ASG_03_Header 3;
BA_ "GenSigSwitchedByIgnition" SG_ 2536714498 BAP_Audio_ASG_03_Header 0;
BA_ "GenSigSendType" SG_ 2536714499 BAP_Audio_ASG_04_Header 3;
BA_ "GenSigSwitchedByIgnition" SG_ 2536714499 BAP_Audio_ASG_04_Header 0;
BA_ "GenSigSendType" SG_ 2536714504 BAP_Audio_ASG_09_Header 3;
BA_ "GenSigSwitchedByIgnition" SG_ 2536714504 BAP_Audio_ASG_09_Header 0;
BA_ "GenSigSendType" SG_ 2536714505 BAP_Audio_ASG_10_Header 3;
BA_ "GenSigSwitchedByIgnition" SG_ 2536714505 BAP_Audio_ASG_10_Header 0;
BA_ "GenSigSendType" SG_ 2536714506 BAP_Audio_ASG_11_Header 3;
BA_ "GenSigSwitchedByIgnition" SG_ 2536714506 BAP_Audio_ASG_11_Header 0;
BA_ "GenSigSendType" SG_ 2536714507 BAP_Audio_ASG_12_Header 3;
BA_ "GenSigSwitchedByIgnition" SG_ 2536714507 BAP_Audio_ASG_12_Header 0;
BA_ "GenSigSendType" SG_ 2536714512 BAP_Audio_FSG_01_Header 3;
BA_ "GenSigSwitchedByIgnition" SG_ 2536714512 BAP_Audio_FSG_01_Header 0;
BA_ "GenSigSendType" SG_ 2536714513 BAP_Audio_FSG_02_Header 3;
BA_ "GenSigSwitchedByIgnition" SG_ 2536714513 BAP_Audio_FSG_02_Header 0;
BA_ "GenSigSendType" SG_ 2536704256 BAP_Aussenlicht_ASG_01_Header 3;
BA_ "GenSigSwitchedByIgnition" SG_ 2536704256 BAP_Aussenlicht_ASG_01_Header 0;
BA_ "GenSigSendType" SG_ 2536704257 BAP_Aussenlicht_ASG_02_Header 3;
BA_ "GenSigSwitchedByIgnition" SG_ 2536704257 BAP_Aussenlicht_ASG_02_Header 0;
BA_ "GenSigSendType" SG_ 2536704272 BAP_Aussenlicht_FSG_01_Header 3;
BA_ "GenSigSwitchedByIgnition" SG_ 2536704272 BAP_Aussenlicht_FSG_01_Header 0;
BA_ "GenSigSendType" SG_ 2536708864 BAP_AWV_ASG_01_Header 3;
BA_ "GenSigSwitchedByIgnition" SG_ 2536708864 BAP_AWV_ASG_01_Header 0;
BA_ "GenSigSendType" SG_ 2536708866 BAP_AWV_ASG_03_Header 3;
BA_ "GenSigSwitchedByIgnition" SG_ 2536708866 BAP_AWV_ASG_03_Header 0;
BA_ "GenSigSendType" SG_ 2536708880 BAP_AWV_FSG_01_Header 3;
BA_ "GenSigSwitchedByIgnition" SG_ 2536708880 BAP_AWV_FSG_01_Header 0;
BA_ "GenSigSendType" SG_ 2536711424 BAP_BatteryControl_ASG_01_Header 3;
BA_ "GenSigSwitchedByIgnition" SG_ 2536711424 BAP_BatteryControl_ASG_01_Header 0;
BA_ "GenSigSendType" SG_ 2536711425 BAP_BatteryControl_ASG_02_Header 3;
BA_ "GenSigSwitchedByIgnition" SG_ 2536711425 BAP_BatteryControl_ASG_02_Header 0;
BA_ "GenSigSendType" SG_ 2536711440 BAP_BatteryControl_FSG_01_Header 3;
BA_ "GenSigSwitchedByIgnition" SG_ 2536711440 BAP_BatteryControl_FSG_01_Header 0;
BA_ "GenSigSendType" SG_ 2536705792 BAP_BC_ASG_01_Header 3;
BA_ "GenSigSwitchedByIgnition" SG_ 2536705792 BAP_BC_ASG_01_Header 0;
BA_ "GenSigSendType" SG_ 2536705793 BAP_BC_ASG_02_Header 3;
BA_ "GenSigSwitchedByIgnition" SG_ 2536705793 BAP_BC_ASG_02_Header 0;
BA_ "GenSigSendType" SG_ 2536705808 BAP_BC_FSG_01_Header 3;
BA_ "GenSigSwitchedByIgnition" SG_ 2536705808 BAP_BC_FSG_01_Header 0;
BA_ "GenSigSendType" SG_ 2536705809 BAP_BC_FSG_02_Header 3;
BA_ "GenSigSwitchedByIgnition" SG_ 2536705809 BAP_BC_FSG_02_Header 0;
BA_ "GenSigSendType" SG_ 2536710913 BAP_BCmE_ASG_02_Header 3;
BA_ "GenSigSwitchedByIgnition" SG_ 2536710913 BAP_BCmE_ASG_02_Header 0;
BA_ "GenSigSendType" SG_ 2536710928 BAP_BCmE_FSG_01_Header 3;
BA_ "GenSigSwitchedByIgnition" SG_ 2536710928 BAP_BCmE_FSG_01_Header 0;
BA_ "GenSigSendType" SG_ 2536711680 BAP_Brake_ASG_01_Header 3;
BA_ "GenSigSwitchedByIgnition" SG_ 2536711680 BAP_Brake_ASG_01_Header 0;
BA_ "GenSigSendType" SG_ 2536711696 BAP_Brake_FSG_01_Header 3;
BA_ "GenSigSwitchedByIgnition" SG_ 2536711696 BAP_Brake_FSG_01_Header 0;
BA_ "GenSigSendType" SG_ 2536733184 BAP_BSMOIS2_ASG_01_Header 3;
BA_ "GenSigSwitchedByIgnition" SG_ 2536733184 BAP_BSMOIS2_ASG_01_Header 0;
BA_ "GenSigSendType" SG_ 2536733200 BAP_BSMOIS2_FSG_01_Header 3;
BA_ "GenSigSwitchedByIgnition" SG_ 2536733200 BAP_BSMOIS2_FSG_01_Header 0;
BA_ "GenSigSendType" SG_ 2536733440 BAP_BSMOIS3_ASG_01_Header 3;
BA_ "GenSigSwitchedByIgnition" SG_ 2536733440 BAP_BSMOIS3_ASG_01_Header 0;
BA_ "GenSigSendType" SG_ 2536733456 BAP_BSMOIS3_FSG_01_Header 3;
BA_ "GenSigSwitchedByIgnition" SG_ 2536733456 BAP_BSMOIS3_FSG_01_Header 0;
BA_ "GenSigSendType" SG_ 2536732160 BAP_BSMOIS_ASG_01_Header 3;
BA_ "GenSigSwitchedByIgnition" SG_ 2536732160 BAP_BSMOIS_ASG_01_Header 0;
BA_ "GenSigSendType" SG_ 2536732176 BAP_BSMOIS_FSG_01_Header 3;
BA_ "GenSigSwitchedByIgnition" SG_ 2536732176 BAP_BSMOIS_FSG_01_Header 0;
BA_ "GenSigSendType" SG_ 2536734976 BAP_California_ASG_01_Header 3;
BA_ "GenSigSwitchedByIgnition" SG_ 2536734976 BAP_California_ASG_01_Header 0;
BA_ "GenSigSendType" SG_ 2536734992 BAP_California_FSG_01_Header 3;
BA_ "GenSigSwitchedByIgnition" SG_ 2536734992 BAP_California_FSG_01_Header 0;
BA_ "GenSigSendType" SG_ 2536726786 BAP_Car2X_ASG_03_Header 3;
BA_ "GenSigSwitchedByIgnition" SG_ 2536726786 BAP_Car2X_ASG_03_Header 0;
BA_ "GenSigSendType" SG_ 2536726802 BAP_Car2X_FSG_03_Header 3;
BA_ "GenSigSwitchedByIgnition" SG_ 2536726802 BAP_Car2X_FSG_03_Header 0;
BA_ "GenSigSendType" SG_ 2536707840 BAP_Charisma_ASG_01_Header 3;
BA_ "GenSigSwitchedByIgnition" SG_ 2536707840 BAP_Charisma_ASG_01_Header 0;
BA_ "GenSigSendType" SG_ 2536707844 BAP_Charisma_ASG_05_Header 3;
BA_ "GenSigSwitchedByIgnition" SG_ 2536707844 BAP_Charisma_ASG_05_Header 0;
BA_ "GenSigSendType" SG_ 2536707856 BAP_Charisma_FSG_01_Header 3;
BA_ "GenSigSwitchedByIgnition" SG_ 2536707856 BAP_Charisma_FSG_01_Header 0;
BA_ "GenSigSendType" SG_ 2536726528 BAP_ClimateDiag_ASG_01_Header 3;
BA_ "GenSigSwitchedByIgnition" SG_ 2536726528 BAP_ClimateDiag_ASG_01_Header 0;
BA_ "GenSigSendType" SG_ 2536726544 BAP_ClimateDiag_FSG_01_Header 3;
BA_ "GenSigSwitchedByIgnition" SG_ 2536726544 BAP_ClimateDiag_FSG_01_Header 0;
BA_ "GenSigSendType" SG_ 2536767264 BAP_Debug_Cmd 3;
BA_ "GenSigSwitchedByIgnition" SG_ 2536767264 BAP_Debug_Cmd 0;
BA_ "GenSigSendType" SG_ 2536767280 BAP_Debug_Data 3;
BA_ "GenSigSwitchedByIgnition" SG_ 2536767280 BAP_Debug_Data 0;
BA_ "GenSigSendType" SG_ 2536719616 BAP_DisplayConfig_ASG_01_Header 3;
BA_ "GenSigSwitchedByIgnition" SG_ 2536719616 BAP_DisplayConfig_ASG_01_Header 0;
BA_ "GenSigSendType" SG_ 2536719617 BAP_DisplayConfig_ASG_02_Header 3;
BA_ "GenSigSwitchedByIgnition" SG_ 2536719617 BAP_DisplayConfig_ASG_02_Header 0;
BA_ "GenSigSendType" SG_ 2536719632 BAP_DisplayConfig_FSG_01_Header 3;
BA_ "GenSigSwitchedByIgnition" SG_ 2536719632 BAP_DisplayConfig_FSG_01_Header 0;
BA_ "GenSigSendType" SG_ 2536705280 BAP_Doorlocking_ASG_01_Header 3;
BA_ "GenSigSwitchedByIgnition" SG_ 2536705280 BAP_Doorlocking_ASG_01_Header 0;
BA_ "GenSigSendType" SG_ 2536705282 BAP_Doorlocking_ASG_03_Header 3;
BA_ "GenSigSwitchedByIgnition" SG_ 2536705282 BAP_Doorlocking_ASG_03_Header 0;
BA_ "GenSigSendType" SG_ 2536705296 BAP_Doorlocking_FSG_01_Header 3;
BA_ "GenSigSwitchedByIgnition" SG_ 2536705296 BAP_Doorlocking_FSG_01_Header 0;
BA_ "GenSigSendType" SG_ 2536727296 BAP_Doors2_ASG_01_Header 3;
BA_ "GenSigSwitchedByIgnition" SG_ 2536727296 BAP_Doors2_ASG_01_Header 0;
BA_ "GenSigSendType" SG_ 2536727312 BAP_Doors2_FSG_01_Header 3;
BA_ "GenSigSwitchedByIgnition" SG_ 2536727312 BAP_Doors2_FSG_01_Header 0;
BA_ "GenSigSendType" SG_ 2536724736 BAP_Doors_ASG_01_Header 3;
BA_ "GenSigSwitchedByIgnition" SG_ 2536724736 BAP_Doors_ASG_01_Header 0;
BA_ "GenSigSendType" SG_ 2536724752 BAP_Doors_FSG_01_Header 3;
BA_ "GenSigSwitchedByIgnition" SG_ 2536724752 BAP_Doors_FSG_01_Header 0;
BA_ "GenSigSendType" SG_ 2536734208 BAP_DrivingDynamics_ASG_01_Hdr 3;
BA_ "GenSigSwitchedByIgnition" SG_ 2536734208 BAP_DrivingDynamics_ASG_01_Hdr 0;
BA_ "GenSigSendType" SG_ 2536734224 BAP_DrivingDynamics_FSG_01_Hdr 3;
BA_ "GenSigSwitchedByIgnition" SG_ 2536734224 BAP_DrivingDynamics_FSG_01_Hdr 0;
BA_ "GenSigSendType" SG_ 2536715008 BAP_eCall_ASG_01_Header 3;
BA_ "GenSigSwitchedByIgnition" SG_ 2536715008 BAP_eCall_ASG_01_Header 0;
BA_ "GenSigSendType" SG_ 2536715024 BAP_eCall_FSG_01_Header 3;
BA_ "GenSigSwitchedByIgnition" SG_ 2536715024 BAP_eCall_FSG_01_Header 0;
BA_ "GenSigSendType" SG_ 2536717312 BAP_EfficAssist_ASG_01_Header 3;
BA_ "GenSigSwitchedByIgnition" SG_ 2536717312 BAP_EfficAssist_ASG_01_Header 0;
BA_ "GenSigSendType" SG_ 2536717328 BAP_EfficAssist_FSG_01_Header 3;
BA_ "GenSigSwitchedByIgnition" SG_ 2536717328 BAP_EfficAssist_FSG_01_Header 0;
BA_ "GenSigSendType" SG_ 2536706816 BAP_Einheiten_ASG_01_Header 3;
BA_ "GenSigSwitchedByIgnition" SG_ 2536706816 BAP_Einheiten_ASG_01_Header 0;
BA_ "GenSigSendType" SG_ 2536706819 BAP_Einheiten_ASG_04_Header 3;
BA_ "GenSigSwitchedByIgnition" SG_ 2536706819 BAP_Einheiten_ASG_04_Header 0;
BA_ "GenSigSendType" SG_ 2536706832 BAP_Einheiten_FSG_01_Header 3;
BA_ "GenSigSwitchedByIgnition" SG_ 2536706832 BAP_Einheiten_FSG_01_Header 0;
BA_ "GenSigSendType" SG_ 2536725760 BAP_EngFunctions_ASG_01_Header 3;
BA_ "GenSigSwitchedByIgnition" SG_ 2536725760 BAP_EngFunctions_ASG_01_Header 0;
BA_ "GenSigSendType" SG_ 2536725776 BAP_EngFunctions_FSG_01_Header 3;
BA_ "GenSigSwitchedByIgnition" SG_ 2536725776 BAP_EngFunctions_FSG_01_Header 0;
BA_ "GenSigSendType" SG_ 2536724480 BAP_ENI2_ASG_01_Header 3;
BA_ "GenSigSwitchedByIgnition" SG_ 2536724480 BAP_ENI2_ASG_01_Header 0;
BA_ "GenSigSendType" SG_ 2536724481 BAP_ENI2_ASG_02_Header 3;
BA_ "GenSigSwitchedByIgnition" SG_ 2536724481 BAP_ENI2_ASG_02_Header 0;
BA_ "GenSigSendType" SG_ 2536724496 BAP_ENI2_FSG_01_Header 3;
BA_ "GenSigSwitchedByIgnition" SG_ 2536724496 BAP_ENI2_FSG_01_Header 0;
BA_ "GenSigSendType" SG_ 2536724497 BAP_ENI2_FSG_02_Header 3;
BA_ "GenSigSwitchedByIgnition" SG_ 2536724497 BAP_ENI2_FSG_02_Header 0;
BA_ "GenSigSendType" SG_ 2536730112 BAP_ENI3_ASG_01_Header 3;
BA_ "GenSigSwitchedByIgnition" SG_ 2536730112 BAP_ENI3_ASG_01_Header 0;
BA_ "GenSigSendType" SG_ 2536730113 BAP_ENI3_ASG_02_Header 3;
BA_ "GenSigSwitchedByIgnition" SG_ 2536730113 BAP_ENI3_ASG_02_Header 0;
BA_ "GenSigSendType" SG_ 2536730128 BAP_ENI3_FSG_01_Header 3;
BA_ "GenSigSwitchedByIgnition" SG_ 2536730128 BAP_ENI3_FSG_01_Header 0;
BA_ "GenSigSendType" SG_ 2536730129 BAP_ENI3_FSG_02_Header 3;
BA_ "GenSigSwitchedByIgnition" SG_ 2536730129 BAP_ENI3_FSG_02_Header 0;
BA_ "GenSigSendType" SG_ 2536716032 BAP_ENI_ASG_01_Header 3;
BA_ "GenSigSwitchedByIgnition" SG_ 2536716032 BAP_ENI_ASG_01_Header 0;
BA_ "GenSigSendType" SG_ 2536716033 BAP_ENI_ASG_02_Header 3;
BA_ "GenSigSwitchedByIgnition" SG_ 2536716033 BAP_ENI_ASG_02_Header 0;
BA_ "GenSigSendType" SG_ 2536716048 BAP_ENI_FSG_01_Header 3;
BA_ "GenSigSwitchedByIgnition" SG_ 2536716048 BAP_ENI_FSG_01_Header 0;
BA_ "GenSigSendType" SG_ 2536716049 BAP_ENI_FSG_02_Header 3;
BA_ "GenSigSwitchedByIgnition" SG_ 2536716049 BAP_ENI_FSG_02_Header 0;
BA_ "GenSigSendType" SG_ 2536721664 BAP_FAS_Profiles_ASG_01_Header 3;
BA_ "GenSigSwitchedByIgnition" SG_ 2536721664 BAP_FAS_Profiles_ASG_01_Header 0;
BA_ "GenSigSendType" SG_ 2536721680 BAP_FAS_Profiles_FSG_01_Header 3;
BA_ "GenSigSwitchedByIgnition" SG_ 2536721680 BAP_FAS_Profiles_FSG_01_Header 0;
BA_ "GenSigSendType" SG_ 2536707072 BAP_Homelink_ASG_01_Header 3;
BA_ "GenSigSwitchedByIgnition" SG_ 2536707072 BAP_Homelink_ASG_01_Header 0;
BA_ "GenSigSendType" SG_ 2536707088 BAP_Homelink_FSG_01_Header 3;
BA_ "GenSigSwitchedByIgnition" SG_ 2536707088 BAP_Homelink_FSG_01_Header 0;
BA_ "GenSigSendType" SG_ 2536702976 BAP_HUD_ASG_01_Header 3;
BA_ "GenSigSwitchedByIgnition" SG_ 2536702976 BAP_HUD_ASG_01_Header 0;
BA_ "GenSigSendType" SG_ 2536702978 BAP_HUD_ASG_03_Header 3;
BA_ "GenSigSwitchedByIgnition" SG_ 2536702978 BAP_HUD_ASG_03_Header 0;
BA_ "GenSigSendType" SG_ 2536702992 BAP_HUD_FSG_01_Header 3;
BA_ "GenSigSwitchedByIgnition" SG_ 2536702992 BAP_HUD_FSG_01_Header 0;
BA_ "GenSigSendType" SG_ 2536709120 BAP_Hybrid_ASG_01_Header 3;
BA_ "GenSigSwitchedByIgnition" SG_ 2536709120 BAP_Hybrid_ASG_01_Header 0;
BA_ "GenSigSendType" SG_ 2536709136 BAP_Hybrid_FSG_01_Header 3;
BA_ "GenSigSwitchedByIgnition" SG_ 2536709136 BAP_Hybrid_FSG_01_Header 0;
BA_ "GenSigSendType" SG_ 2536722944 BAP_IAA_PSO_ASG_01_Header 3;
BA_ "GenSigSwitchedByIgnition" SG_ 2536722944 BAP_IAA_PSO_ASG_01_Header 0;
BA_ "GenSigSendType" SG_ 2536722945 BAP_IAA_PSO_ASG_02_Header 3;
BA_ "GenSigSwitchedByIgnition" SG_ 2536722945 BAP_IAA_PSO_ASG_02_Header 0;
BA_ "GenSigSendType" SG_ 2536722946 BAP_IAA_PSO_ASG_03_Header 3;
BA_ "GenSigSwitchedByIgnition" SG_ 2536722946 BAP_IAA_PSO_ASG_03_Header 0;
BA_ "GenSigSendType" SG_ 2536722960 BAP_IAA_PSO_FSG_01_Header 3;
BA_ "GenSigSwitchedByIgnition" SG_ 2536722960 BAP_IAA_PSO_FSG_01_Header 0;
BA_ "GenSigSendType" SG_ 2536722434 BAP_InfoSettings_ASG_03_Header 3;
BA_ "GenSigSwitchedByIgnition" SG_ 2536722434 BAP_InfoSettings_ASG_03_Header 0;
BA_ "GenSigSendType" SG_ 2536722448 BAP_InfoSettings_FSG_01_Header 3;
BA_ "GenSigSwitchedByIgnition" SG_ 2536722448 BAP_InfoSettings_FSG_01_Header 0;
BA_ "GenSigSendType" SG_ 2536704000 BAP_Innenlicht_ASG_01_Header 3;
BA_ "GenSigSwitchedByIgnition" SG_ 2536704000 BAP_Innenlicht_ASG_01_Header 0;
BA_ "GenSigSendType" SG_ 2536704001 BAP_Innenlicht_ASG_02_Header 3;
BA_ "GenSigSwitchedByIgnition" SG_ 2536704001 BAP_Innenlicht_ASG_02_Header 0;
BA_ "GenSigSendType" SG_ 2536704016 BAP_Innenlicht_FSG_01_Header 3;
BA_ "GenSigSwitchedByIgnition" SG_ 2536704016 BAP_Innenlicht_FSG_01_Header 0;
BA_ "GenSigSendType" SG_ 2536702208 BAP_Klima1_ASG_01_Header 3;
BA_ "GenSigSwitchedByIgnition" SG_ 2536702208 BAP_Klima1_ASG_01_Header 0;
BA_ "GenSigSendType" SG_ 2536702224 BAP_Klima1_FSG_01_Header 3;
BA_ "GenSigSwitchedByIgnition" SG_ 2536702224 BAP_Klima1_FSG_01_Header 0;
BA_ "GenSigSendType" SG_ 2536702464 BAP_Klima2_ASG_01_Header 3;
BA_ "GenSigSwitchedByIgnition" SG_ 2536702464 BAP_Klima2_ASG_01_Header 0;
BA_ "GenSigSendType" SG_ 2536702480 BAP_Klima2_FSG_01_Header 3;
BA_ "GenSigSwitchedByIgnition" SG_ 2536702480 BAP_Klima2_FSG_01_Header 0;
BA_ "GenSigSendType" SG_ 2536718848 BAP_KlimaMaster_ASG_01_Header 3;
BA_ "GenSigSwitchedByIgnition" SG_ 2536718848 BAP_KlimaMaster_ASG_01_Header 0;
BA_ "GenSigSendType" SG_ 2536718849 BAP_KlimaMaster_ASG_02_Header 3;
BA_ "GenSigSwitchedByIgnition" SG_ 2536718849 BAP_KlimaMaster_ASG_02_Header 0;
BA_ "GenSigSendType" SG_ 2536718864 BAP_KlimaMaster_FSG_01_Header 3;
BA_ "GenSigSwitchedByIgnition" SG_ 2536718864 BAP_KlimaMaster_FSG_01_Header 0;
BA_ "GenSigSendType" SG_ 2536708352 BAP_LDW_ASG_01_Header 3;
BA_ "GenSigSwitchedByIgnition" SG_ 2536708352 BAP_LDW_ASG_01_Header 0;
BA_ "GenSigSendType" SG_ 2536708354 BAP_LDW_ASG_03_Header 3;
BA_ "GenSigSwitchedByIgnition" SG_ 2536708354 BAP_LDW_ASG_03_Header 0;
BA_ "GenSigSendType" SG_ 2536708368 BAP_LDW_FSG_01_Header 3;
BA_ "GenSigSendType" SG_ 2536715264 BAP_MFL_ASG_01_Header 3;
BA_ "GenSigSwitchedByIgnition" SG_ 2536715264 BAP_MFL_ASG_01_Header 0;
BA_ "GenSigSendType" SG_ 2536715280 BAP_MFL_FSG_01_Header 3;
BA_ "GenSigSwitchedByIgnition" SG_ 2536715280 BAP_MFL_FSG_01_Header 0;
BA_ "GenSigSendType" SG_ 2536705536 BAP_Mirror_ASG_01_Header 3;
BA_ "GenSigSwitchedByIgnition" SG_ 2536705536 BAP_Mirror_ASG_01_Header 0;
BA_ "GenSigSendType" SG_ 2536705537 BAP_Mirror_ASG_02_Header 3;
BA_ "GenSigSwitchedByIgnition" SG_ 2536705537 BAP_Mirror_ASG_02_Header 0;
BA_ "GenSigSendType" SG_ 2536705552 BAP_Mirror_FSG_01_Header 3;
BA_ "GenSigSwitchedByIgnition" SG_ 2536705552 BAP_Mirror_FSG_01_Header 0;
BA_ "GenSigSendType" SG_ 2536710656 BAP_MKE_ASG_01_Header 3;
BA_ "GenSigSwitchedByIgnition" SG_ 2536710656 BAP_MKE_ASG_01_Header 0;
BA_ "GenSigSendType" SG_ 2536710672 BAP_MKE_FSG_01_Header 3;
BA_ "GenSigSwitchedByIgnition" SG_ 2536710672 BAP_MKE_FSG_01_Header 0;
BA_ "GenSigSendType" SG_ 2536732416 BAP_MobDevKey_ASG_01_Header 3;
BA_ "GenSigSwitchedByIgnition" SG_ 2536732416 BAP_MobDevKey_ASG_01_Header 0;
BA_ "GenSigSendType" SG_ 2536732417 BAP_MobDevKey_ASG_02_Header 3;
BA_ "GenSigSwitchedByIgnition" SG_ 2536732417 BAP_MobDevKey_ASG_02_Header 0;
BA_ "GenSigSendType" SG_ 2536732432 BAP_MobDevKey_FSG_01_Header 3;
BA_ "GenSigSwitchedByIgnition" SG_ 2536732432 BAP_MobDevKey_FSG_01_Header 0;
BA_ "GenSigSendType" SG_ 2536734464 BAP_MobDevKeyOnline_ASG_01_Heade 3;
BA_ "GenSigSwitchedByIgnition" SG_ 2536734464 BAP_MobDevKeyOnline_ASG_01_Heade 0;
BA_ "GenSigSendType" SG_ 2536734480 BAP_MobDevKeyOnline_FSG_01_Heade 3;
BA_ "GenSigSwitchedByIgnition" SG_ 2536734480 BAP_MobDevKeyOnline_FSG_01_Heade 0;
BA_ "GenSigSendType" SG_ 2536714752 BAP_Navigation_ASG_01_Header 3;
BA_ "GenSigSwitchedByIgnition" SG_ 2536714752 BAP_Navigation_ASG_01_Header 0;
BA_ "GenSigSendType" SG_ 2536714753 BAP_Navigation_ASG_02_Header 3;
BA_ "GenSigSwitchedByIgnition" SG_ 2536714753 BAP_Navigation_ASG_02_Header 0;
BA_ "GenSigSendType" SG_ 2536714754 BAP_Navigation_ASG_03_Header 3;
BA_ "GenSigSwitchedByIgnition" SG_ 2536714754 BAP_Navigation_ASG_03_Header 0;
BA_ "GenSigSendType" SG_ 2536714755 BAP_Navigation_ASG_04_Header 3;
BA_ "GenSigSwitchedByIgnition" SG_ 2536714755 BAP_Navigation_ASG_04_Header 0;
BA_ "GenSigSendType" SG_ 2536714768 BAP_Navigation_FSG_01_Header 3;
BA_ "GenSigSwitchedByIgnition" SG_ 2536714768 BAP_Navigation_FSG_01_Header 0;
BA_ "GenSigSendType" SG_ 2536714769 BAP_Navigation_FSG_02_Header 3;
BA_ "GenSigSwitchedByIgnition" SG_ 2536714769 BAP_Navigation_FSG_02_Header 0;
BA_ "GenSigSendType" SG_ 2536712704 BAP_OnlineFunction_ASG_01_Header 3;
BA_ "GenSigSwitchedByIgnition" SG_ 2536712704 BAP_OnlineFunction_ASG_01_Header 0;
BA_ "GenSigSendType" SG_ 2536712705 BAP_OnlineFunction_ASG_02_Header 3;
BA_ "GenSigSwitchedByIgnition" SG_ 2536712705 BAP_OnlineFunction_ASG_02_Header 0;
BA_ "GenSigSendType" SG_ 2536712720 BAP_OnlineFunction_FSG_01_Header 3;
BA_ "GenSigSwitchedByIgnition" SG_ 2536712720 BAP_OnlineFunction_FSG_01_Header 0;
BA_ "GenSigSendType" SG_ 2536704512 BAP_OPS_ASG_01_Header 3;
BA_ "GenSigSwitchedByIgnition" SG_ 2536704512 BAP_OPS_ASG_01_Header 0;
BA_ "GenSigSendType" SG_ 2536704516 BAP_OPS_ASG_05_Header 3;
BA_ "GenSigSwitchedByIgnition" SG_ 2536704516 BAP_OPS_ASG_05_Header 0;
BA_ "GenSigSendType" SG_ 2536704528 BAP_OPS_FSG_01_Header 3;
BA_ "GenSigSwitchedByIgnition" SG_ 2536704528 BAP_OPS_FSG_01_Header 0;
BA_ "GenSigSendType" SG_ 2536704529 BAP_OPS_FSG_02_Header 3;
BA_ "GenSigSwitchedByIgnition" SG_ 2536704529 BAP_OPS_FSG_02_Header 0;
BA_ "GenSigSendType" SG_ 2536723712 BAP_PaCo_ASG_01_Header 3;
BA_ "GenSigSwitchedByIgnition" SG_ 2536723712 BAP_PaCo_ASG_01_Header 0;
BA_ "GenSigSendType" SG_ 2536723714 BAP_PaCo_ASG_03_Header 3;
BA_ "GenSigSwitchedByIgnition" SG_ 2536723714 BAP_PaCo_ASG_03_Header 0;
BA_ "GenSigSendType" SG_ 2536723728 BAP_PaCo_FSG_01_Header 3;
BA_ "GenSigSwitchedByIgnition" SG_ 2536723728 BAP_PaCo_FSG_01_Header 0;
BA_ "GenSigSendType" SG_ 2536702720 BAP_ParkHeater_ASG_01_Header 3;
BA_ "GenSigSwitchedByIgnition" SG_ 2536702720 BAP_ParkHeater_ASG_01_Header 0;
BA_ "GenSigSendType" SG_ 2536702721 BAP_ParkHeater_ASG_02_Header 3;
BA_ "GenSigSwitchedByIgnition" SG_ 2536702721 BAP_ParkHeater_ASG_02_Header 0;
BA_ "GenSigSendType" SG_ 2536702736 BAP_ParkHeater_FSG_01_Header 3;
BA_ "GenSigSwitchedByIgnition" SG_ 2536702736 BAP_ParkHeater_FSG_01_Header 0;
BA_ "GenSigSendType" SG_ 2536734721 BAP_PlugAndCharge_ASG_02_Header 3;
BA_ "GenSigSwitchedByIgnition" SG_ 2536734721 BAP_PlugAndCharge_ASG_02_Header 0;
BA_ "GenSigSendType" SG_ 2536734737 BAP_PlugAndCharge_FSG_02_Header 3;
BA_ "GenSigSwitchedByIgnition" SG_ 2536734737 BAP_PlugAndCharge_FSG_02_Header 0;
BA_ "GenSigSendType" SG_ 2536716544 BAP_RangeData_ASG_01_Header 3;
BA_ "GenSigSwitchedByIgnition" SG_ 2536716544 BAP_RangeData_ASG_01_Header 0;
BA_ "GenSigSendType" SG_ 2536716560 BAP_RangeData_FSG_01_Header 3;
BA_ "GenSigSwitchedByIgnition" SG_ 2536716560 BAP_RangeData_FSG_01_Header 0;
BA_ "GenSigSendType" SG_ 2536703744 BAP_RDK_ASG_01_Header 3;
BA_ "GenSigSwitchedByIgnition" SG_ 2536703744 BAP_RDK_ASG_01_Header 0;
BA_ "GenSigSendType" SG_ 2536703745 BAP_RDK_ASG_02_Header 3;
BA_ "GenSigSwitchedByIgnition" SG_ 2536703745 BAP_RDK_ASG_02_Header 0;
BA_ "GenSigSendType" SG_ 2536703760 BAP_RDK_FSG_01_Header 3;
BA_ "GenSigSwitchedByIgnition" SG_ 2536703760 BAP_RDK_FSG_01_Header 0;
BA_ "GenSigSendType" SG_ 2536728320 BAP_REM2_ASG_01_Header 3;
BA_ "GenSigSwitchedByIgnition" SG_ 2536728320 BAP_REM2_ASG_01_Header 0;
BA_ "GenSigSendType" SG_ 2536728336 BAP_REM2_FSG_01_Header 3;
BA_ "GenSigSwitchedByIgnition" SG_ 2536728336 BAP_REM2_FSG_01_Header 0;
BA_ "GenSigSendType" SG_ 2536728337 BAP_REM2_FSG_02_Header 3;
BA_ "GenSigSwitchedByIgnition" SG_ 2536728337 BAP_REM2_FSG_02_Header 0;
BA_ "GenSigSendType" SG_ 2536725248 BAP_REM_ASG_01_Header 3;
BA_ "GenSigSwitchedByIgnition" SG_ 2536725248 BAP_REM_ASG_01_Header 0;
BA_ "GenSigSendType" SG_ 2536725264 BAP_REM_FSG_01_Header 3;
BA_ "GenSigSendType" SG_ 2536725265 BAP_REM_FSG_02_Header 3;
BA_ "GenSigSendType" SG_ 2536721920 BAP_RemoteServices_ASG_01_Header 3;
BA_ "GenSigSwitchedByIgnition" SG_ 2536721920 BAP_RemoteServices_ASG_01_Header 0;
BA_ "GenSigSendType" SG_ 2536721921 BAP_RemoteServices_ASG_02_Header 3;
BA_ "GenSigSwitchedByIgnition" SG_ 2536721921 BAP_RemoteServices_ASG_02_Header 0;
BA_ "GenSigSendType" SG_ 2536721936 BAP_RemoteServices_FSG_01_Header 3;
BA_ "GenSigSwitchedByIgnition" SG_ 2536721936 BAP_RemoteServices_FSG_01_Header 0;
BA_ "GenSigSendType" SG_ 2536731904 BAP_RollingAbility_ASG_01_Header 3;
BA_ "GenSigSwitchedByIgnition" SG_ 2536731904 BAP_RollingAbility_ASG_01_Header 0;
BA_ "GenSigSendType" SG_ 2536731920 BAP_RollingAbility_FSG_01_Header 3;
BA_ "GenSigSwitchedByIgnition" SG_ 2536731920 BAP_RollingAbility_FSG_01_Header 0;
BA_ "GenSigSendType" SG_ 2536730624 BAP_RSO_ASG_01_Header 3;
BA_ "GenSigSwitchedByIgnition" SG_ 2536730624 BAP_RSO_ASG_01_Header 0;
BA_ "GenSigSendType" SG_ 2536730640 BAP_RSO_FSG_01_Header 3;
BA_ "GenSigSwitchedByIgnition" SG_ 2536730640 BAP_RSO_FSG_01_Header 0;
BA_ "GenSigSendType" SG_ 2536704768 BAP_RVC_ASG_01_Header 3;
BA_ "GenSigSwitchedByIgnition" SG_ 2536704768 BAP_RVC_ASG_01_Header 0;
BA_ "GenSigSendType" SG_ 2536704784 BAP_RVC_FSG_01_Header 3;
BA_ "GenSigSwitchedByIgnition" SG_ 2536704784 BAP_RVC_FSG_01_Header 0;
BA_ "GenSigSendType" SG_ 2536719872 BAP_SDS_ASG_01_Header 3;
BA_ "GenSigSwitchedByIgnition" SG_ 2536719872 BAP_SDS_ASG_01_Header 0;
BA_ "GenSigSendType" SG_ 2536719888 BAP_SDS_FSG_01_Header 3;
BA_ "GenSigSwitchedByIgnition" SG_ 2536719888 BAP_SDS_FSG_01_Header 0;
BA_ "GenSigSendType" SG_ 2536717056 BAP_SeatPneumatic_ASG_01_Header 3;
BA_ "GenSigSwitchedByIgnition" SG_ 2536717056 BAP_SeatPneumatic_ASG_01_Header 0;
BA_ "GenSigSendType" SG_ 2536717057 BAP_SeatPneumatic_ASG_02_Header 3;
BA_ "GenSigSwitchedByIgnition" SG_ 2536717057 BAP_SeatPneumatic_ASG_02_Header 0;
BA_ "GenSigSendType" SG_ 2536717072 BAP_SeatPneumatic_FSG_01_Header 3;
BA_ "GenSigSwitchedByIgnition" SG_ 2536717072 BAP_SeatPneumatic_FSG_01_Header 0;
BA_ "GenSigSendType" SG_ 2536735488 BAP_SecEvents2_ASG_01_Header 3;
BA_ "GenSigSwitchedByIgnition" SG_ 2536735488 BAP_SecEvents2_ASG_01_Header 0;
BA_REL_ "GenSigTimeoutTime" BU_SG_REL_ BedienDisp_mi SG_ 2589283936 AC_FES_Atmosphere_AMB_RGB_1 5000;
BA_REL_ "GenSigTimeoutTime" BU_SG_REL_ BedienDisp_mi SG_ 2589283936 AC_FES_Atmosphere_AMB_RGB_2 5000;
BA_REL_ "GenSigTimeoutTime" BU_SG_REL_ BedienDisp_mi SG_ 2589283937 AC_FES_Atmosphere_AMB_RGB_3 5000;
BA_REL_ "GenSigTimeoutTime" BU_SG_REL_ BedienDisp_mi SG_ 2589283937 AC_FES_Atmosphere_AMB_RGB_4 5000;
BA_REL_ "GenSigTimeoutTime" BU_SG_REL_ BedienDisp_mi SG_ 2589283938 AC_FES_Atmosphere_AMB_RGB_5 5000;
BA_REL_ "GenSigTimeoutTime" BU_SG_REL_ BedienDisp_mi SG_ 2589283938 AC_FES_Atmosphere_AMB_RGB_6 5000;
BA_REL_ "GenSigTimeoutTime" BU_SG_REL_ BedienDisp_mi SG_ 2589283939 LC_FES_Viewmode 5000;
BA_REL_ "GenSigTimeoutTime" BU_SG_REL_ BedienDisp_mi SG_ 2589283939 AC_FES_Atmosphere_AMB_RGB_7 5000;
BA_REL_ "GenSigTimeoutTime" BU_SG_REL_ BedienDisp_mi SG_ 2589283939 LC_FES_Aktive_Ebene_SOLL 5000;
BA_REL_ "GenSigTimeoutTime" BU_SG_REL_ BedienDisp_mi SG_ 2589283940 AC_FES_Aktive_Atmosphere 5000;
BA_REL_ "GenSigTimeoutTime" BU_SG_REL_ BedienDisp_mi SG_ 2589283940 AC_FES_Atmosphere_1 5000;
BA_REL_ "GenSigTimeoutTime" BU_SG_REL_ BedienDisp_mi SG_ 2589283940 AC_FES_Atmosphere_2 5000;
BA_REL_ "GenSigTimeoutTime" BU_SG_REL_ BedienDisp_mi SG_ 2589283940 AC_FES_Atmosphere_3 5000;
BA_REL_ "GenSigTimeoutTime" BU_SG_REL_ BedienDisp_mi SG_ 2589283940 AC_FES_Atmosphere_4 5000;
BA_REL_ "GenSigTimeoutTime" BU_SG_REL_ BedienDisp_mi SG_ 2589283940 AC_FES_Atmosphere_5 5000;
BA_REL_ "GenSigTimeoutTime" BU_SG_REL_ BedienDisp_mi SG_ 2589283940 AC_FES_Atmosphere_6 5000;
BA_REL_ "GenSigTimeoutTime" BU_SG_REL_ BedienDisp_mi SG_ 2589283940 AC_FES_Atmosphere_7 5000;
BA_REL_ "GenSigTimeoutTime" BU_SG_REL_ BedienDisp_mi SG_ 64 AB_Belegung_VF 500;
BA_REL_ "GenSigTimeoutTime" BU_SG_REL_ BedienDisp_mi SG_ 1312 AB_Gurtschloss_FA 2000;
BA_REL_ "GenSigTimeoutTime" BU_SG_REL_ ConMod_CD SG_ 64 AB_Front_Crash 500;
BA_REL_ "GenSigTimeoutTime" BU_SG_REL_ ConMod_CD SG_ 64 AB_Heck_Crash 500;
BA_REL_ "GenSigTimeoutTime" BU_SG_REL_ ConMod_CD SG_ 64 AB_SF_Crash 500;
BA_REL_ "GenSigTimeoutTime" BU_SG_REL_ ConMod_CD SG_ 64 AB_SB_Crash 500;
BA_REL_ "GenSigTimeoutTime" BU_SG_REL_ ConMod_CD SG_ 64 AB_Rollover_Crash 500;
BA_REL_ "GenSigTimeoutTime" BU_SG_REL_ ConMod_CD SG_ 64 AB_Crash_Int 500;
BA_REL_ "GenSigTimeoutTime" BU_SG_REL_ ConMod_CD SG_ 64 AB_Systemfehler 500;
BA_REL_ "GenSigTimeoutTime" BU_SG_REL_ ConMod_CD SG_ 64 AB_Diagnose 500;
BA_REL_ "GenSigTimeoutTime" BU_SG_REL_ ConMod_CD SG_ 64 AB_Stellgliedtest 500;
BA_REL_ "GenSigTimeoutTime" BU_SG_REL_ ConMod_CD SG_ 64 AB_Anzeige_Fussg 500;
BA_REL_ "GenSigTimeoutTime" BU_SG_REL_ ConMod_CD SG_ 1312 AB_Belegung_VB 2000;
BA_REL_ "GenSigTimeoutTime" BU_SG_REL_ ConMod_CD SG_ 1312 AB_Gurtschloss_FA 2000;
BA_REL_ "GenSigTimeoutTime" BU_SG_REL_ ConMod_CD SG_ 1312 AB_Gurtschloss_BF 2000;
BA_REL_ "GenSigTimeoutTime" BU_SG_REL_ ConMod_CD SG_ 1312 AB_Gurtschloss_Reihe2_FA 2000;
BA_REL_ "GenSigTimeoutTime" BU_SG_REL_ ConMod_CD SG_ 1312 AB_Gurtschloss_Reihe2_MI 2000;
BA_REL_ "GenSigTimeoutTime" BU_SG_REL_ ConMod_CD SG_ 1312 AB_Gurtschloss_Reihe2_BF 2000;
BA_REL_ "GenSigTimeoutTime" BU_SG_REL_ ConMod_CD SG_ 1312 AB_Gurtschloss_Reihe3_FA 2000;
BA_REL_ "GenSigTimeoutTime" BU_SG_REL_ ConMod_CD SG_ 1312 AB_Gurtschloss_Reihe3_MI 2000;
BA_REL_ "GenSigTimeoutTime" BU_SG_REL_ ConMod_CD SG_ 1312 AB_Gurtschloss_Reihe3_BF 2000;
BA_REL_ "GenSigTimeoutTime" BU_SG_REL_ ConMod_CD SG_ 65 AB_DeltaV_X_eCall 5000;
BA_REL_ "GenSigTimeoutTime" BU_SG_REL_ ConMod_CD SG_ 65 AB_DeltaV_Y_eCall 5000;
BA_REL_ "GenSigTimeoutTime" BU_SG_REL_ ConMod_CD SG_ 2527679722 AB_Gurtschloss_MI 2000;
BA_REL_ "GenSigTimeoutTime" BU_SG_REL_ DashCAM SG_ 1312 AB_Crashschwere 2000;
BA_REL_ "GenSigTimeoutTime" BU_SG_REL_ Gateway_Max SG_ 2536711424 BAP_BatteryControl_ASG_01_Header 800;
BA_REL_ "GenSigTimeoutTime" BU_SG_REL_ Gateway_Max SG_ 2536711425 BAP_BatteryControl_ASG_02_Header 800;
BA_REL_ "GenSigTimeoutTime" BU_SG_REL_ Gateway_Max SG_ 2536710913 BAP_BCmE_ASG_02_Header 800;
BA_REL_ "GenSigTimeoutTime" BU_SG_REL_ Gateway_Max SG_ 2536707840 BAP_Charisma_ASG_01_Header 800;
BA_REL_ "GenSigTimeoutTime" BU_SG_REL_ Gateway_Max SG_ 2536707844 BAP_Charisma_ASG_05_Header 800;
BA_REL_ "GenSigTimeoutTime" BU_SG_REL_ Gateway_Max SG_ 2536721664 BAP_FAS_Profiles_ASG_01_Header 800;
BA_REL_ "GenSigTimeoutTime" BU_SG_REL_ Gateway_Max SG_ 2536710656 BAP_MKE_ASG_01_Header 800;
BA_REL_ "GenSigTimeoutTime" BU_SG_REL_ Gateway_Max SG_ 2536723712 BAP_PaCo_ASG_01_Header 500;
BA_REL_ "GenSigTimeoutTime" BU_SG_REL_ Gateway_Max SG_ 2536723714 BAP_PaCo_ASG_03_Header 800;
BA_REL_ "GenSigTimeoutTime" BU_SG_REL_ Gateway_Max SG_ 2536702720 BAP_ParkHeater_ASG_01_Header 800;
BA_REL_ "GenSigTimeoutTime" BU_SG_REL_ Gateway_Max SG_ 2536702721 BAP_ParkHeater_ASG_02_Header 800;
BA_REL_ "GenSigTimeoutTime" BU_SG_REL_ Gateway_Max SG_ 2536734721 BAP_PlugAndCharge_ASG_02_Header 800;
BA_REL_ "GenSigTimeoutTime" BU_SG_REL_ Gateway_Max SG_ 2536716544 BAP_RangeData_ASG_01_Header 800;
BA_REL_ "GenSigTimeoutTime" BU_SG_REL_ LSH SG_ 64 AB_Crash_Int 500;
BA_REL_ "GenSigTimeoutTime" BU_SG_REL_ LSH SG_ 64 AB_Stellgliedtest 500;
BA_REL_ "GenSigTimeoutTime" BU_SG_REL_ OCU SG_ 64 Airbag_01_CRC 500;
BA_REL_ "GenSigTimeoutTime" BU_SG_REL_ OCU SG_ 64 Airbag_01_BZ 500;
BA_REL_ "GenSigTimeoutTime" BU_SG_REL_ OCU SG_ 64 AB_Front_Crash 500;
BA_REL_ "GenSigTimeoutTime" BU_SG_REL_ OCU SG_ 64 AB_Heck_Crash 500;
BA_REL_ "GenSigTimeoutTime" BU_SG_REL_ OCU SG_ 64 AB_SF_Crash 500;
BA_REL_ "GenSigTimeoutTime" BU_SG_REL_ OCU SG_ 64 AB_SB_Crash 500;
BA_REL_ "GenSigTimeoutTime" BU_SG_REL_ OCU SG_ 64 AB_Rollover_Crash 500;
BA_REL_ "GenSigTimeoutTime" BU_SG_REL_ OCU SG_ 64 AB_Crash_Int 500;
BA_REL_ "GenSigTimeoutTime" BU_SG_REL_ OCU SG_ 64 AB_Lampe 500;
BA_REL_ "GenSigTimeoutTime" BU_SG_REL_ OCU SG_ 64 AB_VB_deaktiviert 500;
BA_REL_ "GenSigTimeoutTime" BU_SG_REL_ OCU SG_ 64 AB_Systemfehler 500;
BA_REL_ "GenSigTimeoutTime" BU_SG_REL_ OCU SG_ 64 AB_Diagnose 500;
BA_REL_ "GenSigTimeoutTime" BU_SG_REL_ OCU SG_ 64 AB_Stellgliedtest 500;
BA_REL_ "GenSigTimeoutTime" BU_SG_REL_ OCU SG_ 64 AB_Gurtwarn_VF 500;
BA_REL_ "GenSigTimeoutTime" BU_SG_REL_ OCU SG_ 64 AB_Gurtwarn_VB 500;
BA_REL_ "GenSigTimeoutTime" BU_SG_REL_ OCU SG_ 64 AB_Anzeige_Fussg 500;
BA_REL_ "GenSigTimeoutTime" BU_SG_REL_ OCU SG_ 64 AB_Texte_AKS 500;
BA_REL_ "GenSigTimeoutTime" BU_SG_REL_ OCU SG_ 64 AB_Deaktivierung_HV 500;
BA_REL_ "GenSigTimeoutTime" BU_SG_REL_ OCU SG_ 64 AB_EDR_Trigger 500;
BA_REL_ "GenSigTimeoutTime" BU_SG_REL_ OCU SG_ 64 AB_Belegung_VF 500;
BA_REL_ "GenSigTimeoutTime" BU_SG_REL_ OCU SG_ 64 AB_Gurtschloss_FA_ext 500;
BA_REL_ "GenSigTimeoutTime" BU_SG_REL_ OCU SG_ 1312 AB_Anprall_Seite_Beifahrer 2000;
BA_REL_ "GenSigTimeoutTime" BU_SG_REL_ OCU SG_ 1312 AB_Anprall_FGS 2000;
BA_REL_ "GenSigTimeoutTime" BU_SG_REL_ OCU SG_ 1312 AB_Anprall_Front_Beifahrer 2000;
BA_REL_ "GenSigTimeoutTime" BU_SG_REL_ OCU SG_ 1312 AB_Anprall_Front_Fahrer 2000;
BA_REL_ "GenSigTimeoutTime" BU_SG_REL_ OCU SG_ 1312 AB_Belegung_VB 2000;
BA_REL_ "GenSigTimeoutTime" BU_SG_REL_ OCU SG_ 1312 AB_Anprall_Seite_Fahrer 2000;
BA_REL_ "GenSigTimeoutTime" BU_SG_REL_ OCU SG_ 1312 AB_Crashschwere 2000;
BA_REL_ "GenSigTimeoutTime" BU_SG_REL_ OCU SG_ 1312 AB_Anforderung_USM 2000;
BA_REL_ "GenSigTimeoutTime" BU_SG_REL_ OCU SG_ 1312 AB_Gurtschloss_FA 2000;
BA_REL_ "GenSigTimeoutTime" BU_SG_REL_ OCU SG_ 1312 AB_Gurtschloss_BF 2000;
BA_REL_ "GenSigTimeoutTime" BU_SG_REL_ OCU SG_ 1312 AB_Gurtschloss_Reihe2_FA 2000;
BA_REL_ "GenSigTimeoutTime" BU_SG_REL_ OCU SG_ 1312 AB_Gurtschloss_Reihe2_MI 2000;
BA_REL_ "GenSigTimeoutTime" BU_SG_REL_ OCU SG_ 1312 AB_Gurtschloss_Reihe2_BF 2000;
BA_REL_ "GenSigTimeoutTime" BU_SG_REL_ OCU SG_ 1312 AB_Gurtschloss_Reihe3_FA 2000;
BA_REL_ "GenSigTimeoutTime" BU_SG_REL_ OCU SG_ 1312 AB_Gurtschloss_Reihe3_MI 2000;
BA_REL_ "GenSigTimeoutTime" BU_SG_REL_ OCU SG_ 1312 AB_Gurtschloss_Reihe3_BF 2000;
BA_REL_ "GenSigTimeoutTime" BU_SG_REL_ OCU SG_ 1312 AB_Sitzpos_Sens_FA 2000;
BA_REL_ "GenSigTimeoutTime" BU_SG_REL_ OCU SG_ 1312 AB_Sitzpos_Sens_BF 2000;
BA_REL_ "GenSigTimeoutTime" BU_SG_REL_ OCU SG_ 1633 AAG_Anhaenger_abgesteckt 1000;
BA_REL_ "GenSigTimeoutTime" BU_SG_REL_ OCU SG_ 1633 AAG_Anhaenger_erkannt 1000;
BA_REL_ "GenSigTimeoutTime" BU_SG_REL_ OCU SG_ 1633 AAG_LED_aktiv 1000;
BA_REL_ "GenSigTimeoutTime" BU_SG_REL_ OCU SG_ 2536703248 BAP_ACC_FSG_01_Header 5000;
BA_REL_ "GenSigTimeoutTime" BU_SG_REL_ OCU SG_ 2536704272 BAP_Aussenlicht_FSG_01_Header 5000;
BA_REL_ "GenSigTimeoutTime" BU_SG_REL_ OCU SG_ 2536708880 BAP_AWV_FSG_01_Header 5000;
BA_REL_ "GenSigTimeoutTime" BU_SG_REL_ OCU SG_ 2536711440 BAP_BatteryControl_FSG_01_Header 5000;
BA_REL_ "GenSigTimeoutTime" BU_SG_REL_ OCU SG_ 2536705808 BAP_BC_FSG_01_Header 5000;
BA_REL_ "GenSigTimeoutTime" BU_SG_REL_ OCU SG_ 2536705809 BAP_BC_FSG_02_Header 5000;
BA_REL_ "GenSigTimeoutTime" BU_SG_REL_ OCU SG_ 2536707856 BAP_Charisma_FSG_01_Header 5000;
BA_REL_ "GenSigTimeoutTime" BU_SG_REL_ OCU SG_ 2536705296 BAP_Doorlocking_FSG_01_Header 5000;
BA_REL_ "GenSigTimeoutTime" BU_SG_REL_ OCU SG_ 2536727312 BAP_Doors2_FSG_01_Header 5000;
BA_REL_ "GenSigTimeoutTime" BU_SG_REL_ OCU SG_ 2536724752 BAP_Doors_FSG_01_Header 5000;
BA_REL_ "GenSigTimeoutTime" BU_SG_REL_ OCU SG_ 2536715008 BAP_eCall_ASG_01_Header 800;
BA_REL_ "GenSigTimeoutTime" BU_SG_REL_ OCU SG_ 2536706832 BAP_Einheiten_FSG_01_Header 5000;
BA_REL_ "GenSigTimeoutTime" BU_SG_REL_ OCU SG_ 2536730112 BAP_ENI3_ASG_01_Header 500;
BA_REL_ "GenSigTimeoutTime" BU_SG_REL_ OCU SG_ 2536730113 BAP_ENI3_ASG_02_Header 500;
BA_REL_ "GenSigTimeoutTime" BU_SG_REL_ OCU SG_ 2536716032 BAP_ENI_ASG_01_Header 500;
BA_REL_ "GenSigTimeoutTime" BU_SG_REL_ OCU SG_ 2536716033 BAP_ENI_ASG_02_Header 500;
BA_REL_ "GenSigTimeoutTime" BU_SG_REL_ OCU SG_ 2536702992 BAP_HUD_FSG_01_Header 5000;
BA_REL_ "GenSigTimeoutTime" BU_SG_REL_ OCU SG_ 2536722944 BAP_IAA_PSO_ASG_01_Header 800;
BA_REL_ "GenSigTimeoutTime" BU_SG_REL_ OCU SG_ 2536722945 BAP_IAA_PSO_ASG_02_Header 800;
BA_REL_ "GenSigTimeoutTime" BU_SG_REL_ OCU SG_ 2536722946 BAP_IAA_PSO_ASG_03_Header 800;
BA_REL_ "GenSigTimeoutTime" BU_SG_REL_ OCU SG_ 2536722448 BAP_InfoSettings_FSG_01_Header 5000;
BA_REL_ "GenSigTimeoutTime" BU_SG_REL_ OCU SG_ 2536704016 BAP_Innenlicht_FSG_01_Header 5000;
BA_REL_ "GenSigTimeoutTime" BU_SG_REL_ OCU SG_ 2536718864 BAP_KlimaMaster_FSG_01_Header 5000;
BA_REL_ "GenSigTimeoutTime" BU_SG_REL_ OCU SG_ 2536708368 BAP_LDW_FSG_01_Header 5000;
BA_REL_ "GenSigTimeoutTime" BU_SG_REL_ OCU SG_ 2536705552 BAP_Mirror_FSG_01_Header 5000;
BA_REL_ "GenSigTimeoutTime" BU_SG_REL_ OCU SG_ 2536732432 BAP_MobDevKey_FSG_01_Header 5000;
BA_REL_ "GenSigTimeoutTime" BU_SG_REL_ OCU SG_ 2536734464 BAP_MobDevKeyOnline_ASG_01_Heade 800;
BA_REL_ "GenSigTimeoutTime" BU_SG_REL_ OCU SG_ 2536704528 BAP_OPS_FSG_01_Header 5000;
BA_REL_ "GenSigTimeoutTime" BU_SG_REL_ OCU SG_ 2536704529 BAP_OPS_FSG_02_Header 5000;
BA_REL_ "GenSigTimeoutTime" BU_SG_REL_ OCU SG_ 2536723728 BAP_PaCo_FSG_01_Header 5000;
BA_REL_ "GenSigTimeoutTime" BU_SG_REL_ OCU SG_ 2536702736 BAP_ParkHeater_FSG_01_Header 5000;
BA_REL_ "GenSigTimeoutTime" BU_SG_REL_ OCU SG_ 2536728336 BAP_REM2_FSG_01_Header 5000;
BA_REL_ "GenSigTimeoutTime" BU_SG_REL_ OCU SG_ 2536728337 BAP_REM2_FSG_02_Header 5000;
BA_REL_ "GenSigTimeoutTime" BU_SG_REL_ OCU SG_ 2536725264 BAP_REM_FSG_01_Header 5000;
BA_REL_ "GenSigTimeoutTime" BU_SG_REL_ OCU SG_ 2536725265 BAP_REM_FSG_02_Header 5000;
BA_REL_ "GenSigTimeoutTime" BU_SG_REL_ OCU SG_ 2536721936 BAP_RemoteServices_FSG_01_Header 5000;
BA_REL_ "GenSigTimeoutTime" BU_SG_REL_ OCU SG_ 2536730640 BAP_RSO_FSG_01_Header 5000;
BA_REL_ "GenSigTimeoutTime" BU_SG_REL_ OCU SG_ 2536717072 BAP_SeatPneumatic_FSG_01_Header 5000;
BA_REL_ "GenSigTimeoutTime" BU_SG_REL_ RDK_RS3 SG_ 2536703744 BAP_RDK_ASG_01_Header 800;
BA_REL_ "GenSigTimeoutTime" BU_SG_REL_ RDK_RS3 SG_ 2536703745 BAP_RDK_ASG_02_Header 800;
BA_REL_ "GenSigTimeoutTime" BU_SG_REL_ STH SG_ 64 AB_Crash_Int 500;
BA_REL_ "GenSigTimeoutTime" BU_SG_REL_ STH SG_ 64 AB_Stellgliedtest 500;
BA_REL_ "GenSigTimeoutTime" BU_SG_REL_ ZR_MIB_EINSTIEG_ab_Gen3 SG_ 680 ACC_Status_Anzeige 600;
BA_REL_ "GenSigTimeoutTime" BU_SG_REL_ ZR_MIB_EINSTIEG_ab_Gen3 SG_ 64 AB_Crash_Int 500;
BA_REL_ "GenSigTimeoutTime" BU_SG_REL_ ZR_MIB_EINSTIEG_ab_Gen3 SG_ 64 AB_Stellgliedtest 500;
BA_REL_ "GenSigTimeoutTime" BU_SG_REL_ ZR_MIB_EINSTIEG_ab_Gen3 SG_ 1312 AB_Belegung_VB 2000;
BA_REL_ "GenSigTimeoutTime" BU_SG_REL_ ZR_MIB_EINSTIEG_ab_Gen3 SG_ 1312 AB_Gurtschloss_FA 2000;
BA_REL_ "GenSigTimeoutTime" BU_SG_REL_ ZR_MIB_EINSTIEG_ab_Gen3 SG_ 1312 AB_Gurtschloss_BF 2000;
BA_REL_ "GenSigTimeoutTime" BU_SG_REL_ ZR_MIB_EINSTIEG_ab_Gen3 SG_ 1312 AB_Gurtschloss_Reihe2_FA 2000;
BA_REL_ "GenSigTimeoutTime" BU_SG_REL_ ZR_MIB_EINSTIEG_ab_Gen3 SG_ 1312 AB_Gurtschloss_Reihe2_MI 2000;
BA_REL_ "GenSigTimeoutTime" BU_SG_REL_ ZR_MIB_EINSTIEG_ab_Gen3 SG_ 1312 AB_Gurtschloss_Reihe2_BF 2000;
BA_REL_ "GenSigTimeoutTime" BU_SG_REL_ ZR_MIB_EINSTIEG_ab_Gen3 SG_ 1312 AB_Gurtschloss_Reihe3_FA 2000;
BA_REL_ "GenSigTimeoutTime" BU_SG_REL_ ZR_MIB_EINSTIEG_ab_Gen3 SG_ 1312 AB_Gurtschloss_Reihe3_MI 2000;
BA_REL_ "GenSigTimeoutTime" BU_SG_REL_ ZR_MIB_EINSTIEG_ab_Gen3 SG_ 1312 AB_Gurtschloss_Reihe3_BF 2000;
BA_REL_ "GenSigTimeoutTime" BU_SG_REL_ ZR_MIB_EINSTIEG_ab_Gen3 SG_ 1633 AAG_Anhaenger_erkannt 1000;
BA_REL_ "GenSigTimeoutTime" BU_SG_REL_ ZR_MIB_EINSTIEG_ab_Gen3 SG_ 2536703248 BAP_ACC_FSG_01_Header 5000;
BA_REL_ "GenSigTimeoutTime" BU_SG_REL_ ZR_MIB_EINSTIEG_ab_Gen3 SG_ 2536714496 BAP_Audio_ASG_01_Header 500;
BA_REL_ "GenSigTimeoutTime" BU_SG_REL_ ZR_MIB_EINSTIEG_ab_Gen3 SG_ 2536714497 BAP_Audio_ASG_02_Header 500;
BA_REL_ "GenSigTimeoutTime" BU_SG_REL_ ZR_MIB_EINSTIEG_ab_Gen3 SG_ 2536704272 BAP_Aussenlicht_FSG_01_Header 5000;
BA_REL_ "GenSigTimeoutTime" BU_SG_REL_ ZR_MIB_EINSTIEG_ab_Gen3 SG_ 2536708880 BAP_AWV_FSG_01_Header 5000;
BA_REL_ "GenSigTimeoutTime" BU_SG_REL_ ZR_MIB_EINSTIEG_ab_Gen3 SG_ 2536711440 BAP_BatteryControl_FSG_01_Header 5000;
BA_REL_ "GenSigTimeoutTime" BU_SG_REL_ ZR_MIB_EINSTIEG_ab_Gen3 SG_ 2536705808 BAP_BC_FSG_01_Header 5000;
BA_REL_ "GenSigTimeoutTime" BU_SG_REL_ ZR_MIB_EINSTIEG_ab_Gen3 SG_ 2536705809 BAP_BC_FSG_02_Header 5000;
BA_REL_ "GenSigTimeoutTime" BU_SG_REL_ ZR_MIB_EINSTIEG_ab_Gen3 SG_ 2536710928 BAP_BCmE_FSG_01_Header 5000;
BA_REL_ "GenSigTimeoutTime" BU_SG_REL_ ZR_MIB_EINSTIEG_ab_Gen3 SG_ 2536711696 BAP_Brake_FSG_01_Header 5000;
BA_REL_ "GenSigTimeoutTime" BU_SG_REL_ ZR_MIB_EINSTIEG_ab_Gen3 SG_ 2536733200 BAP_BSMOIS2_FSG_01_Header 5000;
BA_REL_ "GenSigTimeoutTime" BU_SG_REL_ ZR_MIB_EINSTIEG_ab_Gen3 SG_ 2536733456 BAP_BSMOIS3_FSG_01_Header 5000;
BA_REL_ "GenSigTimeoutTime" BU_SG_REL_ ZR_MIB_EINSTIEG_ab_Gen3 SG_ 2536732176 BAP_BSMOIS_FSG_01_Header 5000;
BA_REL_ "GenSigTimeoutTime" BU_SG_REL_ ZR_MIB_EINSTIEG_ab_Gen3 SG_ 2536734992 BAP_California_FSG_01_Header 5000;
BA_REL_ "GenSigTimeoutTime" BU_SG_REL_ ZR_MIB_EINSTIEG_ab_Gen3 SG_ 2536726802 BAP_Car2X_FSG_03_Header 5000;
BA_REL_ "GenSigTimeoutTime" BU_SG_REL_ ZR_MIB_EINSTIEG_ab_Gen3 SG_ 2536707856 BAP_Charisma_FSG_01_Header 5000;
BA_REL_ "GenSigTimeoutTime" BU_SG_REL_ ZR_MIB_EINSTIEG_ab_Gen3 SG_ 2536726544 BAP_ClimateDiag_FSG_01_Header 5000;
BA_REL_ "GenSigTimeoutTime" BU_SG_REL_ ZR_MIB_EINSTIEG_ab_Gen3 SG_ 2536705296 BAP_Doorlocking_FSG_01_Header 5000;
BA_REL_ "GenSigTimeoutTime" BU_SG_REL_ ZR_MIB_EINSTIEG_ab_Gen3 SG_ 2536715024 BAP_eCall_FSG_01_Header 5000;
BA_REL_ "GenSigTimeoutTime" BU_SG_REL_ ZR_MIB_EINSTIEG_ab_Gen3 SG_ 2536717328 BAP_EfficAssist_FSG_01_Header 5000;
BA_REL_ "GenSigTimeoutTime" BU_SG_REL_ ZR_MIB_EINSTIEG_ab_Gen3 SG_ 2536706832 BAP_Einheiten_FSG_01_Header 5000;
BA_REL_ "GenSigTimeoutTime" BU_SG_REL_ ZR_MIB_EINSTIEG_ab_Gen3 SG_ 2536725776 BAP_EngFunctions_FSG_01_Header 5000;
BA_REL_ "GenSigTimeoutTime" BU_SG_REL_ ZR_MIB_EINSTIEG_ab_Gen3 SG_ 2536724496 BAP_ENI2_FSG_01_Header 5000;
BA_REL_ "GenSigTimeoutTime" BU_SG_REL_ ZR_MIB_EINSTIEG_ab_Gen3 SG_ 2536724497 BAP_ENI2_FSG_02_Header 5000;
BA_REL_ "GenSigTimeoutTime" BU_SG_REL_ ZR_MIB_EINSTIEG_ab_Gen3 SG_ 2536716048 BAP_ENI_FSG_01_Header 5000;
BA_REL_ "GenSigTimeoutTime" BU_SG_REL_ ZR_MIB_EINSTIEG_ab_Gen3 SG_ 2536716049 BAP_ENI_FSG_02_Header 5000;
BA_REL_ "GenSigTimeoutTime" BU_SG_REL_ ZR_MIB_EINSTIEG_ab_Gen3 SG_ 2536721680 BAP_FAS_Profiles_FSG_01_Header 5000;
BA_REL_ "GenSigTimeoutTime" BU_SG_REL_ ZR_MIB_EINSTIEG_ab_Gen3 SG_ 2536702992 BAP_HUD_FSG_01_Header 5000;
BA_REL_ "GenSigTimeoutTime" BU_SG_REL_ ZR_MIB_EINSTIEG_ab_Gen3 SG_ 2536709136 BAP_Hybrid_FSG_01_Header 5000;
BA_REL_ "GenSigTimeoutTime" BU_SG_REL_ ZR_MIB_EINSTIEG_ab_Gen3 SG_ 2536722960 BAP_IAA_PSO_FSG_01_Header 5000;
BA_REL_ "GenSigTimeoutTime" BU_SG_REL_ ZR_MIB_EINSTIEG_ab_Gen3 SG_ 2536722434 BAP_InfoSettings_ASG_03_Header 500;
BA_REL_ "GenSigTimeoutTime" BU_SG_REL_ ZR_MIB_EINSTIEG_ab_Gen3 SG_ 2536704016 BAP_Innenlicht_FSG_01_Header 5000;
BA_REL_ "GenSigTimeoutTime" BU_SG_REL_ ZR_MIB_EINSTIEG_ab_Gen3 SG_ 2536702224 BAP_Klima1_FSG_01_Header 5000;
BA_REL_ "GenSigTimeoutTime" BU_SG_REL_ ZR_MIB_EINSTIEG_ab_Gen3 SG_ 2536702480 BAP_Klima2_FSG_01_Header 5000;
BA_REL_ "GenSigTimeoutTime" BU_SG_REL_ ZR_MIB_EINSTIEG_ab_Gen3 SG_ 2536718864 BAP_KlimaMaster_FSG_01_Header 5000;
BA_REL_ "GenSigTimeoutTime" BU_SG_REL_ ZR_MIB_EINSTIEG_ab_Gen3 SG_ 2536708368 BAP_LDW_FSG_01_Header 5000;
BA_REL_ "GenSigTimeoutTime" BU_SG_REL_ ZR_MIB_EINSTIEG_ab_Gen3 SG_ 2536705552 BAP_Mirror_FSG_01_Header 5000;
BA_REL_ "GenSigTimeoutTime" BU_SG_REL_ ZR_MIB_EINSTIEG_ab_Gen3 SG_ 2536710672 BAP_MKE_FSG_01_Header 5000;
BA_REL_ "GenSigTimeoutTime" BU_SG_REL_ ZR_MIB_EINSTIEG_ab_Gen3 SG_ 2536714752 BAP_Navigation_ASG_01_Header 500;
BA_REL_ "GenSigTimeoutTime" BU_SG_REL_ ZR_MIB_EINSTIEG_ab_Gen3 SG_ 2536714753 BAP_Navigation_ASG_02_Header 500;
BA_REL_ "GenSigTimeoutTime" BU_SG_REL_ ZR_MIB_EINSTIEG_ab_Gen3 SG_ 2536714754 BAP_Navigation_ASG_03_Header 500;
BA_REL_ "GenSigTimeoutTime" BU_SG_REL_ ZR_MIB_EINSTIEG_ab_Gen3 SG_ 2536714755 BAP_Navigation_ASG_04_Header 500;
BA_REL_ "GenSigTimeoutTime" BU_SG_REL_ ZR_MIB_EINSTIEG_ab_Gen3 SG_ 2536704528 BAP_OPS_FSG_01_Header 5000;
BA_REL_ "GenSigTimeoutTime" BU_SG_REL_ ZR_MIB_EINSTIEG_ab_Gen3 SG_ 2536704529 BAP_OPS_FSG_02_Header 5000;
BA_REL_ "GenSigTimeoutTime" BU_SG_REL_ ZR_MIB_EINSTIEG_ab_Gen3 SG_ 2536723728 BAP_PaCo_FSG_01_Header 5000;
BA_REL_ "GenSigTimeoutTime" BU_SG_REL_ ZR_MIB_EINSTIEG_ab_Gen3 SG_ 2536702736 BAP_ParkHeater_FSG_01_Header 5000;
BA_REL_ "GenSigTimeoutTime" BU_SG_REL_ ZR_MIB_EINSTIEG_ab_Gen3 SG_ 2536734737 BAP_PlugAndCharge_FSG_02_Header 5000;
BA_REL_ "GenSigTimeoutTime" BU_SG_REL_ ZR_MIB_EINSTIEG_ab_Gen3 SG_ 2536703760 BAP_RDK_FSG_01_Header 5000;
BA_REL_ "GenSigTimeoutTime" BU_SG_REL_ ZR_MIB_EINSTIEG_ab_Gen3 SG_ 2536721936 BAP_RemoteServices_FSG_01_Header 5000;
BA_REL_ "GenSigTimeoutTime" BU_SG_REL_ ZR_MIB_EINSTIEG_ab_Gen3 SG_ 2536731920 BAP_RollingAbility_FSG_01_Header 5000;
BA_REL_ "GenSigTimeoutTime" BU_SG_REL_ ZR_MIB_EINSTIEG_ab_Gen3 SG_ 2536704784 BAP_RVC_FSG_01_Header 5000;
BA_REL_ "GenSigTimeoutTime" BU_SG_REL_ ZR_MIB_EINSTIEG_ab_Gen3 SG_ 2536717072 BAP_SeatPneumatic_FSG_01_Header 5000;
BA_REL_ "GenSigTimeoutTime" BU_SG_REL_ ZR_MIB_EINSTIEG_ab_Gen3 SG_ 2536735488 BAP_SecEvents2_ASG_01_Header 800;
BA_REL_ "GenSigTimeoutTime" BU_SG_REL_ ZR_MIB_OPTION_ab_Gen3 SG_ 680 ACC_Status_Anzeige 600;
BA_REL_ "GenSigTimeoutTime" BU_SG_REL_ ZR_MIB_OPTION_ab_Gen3 SG_ 64 AB_Crash_Int 500;
BA_REL_ "GenSigTimeoutTime" BU_SG_REL_ ZR_MIB_OPTION_ab_Gen3 SG_ 64 AB_Stellgliedtest 500;
BA_REL_ "GenSigTimeoutTime" BU_SG_REL_ ZR_MIB_OPTION_ab_Gen3 SG_ 1312 AB_Belegung_VB 2000;
BA_REL_ "GenSigTimeoutTime" BU_SG_REL_ ZR_MIB_OPTION_ab_Gen3 SG_ 1312 AB_Gurtschloss_FA 2000;
BA_REL_ "GenSigTimeoutTime" BU_SG_REL_ ZR_MIB_OPTION_ab_Gen3 SG_ 1312 AB_Gurtschloss_BF 2000;
BA_REL_ "GenSigTimeoutTime" BU_SG_REL_ ZR_MIB_OPTION_ab_Gen3 SG_ 1312 AB_Gurtschloss_Reihe2_FA 2000;
BA_REL_ "GenSigTimeoutTime" BU_SG_REL_ ZR_MIB_OPTION_ab_Gen3 SG_ 1312 AB_Gurtschloss_Reihe2_MI 2000;
BA_REL_ "GenSigTimeoutTime" BU_SG_REL_ ZR_MIB_OPTION_ab_Gen3 SG_ 1312 AB_Gurtschloss_Reihe2_BF 2000;
BA_REL_ "GenSigTimeoutTime" BU_SG_REL_ ZR_MIB_OPTION_ab_Gen3 SG_ 1312 AB_Gurtschloss_Reihe3_FA 2000;
BA_REL_ "GenSigTimeoutTime" BU_SG_REL_ ZR_MIB_OPTION_ab_Gen3 SG_ 1312 AB_Gurtschloss_Reihe3_MI 2000;
BA_REL_ "GenSigTimeoutTime" BU_SG_REL_ ZR_MIB_OPTION_ab_Gen3 SG_ 1312 AB_Gurtschloss_Reihe3_BF 2000;
BA_REL_ "GenSigTimeoutTime" BU_SG_REL_ ZR_MIB_OPTION_ab_Gen3 SG_ 1633 AAG_Anhaenger_erkannt 1000;
BA_REL_ "GenSigTimeoutTime" BU_SG_REL_ ZR_MIB_OPTION_ab_Gen3 SG_ 2536703248 BAP_ACC_FSG_01_Header 5000;
BA_REL_ "GenSigTimeoutTime" BU_SG_REL_ ZR_MIB_OPTION_ab_Gen3 SG_ 2536714496 BAP_Audio_ASG_01_Header 500;
BA_REL_ "GenSigTimeoutTime" BU_SG_REL_ ZR_MIB_OPTION_ab_Gen3 SG_ 2536714497 BAP_Audio_ASG_02_Header 500;
BA_REL_ "GenSigTimeoutTime" BU_SG_REL_ ZR_MIB_OPTION_ab_Gen3 SG_ 2536714504 BAP_Audio_ASG_09_Header 500;
BA_REL_ "GenSigTimeoutTime" BU_SG_REL_ ZR_MIB_OPTION_ab_Gen3 SG_ 2536714505 BAP_Audio_ASG_10_Header 500;
BA_REL_ "GenSigTimeoutTime" BU_SG_REL_ ZR_MIB_OPTION_ab_Gen3 SG_ 2536714506 BAP_Audio_ASG_11_Header 500;
BA_REL_ "GenSigTimeoutTime" BU_SG_REL_ ZR_MIB_OPTION_ab_Gen3 SG_ 2536714507 BAP_Audio_ASG_12_Header 500;
BA_REL_ "GenSigTimeoutTime" BU_SG_REL_ ZR_MIB_OPTION_ab_Gen3 SG_ 2536704272 BAP_Aussenlicht_FSG_01_Header 5000;
BA_REL_ "GenSigTimeoutTime" BU_SG_REL_ ZR_MIB_OPTION_ab_Gen3 SG_ 2536708880 BAP_AWV_FSG_01_Header 5000;
BA_REL_ "GenSigTimeoutTime" BU_SG_REL_ ZR_MIB_OPTION_ab_Gen3 SG_ 2536711440 BAP_BatteryControl_FSG_01_Header 5000;
BA_REL_ "GenSigTimeoutTime" BU_SG_REL_ ZR_MIB_OPTION_ab_Gen3 SG_ 2536705808 BAP_BC_FSG_01_Header 5000;
BA_REL_ "GenSigTimeoutTime" BU_SG_REL_ ZR_MIB_OPTION_ab_Gen3 SG_ 2536705809 BAP_BC_FSG_02_Header 5000;
BA_REL_ "GenSigTimeoutTime" BU_SG_REL_ ZR_MIB_OPTION_ab_Gen3 SG_ 2536710928 BAP_BCmE_FSG_01_Header 5000;
BA_REL_ "GenSigTimeoutTime" BU_SG_REL_ ZR_MIB_OPTION_ab_Gen3 SG_ 2536711696 BAP_Brake_FSG_01_Header 5000;
BA_REL_ "GenSigTimeoutTime" BU_SG_REL_ ZR_MIB_OPTION_ab_Gen3 SG_ 2536733200 BAP_BSMOIS2_FSG_01_Header 5000;
BA_REL_ "GenSigTimeoutTime" BU_SG_REL_ ZR_MIB_OPTION_ab_Gen3 SG_ 2536733456 BAP_BSMOIS3_FSG_01_Header 5000;
BA_REL_ "GenSigTimeoutTime" BU_SG_REL_ ZR_MIB_OPTION_ab_Gen3 SG_ 2536732176 BAP_BSMOIS_FSG_01_Header 5000;
BA_REL_ "GenSigTimeoutTime" BU_SG_REL_ ZR_MIB_OPTION_ab_Gen3 SG_ 2536734992 BAP_California_FSG_01_Header 5000;
BA_REL_ "GenSigTimeoutTime" BU_SG_REL_ ZR_MIB_OPTION_ab_Gen3 SG_ 2536726802 BAP_Car2X_FSG_03_Header 5000;
BA_REL_ "GenSigTimeoutTime" BU_SG_REL_ ZR_MIB_OPTION_ab_Gen3 SG_ 2536707856 BAP_Charisma_FSG_01_Header 5000;
BA_REL_ "GenSigTimeoutTime" BU_SG_REL_ ZR_MIB_OPTION_ab_Gen3 SG_ 2536726544 BAP_ClimateDiag_FSG_01_Header 5000;
BA_REL_ "GenSigTimeoutTime" BU_SG_REL_ ZR_MIB_OPTION_ab_Gen3 SG_ 2536705296 BAP_Doorlocking_FSG_01_Header 5000;
BA_REL_ "GenSigTimeoutTime" BU_SG_REL_ ZR_MIB_OPTION_ab_Gen3 SG_ 2536734224 BAP_DrivingDynamics_FSG_01_Hdr 5000;
BA_REL_ "GenSigTimeoutTime" BU_SG_REL_ ZR_MIB_OPTION_ab_Gen3 SG_ 2536715024 BAP_eCall_FSG_01_Header 5000;
BA_REL_ "GenSigTimeoutTime" BU_SG_REL_ ZR_MIB_OPTION_ab_Gen3 SG_ 2536717328 BAP_EfficAssist_FSG_01_Header 5000;
BA_REL_ "GenSigTimeoutTime" BU_SG_REL_ ZR_MIB_OPTION_ab_Gen3 SG_ 2536706832 BAP_Einheiten_FSG_01_Header 5000;
BA_REL_ "GenSigTimeoutTime" BU_SG_REL_ ZR_MIB_OPTION_ab_Gen3 SG_ 2536725776 BAP_EngFunctions_FSG_01_Header 5000;
BA_REL_ "GenSigTimeoutTime" BU_SG_REL_ ZR_MIB_OPTION_ab_Gen3 SG_ 2536724496 BAP_ENI2_FSG_01_Header 5000;
BA_REL_ "GenSigTimeoutTime" BU_SG_REL_ ZR_MIB_OPTION_ab_Gen3 SG_ 2536724497 BAP_ENI2_FSG_02_Header 5000;
BA_REL_ "GenSigTimeoutTime" BU_SG_REL_ ZR_MIB_OPTION_ab_Gen3 SG_ 2536716048 BAP_ENI_FSG_01_Header 5000;
BA_REL_ "GenSigTimeoutTime" BU_SG_REL_ ZR_MIB_OPTION_ab_Gen3 SG_ 2536716049 BAP_ENI_FSG_02_Header 5000;
BA_REL_ "GenSigTimeoutTime" BU_SG_REL_ ZR_MIB_OPTION_ab_Gen3 SG_ 2536721680 BAP_FAS_Profiles_FSG_01_Header 5000;
BA_REL_ "GenSigTimeoutTime" BU_SG_REL_ ZR_MIB_OPTION_ab_Gen3 SG_ 2536702992 BAP_HUD_FSG_01_Header 5000;
BA_REL_ "GenSigTimeoutTime" BU_SG_REL_ ZR_MIB_OPTION_ab_Gen3 SG_ 2536709136 BAP_Hybrid_FSG_01_Header 5000;
BA_REL_ "GenSigTimeoutTime" BU_SG_REL_ ZR_MIB_OPTION_ab_Gen3 SG_ 2536722960 BAP_IAA_PSO_FSG_01_Header 5000;
BA_REL_ "GenSigTimeoutTime" BU_SG_REL_ ZR_MIB_OPTION_ab_Gen3 SG_ 2536722434 BAP_InfoSettings_ASG_03_Header 500;
BA_REL_ "GenSigTimeoutTime" BU_SG_REL_ ZR_MIB_OPTION_ab_Gen3 SG_ 2536704016 BAP_Innenlicht_FSG_01_Header 5000;
BA_REL_ "GenSigTimeoutTime" BU_SG_REL_ ZR_MIB_OPTION_ab_Gen3 SG_ 2536702224 BAP_Klima1_FSG_01_Header 5000;
BA_REL_ "GenSigTimeoutTime" BU_SG_REL_ ZR_MIB_OPTION_ab_Gen3 SG_ 2536702480 BAP_Klima2_FSG_01_Header 5000;
BA_REL_ "GenSigTimeoutTime" BU_SG_REL_ ZR_MIB_OPTION_ab_Gen3 SG_ 2536718864 BAP_KlimaMaster_FSG_01_Header 5000;
BA_REL_ "GenSigTimeoutTime" BU_SG_REL_ ZR_MIB_OPTION_ab_Gen3 SG_ 2536708368 BAP_LDW_FSG_01_Header 5000;
BA_REL_ "GenSigTimeoutTime" BU_SG_REL_ ZR_MIB_OPTION_ab_Gen3 SG_ 2536705552 BAP_Mirror_FSG_01_Header 5000;
BA_REL_ "GenSigTimeoutTime" BU_SG_REL_ ZR_MIB_OPTION_ab_Gen3 SG_ 2536710672 BAP_MKE_FSG_01_Header 5000;
BA_REL_ "GenSigTimeoutTime" BU_SG_REL_ ZR_MIB_OPTION_ab_Gen3 SG_ 2536732432 BAP_MobDevKey_FSG_01_Header 5000;
BA_REL_ "GenSigTimeoutTime" BU_SG_REL_ ZR_MIB_OPTION_ab_Gen3 SG_ 2536714752 BAP_Navigation_ASG_01_Header 500;
BA_REL_ "GenSigTimeoutTime" BU_SG_REL_ ZR_MIB_OPTION_ab_Gen3 SG_ 2536714753 BAP_Navigation_ASG_02_Header 500;
BA_REL_ "GenSigTimeoutTime" BU_SG_REL_ ZR_MIB_OPTION_ab_Gen3 SG_ 2536714754 BAP_Navigation_ASG_03_Header 500;
BA_REL_ "GenSigTimeoutTime" BU_SG_REL_ ZR_MIB_OPTION_ab_Gen3 SG_ 2536714755 BAP_Navigation_ASG_04_Header 500;
BA_REL_ "GenSigTimeoutTime" BU_SG_REL_ ZR_MIB_OPTION_ab_Gen3 SG_ 2536712704 BAP_OnlineFunction_ASG_01_Header 800;
BA_REL_ "GenSigTimeoutTime" BU_SG_REL_ ZR_MIB_OPTION_ab_Gen3 SG_ 2536712705 BAP_OnlineFunction_ASG_02_Header 800;
BA_REL_ "GenSigTimeoutTime" BU_SG_REL_ ZR_MIB_OPTION_ab_Gen3 SG_ 2536704528 BAP_OPS_FSG_01_Header 5000;
BA_REL_ "GenSigTimeoutTime" BU_SG_REL_ ZR_MIB_OPTION_ab_Gen3 SG_ 2536704529 BAP_OPS_FSG_02_Header 5000;
BA_REL_ "GenSigTimeoutTime" BU_SG_REL_ ZR_MIB_OPTION_ab_Gen3 SG_ 2536723728 BAP_PaCo_FSG_01_Header 5000;
BA_REL_ "GenSigTimeoutTime" BU_SG_REL_ ZR_MIB_OPTION_ab_Gen3 SG_ 2536702736 BAP_ParkHeater_FSG_01_Header 5000;
BA_REL_ "GenSigTimeoutTime" BU_SG_REL_ ZR_MIB_OPTION_ab_Gen3 SG_ 2536734737 BAP_PlugAndCharge_FSG_02_Header 5000;
BA_REL_ "GenSigTimeoutTime" BU_SG_REL_ ZR_MIB_OPTION_ab_Gen3 SG_ 2536703760 BAP_RDK_FSG_01_Header 5000;
BA_REL_ "GenSigTimeoutTime" BU_SG_REL_ ZR_MIB_OPTION_ab_Gen3 SG_ 2536721936 BAP_RemoteServices_FSG_01_Header 5000;
BA_REL_ "GenSigTimeoutTime" BU_SG_REL_ ZR_MIB_OPTION_ab_Gen3 SG_ 2536731920 BAP_RollingAbility_FSG_01_Header 5000;
BA_REL_ "GenSigTimeoutTime" BU_SG_REL_ ZR_MIB_OPTION_ab_Gen3 SG_ 2536704784 BAP_RVC_FSG_01_Header 5000;
BA_REL_ "GenSigTimeoutTime" BU_SG_REL_ ZR_MIB_OPTION_ab_Gen3 SG_ 2536717072 BAP_SeatPneumatic_FSG_01_Header 5000;
BA_REL_ "GenSigTimeoutTime" BU_SG_REL_ ZR_MIB_OPTION_ab_Gen3 SG_ 2536735488 BAP_SecEvents2_ASG_01_Header 800;
BA_REL_ "GenSigTimeoutTime" BU_SG_REL_ ZR_MIB_TOP_ab_Gen3 SG_ 680 ACC_Status_Anzeige 600;
BA_REL_ "GenSigTimeoutTime" BU_SG_REL_ ZR_MIB_TOP_ab_Gen3 SG_ 1660 AGA_Verstaerker_Mute 5000;
BA_REL_ "GenSigTimeoutTime" BU_SG_REL_ ZR_MIB_TOP_ab_Gen3 SG_ 64 AB_Crash_Int 500;
BA_REL_ "GenSigTimeoutTime" BU_SG_REL_ ZR_MIB_TOP_ab_Gen3 SG_ 64 AB_Stellgliedtest 500;
BA_REL_ "GenSigTimeoutTime" BU_SG_REL_ ZR_MIB_TOP_ab_Gen3 SG_ 1312 AB_Belegung_VB 2000;
BA_REL_ "GenSigTimeoutTime" BU_SG_REL_ ZR_MIB_TOP_ab_Gen3 SG_ 1312 AB_Gurtschloss_BF 2000;
BA_REL_ "GenSigTimeoutTime" BU_SG_REL_ ZR_MIB_TOP_ab_Gen3 SG_ 1312 AB_Gurtschloss_Reihe2_FA 2000;
BA_REL_ "GenSigTimeoutTime" BU_SG_REL_ ZR_MIB_TOP_ab_Gen3 SG_ 1312 AB_Gurtschloss_Reihe2_MI 2000;
BA_REL_ "GenSigTimeoutTime" BU_SG_REL_ ZR_MIB_TOP_ab_Gen3 SG_ 1312 AB_Gurtschloss_Reihe2_BF 2000;
BA_REL_ "GenSigTimeoutTime" BU_SG_REL_ ZR_MIB_TOP_ab_Gen3 SG_ 1633 AAG_Anhaenger_erkannt 1000;
BA_REL_ "GenSigTimeoutTime" BU_SG_REL_ ZR_MIB_TOP_ab_Gen3 SG_ 2536703248 BAP_ACC_FSG_01_Header 5000;
BA_REL_ "GenSigTimeoutTime" BU_SG_REL_ ZR_MIB_TOP_ab_Gen3 SG_ 2536714496 BAP_Audio_ASG_01_Header 500;
BA_REL_ "GenSigTimeoutTime" BU_SG_REL_ ZR_MIB_TOP_ab_Gen3 SG_ 2536714497 BAP_Audio_ASG_02_Header 500;
BA_REL_ "GenSigTimeoutTime" BU_SG_REL_ ZR_MIB_TOP_ab_Gen3 SG_ 2536704272 BAP_Aussenlicht_FSG_01_Header 5000;
BA_REL_ "GenSigTimeoutTime" BU_SG_REL_ ZR_MIB_TOP_ab_Gen3 SG_ 2536708880 BAP_AWV_FSG_01_Header 5000;
BA_REL_ "GenSigTimeoutTime" BU_SG_REL_ ZR_MIB_TOP_ab_Gen3 SG_ 2536711440 BAP_BatteryControl_FSG_01_Header 5000;
BA_REL_ "GenSigTimeoutTime" BU_SG_REL_ ZR_MIB_TOP_ab_Gen3 SG_ 2536705808 BAP_BC_FSG_01_Header 5000;
BA_REL_ "GenSigTimeoutTime" BU_SG_REL_ ZR_MIB_TOP_ab_Gen3 SG_ 2536705809 BAP_BC_FSG_02_Header 5000;
BA_REL_ "GenSigTimeoutTime" BU_SG_REL_ ZR_MIB_TOP_ab_Gen3 SG_ 2536710928 BAP_BCmE_FSG_01_Header 5000;
BA_REL_ "GenSigTimeoutTime" BU_SG_REL_ ZR_MIB_TOP_ab_Gen3 SG_ 2536711696 BAP_Brake_FSG_01_Header 5000;
BA_REL_ "GenSigTimeoutTime" BU_SG_REL_ ZR_MIB_TOP_ab_Gen3 SG_ 2536707856 BAP_Charisma_FSG_01_Header 5000;
BA_REL_ "GenSigTimeoutTime" BU_SG_REL_ ZR_MIB_TOP_ab_Gen3 SG_ 2536719632 BAP_DisplayConfig_FSG_01_Header 5000;
BA_REL_ "GenSigTimeoutTime" BU_SG_REL_ ZR_MIB_TOP_ab_Gen3 SG_ 2536705296 BAP_Doorlocking_FSG_01_Header 5000;
BA_REL_ "GenSigTimeoutTime" BU_SG_REL_ ZR_MIB_TOP_ab_Gen3 SG_ 2536715024 BAP_eCall_FSG_01_Header 5000;
BA_REL_ "GenSigTimeoutTime" BU_SG_REL_ ZR_MIB_TOP_ab_Gen3 SG_ 2536717328 BAP_EfficAssist_FSG_01_Header 5000;
BA_REL_ "GenSigTimeoutTime" BU_SG_REL_ ZR_MIB_TOP_ab_Gen3 SG_ 2536706832 BAP_Einheiten_FSG_01_Header 5000;
BA_REL_ "GenSigTimeoutTime" BU_SG_REL_ ZR_MIB_TOP_ab_Gen3 SG_ 2536725776 BAP_EngFunctions_FSG_01_Header 5000;
BA_REL_ "GenSigTimeoutTime" BU_SG_REL_ ZR_MIB_TOP_ab_Gen3 SG_ 2536724496 BAP_ENI2_FSG_01_Header 5000;
BA_REL_ "GenSigTimeoutTime" BU_SG_REL_ ZR_MIB_TOP_ab_Gen3 SG_ 2536724497 BAP_ENI2_FSG_02_Header 5000;
BA_REL_ "GenSigTimeoutTime" BU_SG_REL_ ZR_MIB_TOP_ab_Gen3 SG_ 2536716048 BAP_ENI_FSG_01_Header 5000;
BA_REL_ "GenSigTimeoutTime" BU_SG_REL_ ZR_MIB_TOP_ab_Gen3 SG_ 2536716049 BAP_ENI_FSG_02_Header 5000;
BA_REL_ "GenSigTimeoutTime" BU_SG_REL_ ZR_MIB_TOP_ab_Gen3 SG_ 2536721680 BAP_FAS_Profiles_FSG_01_Header 5000;
BA_REL_ "GenSigTimeoutTime" BU_SG_REL_ ZR_MIB_TOP_ab_Gen3 SG_ 2536707088 BAP_Homelink_FSG_01_Header 5000;
BA_REL_ "GenSigTimeoutTime" BU_SG_REL_ ZR_MIB_TOP_ab_Gen3 SG_ 2536702992 BAP_HUD_FSG_01_Header 5000;
BA_REL_ "GenSigTimeoutTime" BU_SG_REL_ ZR_MIB_TOP_ab_Gen3 SG_ 2536709136 BAP_Hybrid_FSG_01_Header 5000;
BA_REL_ "GenSigTimeoutTime" BU_SG_REL_ ZR_MIB_TOP_ab_Gen3 SG_ 2536722960 BAP_IAA_PSO_FSG_01_Header 5000;
BA_REL_ "GenSigTimeoutTime" BU_SG_REL_ ZR_MIB_TOP_ab_Gen3 SG_ 2536722434 BAP_InfoSettings_ASG_03_Header 500;
BA_REL_ "GenSigTimeoutTime" BU_SG_REL_ ZR_MIB_TOP_ab_Gen3 SG_ 2536704016 BAP_Innenlicht_FSG_01_Header 5000;
BA_REL_ "GenSigTimeoutTime" BU_SG_REL_ ZR_MIB_TOP_ab_Gen3 SG_ 2536702224 BAP_Klima1_FSG_01_Header 5000;
BA_REL_ "GenSigTimeoutTime" BU_SG_REL_ ZR_MIB_TOP_ab_Gen3 SG_ 2536702480 BAP_Klima2_FSG_01_Header 5000;
BA_REL_ "GenSigTimeoutTime" BU_SG_REL_ ZR_MIB_TOP_ab_Gen3 SG_ 2536718864 BAP_KlimaMaster_FSG_01_Header 5000;
BA_REL_ "GenSigTimeoutTime" BU_SG_REL_ ZR_MIB_TOP_ab_Gen3 SG_ 2536708368 BAP_LDW_FSG_01_Header 5000;
BA_REL_ "GenSigTimeoutTime" BU_SG_REL_ ZR_MIB_TOP_ab_Gen3 SG_ 2536715264 BAP_MFL_ASG_01_Header 800;
BA_REL_ "GenSigTimeoutTime" BU_SG_REL_ ZR_MIB_TOP_ab_Gen3 SG_ 2536705552 BAP_Mirror_FSG_01_Header 5000;
BA_REL_ "GenSigTimeoutTime" BU_SG_REL_ ZR_MIB_TOP_ab_Gen3 SG_ 2536710672 BAP_MKE_FSG_01_Header 5000;
BA_REL_ "GenSigTimeoutTime" BU_SG_REL_ ZR_MIB_TOP_ab_Gen3 SG_ 2536714752 BAP_Navigation_ASG_01_Header 500;
BA_REL_ "GenSigTimeoutTime" BU_SG_REL_ ZR_MIB_TOP_ab_Gen3 SG_ 2536714753 BAP_Navigation_ASG_02_Header 500;
BA_REL_ "GenSigTimeoutTime" BU_SG_REL_ ZR_MIB_TOP_ab_Gen3 SG_ 2536714754 BAP_Navigation_ASG_03_Header 500;
BA_REL_ "GenSigTimeoutTime" BU_SG_REL_ ZR_MIB_TOP_ab_Gen3 SG_ 2536714755 BAP_Navigation_ASG_04_Header 500;
BA_REL_ "GenSigTimeoutTime" BU_SG_REL_ ZR_MIB_TOP_ab_Gen3 SG_ 2536712704 BAP_OnlineFunction_ASG_01_Header 800;
BA_REL_ "GenSigTimeoutTime" BU_SG_REL_ ZR_MIB_TOP_ab_Gen3 SG_ 2536712705 BAP_OnlineFunction_ASG_02_Header 800;
BA_REL_ "GenSigTimeoutTime" BU_SG_REL_ ZR_MIB_TOP_ab_Gen3 SG_ 2536704528 BAP_OPS_FSG_01_Header 5000;
BA_REL_ "GenSigTimeoutTime" BU_SG_REL_ ZR_MIB_TOP_ab_Gen3 SG_ 2536704529 BAP_OPS_FSG_02_Header 5000;
BA_REL_ "GenSigTimeoutTime" BU_SG_REL_ ZR_MIB_TOP_ab_Gen3 SG_ 2536723728 BAP_PaCo_FSG_01_Header 5000;
BA_REL_ "GenSigTimeoutTime" BU_SG_REL_ ZR_MIB_TOP_ab_Gen3 SG_ 2536702736 BAP_ParkHeater_FSG_01_Header 5000;
BA_REL_ "GenSigTimeoutTime" BU_SG_REL_ ZR_MIB_TOP_ab_Gen3 SG_ 2536734737 BAP_PlugAndCharge_FSG_02_Header 5000;
BA_REL_ "GenSigTimeoutTime" BU_SG_REL_ ZR_MIB_TOP_ab_Gen3 SG_ 2536716560 BAP_RangeData_FSG_01_Header 5000;
BA_REL_ "GenSigTimeoutTime" BU_SG_REL_ ZR_MIB_TOP_ab_Gen3 SG_ 2536703760 BAP_RDK_FSG_01_Header 5000;
BA_REL_ "GenSigTimeoutTime" BU_SG_REL_ ZR_MIB_TOP_ab_Gen3 SG_ 2536721936 BAP_RemoteServices_FSG_01_Header 5000;
BA_REL_ "GenSigTimeoutTime" BU_SG_REL_ ZR_MIB_TOP_ab_Gen3 SG_ 2536731920 BAP_RollingAbility_FSG_01_Header 5000;
BA_REL_ "GenSigTimeoutTime" BU_SG_REL_ ZR_MIB_TOP_ab_Gen3 SG_ 2536704784 BAP_RVC_FSG_01_Header 5000;
BA_REL_ "GenSigTimeoutTime" BU_SG_REL_ ZR_MIB_TOP_ab_Gen3 SG_ 2536717072 BAP_SeatPneumatic_FSG_01_Header 5000;
VAL_ 2589283939 LC_FES_Viewmode 0 "keineAnsteuerung" 1 "FES_View1" 2 "FES_View2" ;
VAL_ 2589283939 LC_FES_Aktive_Ebene_SOLL 0 "keineAnsteuerung" 1 "Ebene1aktiv" 2 "Ebene2aktiv" 3 "Ebene3aktiv" 4 "Ebene4aktiv" 5 "Ebene5aktiv" 6 "Ebene6aktiv" 7 "Ebene7aktiv" 8 "Ebene8aktiv" 9 "Ebene9aktiv" 10 "Ebene10aktiv" 11 "Ebene11aktiv" 12 "Ebene12aktiv" 13 "Ebene13aktiv" 14 "Ebene14aktiv" 15 "Ebene15aktiv" ;
VAL_ 2589283940 AC_KBI_Sec_View_Request 0 "noRequest" 1 "Deaktiviert" 2 "Aktiviert" ;
VAL_ 2589283940 AC_KBI_View_Request 0 "noRequest" 1 "View1" 2 "View2" 3 "View3" 4 "View4" 5 "View5" 6 "View6" 7 "View7" 8 "View8" 9 "View9" 10 "View10" 11 "View11" 12 "View12" 13 "View13" 14 "View14" 15 "View15" 16 "View16" 17 "View17" 18 "View18" 19 "View19" 20 "View20" 21 "View21" 22 "View22" 23 "View23" 24 "View24" 25 "reserved" 26 "reserved" 27 "reserved" 28 "reserved" 29 "reserved" 30 "reserved" 31 "reserved" ;
VAL_ 2589283940 AC_FES_Aktive_Atmosphere 0 "keineAnsteuerung" 1 "Atmosphere_1" 2 "Atmosphere_2" 3 "Atmosphere_3" 4 "Atmosphere_4" 5 "Atmosphere_5" 6 "Atmosphere_6" 7 "Atmosphere_7" 8 "Atmosphere_8" 9 "Atmosphere_9" 10 "Atmosphere_10" 11 "Atmosphere_11" 12 "Atmosphere_12" 13 "Atmosphere_13" 14 "Atmosphere_14" 15 "Atmosphere_15" 16 "Atmosphere_16" 17 "Atmosphere_17" 18 "Atmosphere_18" 19 "Atmosphere_19" 20 "Atmosphere_20" 21 "Atmosphere_21" 22 "Atmosphere_22" 23 "Atmosphere_23" 24 "Atmosphere_24" 25 "Atmosphere_25" 26 "Atmosphere_26" 27 "Atmosphere_27" 28 "Atmosphere_28" 29 "Atmosphere_29" 30 "Atmosphere_30" 31 "Atmosphere_31" 32 "Atmosphere_32" ;
VAL_ 2589283940 AC_FES_Atmosphere_1 0 "kein_Profil" 1 "Atmosphere_1" 2 "Atmosphere_2" 3 "Atmosphere_3" 4 "Atmosphere_4" 5 "Atmosphere_5" 6 "Atmosphere_6" 7 "Atmosphere_7" 8 "Atmosphere_8" 9 "Atmosphere_9" 10 "Atmosphere_10" 11 "Atmosphere_11" 12 "Atmosphere_12" 13 "Atmosphere_13" 14 "Atmosphere_14" 15 "Atmosphere_15" 16 "Atmosphere_16" 17 "Atmosphere_17" 18 "Atmosphere_18" 19 "Atmosphere_19" 20 "Atmosphere_20" 21 "Atmosphere_21" 22 "Atmosphere_22" 23 "Atmosphere_23" 24 "Atmosphere_24" 25 "Atmosphere_25" 26 "Atmosphere_26" 27 "Atmosphere_27" 28 "Atmosphere_28" 29 "Atmosphere_29" 30 "Atmosphere_30" 31 "Atmosphere_31" 32 "Atmosphere_32" ;
VAL_ 2589283940 AC_FES_Atmosphere_2 0 "kein_Profil" 1 "Atmosphere_1" 2 "Atmosphere_2" 3 "Atmosphere_3" 4 "Atmosphere_4" 5 "Atmosphere_5" 6 "Atmosphere_6" 7 "Atmosphere_7" 8 "Atmosphere_8" 9 "Atmosphere_9" 10 "Atmosphere_10" 11 "Atmosphere_11" 12 "Atmosphere_12" 13 "Atmosphere_13" 14 "Atmosphere_14" 15 "Atmosphere_15" 16 "Atmosphere_16" 17 "Atmosphere_17" 18 "Atmosphere_18" 19 "Atmosphere_19" 20 "Atmosphere_20" 21 "Atmosphere_21" 22 "Atmosphere_22" 23 "Atmosphere_23" 24 "Atmosphere_24" 25 "Atmosphere_25" 26 "Atmosphere_26" 27 "Atmosphere_27" 28 "Atmosphere_28" 29 "Atmosphere_29" 30 "Atmosphere_30" 31 "Atmosphere_31" 32 "Atmosphere_32" ;
VAL_ 2589283940 AC_FES_Atmosphere_3 0 "kein_Profil" 1 "Atmosphere_1" 2 "Atmosphere_2" 3 "Atmosphere_3" 4 "Atmosphere_4" 5 "Atmosphere_5" 6 "Atmosphere_6" 7 "Atmosphere_7" 8 "Atmosphere_8" 9 "Atmosphere_9" 10 "Atmosphere_10" 11 "Atmosphere_11" 12 "Atmosphere_12" 13 "Atmosphere_13" 14 "Atmosphere_14" 15 "Atmosphere_15" 16 "Atmosphere_16" 17 "Atmosphere_17" 18 "Atmosphere_18" 19 "Atmosphere_19" 20 "Atmosphere_20" 21 "Atmosphere_21" 22 "Atmosphere_22" 23 "Atmosphere_23" 24 "Atmosphere_24" 25 "Atmosphere_25" 26 "Atmosphere_26" 27 "Atmosphere_27" 28 "Atmosphere_28" 29 "Atmosphere_29" 30 "Atmosphere_30" 31 "Atmosphere_31" 32 "Atmosphere_32" ;
VAL_ 2589283940 AC_FES_Atmosphere_4 0 "kein_Profil" 1 "Atmosphere_1" 2 "Atmosphere_2" 3 "Atmosphere_3" 4 "Atmosphere_4" 5 "Atmosphere_5" 6 "Atmosphere_6" 7 "Atmosphere_7" 8 "Atmosphere_8" 9 "Atmosphere_9" 10 "Atmosphere_10" 11 "Atmosphere_11" 12 "Atmosphere_12" 13 "Atmosphere_13" 14 "Atmosphere_14" 15 "Atmosphere_15" 16 "Atmosphere_16" 17 "Atmosphere_17" 18 "Atmosphere_18" 19 "Atmosphere_19" 20 "Atmosphere_20" 21 "Atmosphere_21" 22 "Atmosphere_22" 23 "Atmosphere_23" 24 "Atmosphere_24" 25 "Atmosphere_25" 26 "Atmosphere_26" 27 "Atmosphere_27" 28 "Atmosphere_28" 29 "Atmosphere_29" 30 "Atmosphere_30" 31 "Atmosphere_31" 32 "Atmosphere_32" ;
VAL_ 2589283940 AC_FES_Atmosphere_5 0 "kein_Profil" 1 "Atmosphere_1" 2 "Atmosphere_2" 3 "Atmosphere_3" 4 "Atmosphere_4" 5 "Atmosphere_5" 6 "Atmosphere_6" 7 "Atmosphere_7" 8 "Atmosphere_8" 9 "Atmosphere_9" 10 "Atmosphere_10" 11 "Atmosphere_11" 12 "Atmosphere_12" 13 "Atmosphere_13" 14 "Atmosphere_14" 15 "Atmosphere_15" 16 "Atmosphere_16" 17 "Atmosphere_17" 18 "Atmosphere_18" 19 "Atmosphere_19" 20 "Atmosphere_20" 21 "Atmosphere_21" 22 "Atmosphere_22" 23 "Atmosphere_23" 24 "Atmosphere_24" 25 "Atmosphere_25" 26 "Atmosphere_26" 27 "Atmosphere_27" 28 "Atmosphere_28" 29 "Atmosphere_29" 30 "Atmosphere_30" 31 "Atmosphere_31" 32 "Atmosphere_32" ;
VAL_ 2589283940 AC_FES_Atmosphere_6 0 "kein_Profil" 1 "Atmosphere_1" 2 "Atmosphere_2" 3 "Atmosphere_3" 4 "Atmosphere_4" 5 "Atmosphere_5" 6 "Atmosphere_6" 7 "Atmosphere_7" 8 "Atmosphere_8" 9 "Atmosphere_9" 10 "Atmosphere_10" 11 "Atmosphere_11" 12 "Atmosphere_12" 13 "Atmosphere_13" 14 "Atmosphere_14" 15 "Atmosphere_15" 16 "Atmosphere_16" 17 "Atmosphere_17" 18 "Atmosphere_18" 19 "Atmosphere_19" 20 "Atmosphere_20" 21 "Atmosphere_21" 22 "Atmosphere_22" 23 "Atmosphere_23" 24 "Atmosphere_24" 25 "Atmosphere_25" 26 "Atmosphere_26" 27 "Atmosphere_27" 28 "Atmosphere_28" 29 "Atmosphere_29" 30 "Atmosphere_30" 31 "Atmosphere_31" 32 "Atmosphere_32" ;
VAL_ 2589283940 AC_FES_Atmosphere_7 0 "kein_Profil" 1 "Atmosphere_1" 2 "Atmosphere_2" 3 "Atmosphere_3" 4 "Atmosphere_4" 5 "Atmosphere_5" 6 "Atmosphere_6" 7 "Atmosphere_7" 8 "Atmosphere_8" 9 "Atmosphere_9" 10 "Atmosphere_10" 11 "Atmosphere_11" 12 "Atmosphere_12" 13 "Atmosphere_13" 14 "Atmosphere_14" 15 "Atmosphere_15" 16 "Atmosphere_16" 17 "Atmosphere_17" 18 "Atmosphere_18" 19 "Atmosphere_19" 20 "Atmosphere_20" 21 "Atmosphere_21" 22 "Atmosphere_22" 23 "Atmosphere_23" 24 "Atmosphere_24" 25 "Atmosphere_25" 26 "Atmosphere_26" 27 "Atmosphere_27" 28 "Atmosphere_28" 29 "Atmosphere_29" 30 "Atmosphere_30" 31 "Atmosphere_31" 32 "Atmosphere_32" ;
VAL_ 680 ACA_Querfuehrung_Texte 0 "keine_Anzeige" 1 "nicht_verfuegbar" 2 "keine_Sensorsicht" 3 "Fahreruebernahme" ;
VAL_ 680 ACA_Hinweistexte 0 "keine_Anzeige" 1 "QF_eingeschaltet" 2 "QF_ausgeschaltet" ;
VAL_ 680 ACC_FoD_Status 0 "Init" 1 "Funktion_inaktiv" 2 "Funktion_aktiv" ;
VAL_ 680 ACC_Texte_Abstandswarner 0 "keine_Anzeige" 1 "Systemstoerung" 2 "keine_Sensorsicht" 3 "zurzeit_eingeschraenkt" ;
VAL_ 680 ACC_Vorz_Abstandswarner 0 "keine_Anzeige" 1 "kleiner" 2 "groesser" 3 "kleiner_Warnung" ;
VAL_ 680 ACC_Texte_Sekundaeranz 0 "keine_Anzeige" 1 "Zielfahrzeug_erkannt" 2 "Rechtskurve_voraus" 3 "Linkskurve_voraus" 4 "Tempolimit_voraus" 5 "Sensorsicht" 6 "Anfahrbereit" 7 "Tempolimit_erkannt" 8 "Kreuzung_voraus" 9 "Kreisverkehr_voraus" 10 "Autobahnabfahrt_voraus" 11 "Stauende_voraus" 12 "Gefaelle_voraus" 13 "Hindernis_erkannt" 14 "TA_Hindernis_erkannt" 15 "TA_Anfahrbereit" ;
VAL_ 680 ACC_Status_Anzeige 0 "ACC_GRA_Hauptschalter_aus" 1 "ACC_in_Init_nicht_bei_GRA" 2 "ACC_GRA_passiv" 3 "ACC_GRA_aktiv" 4 "ACC_GRA_im_Hintergrund_uebertreten" 5 "ACC_GRA_Abschaltreaktion" 6 "ACC_reversibel_aus_nicht_bei_GRA" 7 "ACC_GRA_irreversibel_aus" ;
VAL_ 680 ACC_Akustik_03 0 "keine_Akustik" 1 "niederpriore_Akustik" 2 "mittelpriore_Akustik" 3 "hochpriore_Akustik" 4 "hochpriore_Dauerakustik" 5 "hochpriore_Dauerakustik_02" ;
VAL_ 680 ACC_Geschw_Zielfahrzeug 1023 "Neutralwert" ;
VAL_ 680 ACC_Texte_02 0 "keine_Anzeige" 1 "ACC_zurzeit_nicht_verfuegbar" 2 "ACC_Stoerung" 3 "ACC_keine_Sensorsicht" 4 "ACC_Steigung_zu_gross" 5 "ACC_nur_in_Fahrstufe_verfuegbar" 6 "ACC_Parkbremse_betaetigt" 7 "ACC_ESP_Eingriff" 8 "ACC_HDC_betaetigt" 9 "ACC_Geschwindigkeitsgrenze" 10 "ACC_Schalthebelposition" 11 "ACC_Drehzahl" 12 "ACC_Kupplung_betaetigt" 13 "ACC_ESC_aus" 14 "ACC_Bitte_uebernehmen" 15 "ACC_Aktivierverhinderung" 16 "ACC_eingeschraenkte_Funktion" 17 "ACC_Manoevrierassistent_aktiv" 18 "ACC_Parkassistent_aktiv" 19 "ACC_Stehendes_Objekt_voraus" 20 "ACC_aus" 21 "ACC_startet" 22 "ACC_Tuer_offen" 23 "ACC_Fahrer_Gurtschloss_offen" 25 "ACC_Abschaltung" 26 "ACC_Charisma_Modus_inkompatibel" 27 "ACC_verfuegbar" 28 "ACC_und_GRA_nicht_verfuegbar" 29 "Fehler_ACC_und_GRA" 30 "GRA_deaktiviert" 31 "keine_Abstandsregelung" 32 "GRA_zurzeit_nicht_verfuegbar" 33 "Fehler_GRA" 34 "ACC_nicht_ueber_FOD_freigeschalt" 35 "Fahrersitz_nicht_belegt" ;
VAL_ 680 ACC_STA_Text 0 "ACC_Text" 1 "ACC_STA_Text" ;
VAL_ 680 ACC_Status_Stauende 0 "deaktiviert" 1 "aktiviert" ;
VAL_ 680 STA_Texte 0 "keine_Anzeige" 1 "STA_nicht_verfuegbar" 2 "STA_Fahreruebernahme" 3 "STA_Constant_brake_mode" 4 "STA_Gurtschloss_nicht_gesteckt" 5 "STA_Fahrzeugeschw_zu_hoch" 6 "STA_Freifahrt" 7 "STA_Systemgrenze" ;
VAL_ 680 AbstWarn_LRR_FAS_Fkt_Status 0 "Init" 1 "Funktion_Ist_Ein" 2 "Funktion_Ist_Aus" 3 "Fehler" ;
VAL_ 680 STA_Zusatzanz 0 "keine_Anzeige" 1 "STA_verfuegbar" 2 "STA_aktiv" 3 "STA_Warnung" ;
VAL_ 680 FAS_Licht_Anf 0 "keine_Anforderung" 1 "Anforderung" ;
VAL_ 680 ACC_Zeitluecke_Abstandswarner 61 "Freifahrt" 62 "nicht_definiert" 63 "keine_Anzeige" ;
VAL_ 680 ACC_Abstand_Abstandswarner 509 "Freifahrt" 510 "nicht_definiert" 511 "keine_Anzeige" ;
VAL_ 680 ACC_Einheit_Abstandswarner 0 "Meter" 1 "Yard" ;
VAL_ 1660 AGA_Texte 0 "keine_Anzeige" 1 "Aussensound_defekt" 2 "Aussensound_deaktiviert" 3 "Aussensound_deaktiviert_reduziertWarn" 4 "Aussensound_aktiviert" 5 "Aussensound_deaktiviert_KL15" ;
VAL_ 1660 E_Sound_verbaut 0 "nicht_verbaut" 1 "verbaut" ;
VAL_ 1660 AGA_Charisma_FahrPr 0 "keine_Funktion" 1 "Programm_1" 2 "Programm_2" 3 "Programm_3" 4 "Programm_4" 5 "Programm_5" 6 "Programm_6" 7 "Programm_7" 8 "Programm_8" 9 "Programm_9" 10 "Programm_10" 11 "Programm_11" 12 "Programm_12" 13 "Programm_13" 14 "Programm_14" 15 "Programm_15" ;
VAL_ 1660 AGA_Charisma_Status 0 "Init" 1 "verfuegbar" 2 "nicht_verfuegbar" 3 "asynchron_durch_Fahrerwunsch" ;
VAL_ 1660 AGA_ohne_Funktion 0 "kein_Fehler" 1 "Fehler" ;
VAL_ 1660 AGA_Verstaerker_Mute 0 "Mute" 1 "Kein_Mute" ;
VAL_ 64 AB_RGS_Anst 4 "aktiv_Niveau_1" 5 "aktiv_Niveau_2" 6 "aktiv_Niveau_3" 7 "aktiv_Niveau_4" 8 "deaktiviert" ;
VAL_ 64 AB_Front_Crash 0 "kein_Front_Crash" 1 "Front_Crash" ;
VAL_ 64 AB_Heck_Crash 0 "kein_Heck_Crash" 1 "Heck_Crash" ;
VAL_ 64 AB_SF_Crash 0 "kein_Seiten_Crash_Fahrer" 1 "Seiten_Crash_Fahrer" ;
VAL_ 64 AB_SB_Crash 0 "kein_Seiten_Crash_Beifahrer" 1 "Seiten_Crash_Beifahrer" ;
VAL_ 64 AB_Rollover_Crash 0 "kein_Rollover" 1 "Rollover" ;
VAL_ 64 AB_Crash_Int 0 "kein_Crash" 1 "Crash_Intensitaet_1" 2 "Crash_Intensitaet_2_(nur_Stellgliedtest_MLB_B8)" 3 "Crash_Intensitaet_2_(nur_D4_C7_Colorado_NF_PAG__Crash_im_MLB_B8)" 4 "Crash_Intensitaet_3_(alt_VW/AUDI__Stellgliedtest_MLB_B8)" 5 "Crash_Intensitaet_3_(alt_PAG)" 7 "Crash_Intensitaet_3" ;
VAL_ 64 AB_Lampe 0 "Aus" 1 "Ein" ;
VAL_ 64 AB_Deaktiviert 0 "aktiv" 1 "deaktiviert" ;
VAL_ 64 AB_VB_deaktiviert 0 "Beifahrerairbag_aktiv" 1 "Beifahrerairbag_deaktiviert" ;
VAL_ 64 AB_Systemfehler 0 "kein_Fehler" 1 "Airbag_Systemfehler" ;
VAL_ 64 AB_Diagnose 0 "nicht_in_Diagnose" 1 "in_Diagnose" ;
VAL_ 64 AB_Stellgliedtest 0 "nicht_im_Stellgliedtest" 1 "Airbag_im_Stellgliedtest" ;
VAL_ 64 AB_Erh_Auf_VB 0 "keine_Anzeige" 1 "Beifahrerairbag_deaktiviert" 2 "Beifahrerairbag_aktiviert" 3 "nicht_definiert" ;
VAL_ 64 AB_Gurtwarn_VF 0 "keine_Warnung" 1 "Gurtwarnung_ausloesen" ;
VAL_ 64 AB_Gurtwarn_VB 0 "keine_Warnung" 1 "Gurtwarnung_ausloesen" ;
VAL_ 64 AB_Anzeige_Fussg 0 "keine_FSG_Aktion_ausgeloest" 1 "Motorhaube_offen" 2 "Systemfehler" ;
VAL_ 64 AB_Texte_AKS 0 "keine_AKS_Ausloesung" 1 "AKS_ausgeloest" 2 "AKS_Systemfehler" ;
VAL_ 64 AB_PAO_Leuchte_Anf 0 "Leuchte_ausschalten" 1 "Leuchte_einschalten" ;
VAL_ 64 AB_MKB_gueltig 0 "Multikollisionsbremsung_nicht_freigeschaltet" 1 "Multikollisionsbremsung_freigeschaltet" ;
VAL_ 64 AB_MKB_Anforderung 0 "Multikollisionsbremsung_nicht_angefordert" 1 "Multikollisionsbremsung_angefordert" ;
VAL_ 64 AB_Versorgungsspannung 0 "plausibel" 1 "unplausibel" ;
VAL_ 64 AB_Deaktivierung_HV 0 "keine_Deaktivierung" 1 "Deaktivierung_1" 2 "Deaktivierung_2" 3 "Deaktivierung_3" 4 "Deaktivierung_4" 5 "Deaktivierung_5" 6 "Deaktivierung_6" 7 "Fehler" ;
VAL_ 64 AB_EDR_Trigger 0 "No_Event" 1 "Start_Event" 2 "NonDeployment_Event" 3 "Deployment_Event" ;
VAL_ 64 AB_Belegung_VF 0 "nicht_verfuegbar" 1 "Fehler" 2 "nicht_belegt" 3 "belegt" ;
VAL_ 64 AB_Gurtschloss_FA_ext 0 "nicht_verbaut" 1 "reserviert" 2 "nicht_gesteckt" 3 "gesteckt" 4 "dauerhaft_nicht_gesteckt" 5 "dauerhaft_gesteckt" 6 "Init" 7 "Fehler" ;
VAL_ 64 AB_Gurtschloss_FA_ext_aktiv 0 "inaktiv" 1 "aktiv" ;
VAL_ 64 AB_eCS_Error 0 "keine_Anzeige" 1 "Anzeige_anfordern" ;
VAL_ 64 ASM_Masterzeit_02 255 "Init" ;
VAL_ 1312 LoGeWa_Event_Kombiwarnung 0 "Init" 1 "Unfall" 2 "Traktionsverlust" 3 "Panne" 4 "Sichtbehinderung" 5 "Aquaplaning" ;
VAL_ 1312 AB_Anforderung_eCall 0 "keine_Anforderung" 1 "Anforderung" ;
VAL_ 1312 AB_Anprall_Seite_Beifahrer 0 "kein_Anprall" 1 "Anprall_erkannt" ;
VAL_ 1312 AB_Anprall_Rollover 0 "kein_Anprall" 1 "Anprall_erkannt" ;
VAL_ 1312 AB_Anprall_FGS 0 "kein_Anprall" 1 "Anprall_erkannt" ;
VAL_ 1312 AB_Anprall_Front_Beifahrer 0 "kein_Anprall" 1 "Anprall_erkannt" ;
VAL_ 1312 AB_Anprall_Front_Fahrer 0 "kein_Anprall" 1 "Anprall_erkannt" ;
VAL_ 1312 AB_Anprall_Heck_Beifahrer 0 "kein_Anprall" 1 "Anprall_erkannt" ;
VAL_ 1312 AB_Anprall_Heck_Fahrer 0 "kein_Anprall" 1 "Anprall_erkannt" ;
VAL_ 1312 AB_Wickelklappung_Reihe2_MI 0 "nicht_verbaut" 1 "nicht_verfuegbar__Fehler_oder_Init" 2 "nicht_verriegelt" 3 "verriegelt" ;
VAL_ 1312 AB_Belegung_VB 0 "nicht_verfuegbar" 1 "Fehler" 2 "nicht_belegt" 3 "belegt" ;
VAL_ 1312 AB_Abschaltanf_SIH_BF 0 "Normalbetrieb" 1 "Abschaltung_angefordert" ;
VAL_ 1312 AB_Anprall_Seite_Fahrer 0 "kein_Anprall" 1 "Anprall_erkannt" ;
VAL_ 1312 SC_PAO_Schriftzug_Anf 0 "LED aus" 1 "LED an" 2 "LED blinken" 3 "reserviert" ;
VAL_ 1312 SC_PAO_ON_Anf 0 "LED aus" 1 "LED an" 2 "LED blinken" 3 "reserviert" ;
VAL_ 1312 SC_PAO_OFF_Anf 0 "LED aus" 1 "LED an" 2 "LED blinken" 3 "reserviert" ;
VAL_ 1312 AB_Crashschwere 0 "kein_Ereignis" 1 "Crashschwere_1" 2 "Crashschwere_2" 3 "Crashschwere_3" 4 "Crashschwere_4" 5 "Crashschwere_5" 6 "Crashschwere_2_bis_5" 7 "Fehler" ;
VAL_ 1312 AB_Anforderung_USM 0 "keine_Anforderung" 1 "Anforderung" ;
VAL_ 1312 AB_Gurtschloss_FA 0 "nicht_verbaut" 1 "nicht_verfügbar (Fehler oder Init)" 2 "nicht_gesteckt" 3 "gesteckt" ;
VAL_ 1312 AB_Gurtschloss_BF 0 "nicht_verbaut" 1 "nicht_verfügbar (Fehler oder Init)" 2 "nicht_gesteckt" 3 "gesteckt" ;
VAL_ 1312 AB_Gurtschloss_Reihe2_FA 0 "nicht_verbaut" 1 "nicht_verfügbar (Fehler oder Init)" 2 "nicht_gesteckt" 3 "gesteckt" ;
VAL_ 1312 AB_Gurtschloss_Reihe2_MI 0 "nicht_verbaut" 1 "nicht_verfügbar (Fehler oder Init)" 2 "nicht_gesteckt" 3 "gesteckt" ;
VAL_ 1312 AB_Gurtschloss_Reihe2_BF 0 "nicht_verbaut" 1 "nicht_verfügbar (Fehler oder Init)" 2 "nicht_gesteckt" 3 "gesteckt" ;
VAL_ 1312 AB_Gurtschloss_Reihe3_FA 0 "nicht_verbaut" 1 "nicht_verfügbar (Fehler oder Init)" 2 "nicht_gesteckt" 3 "gesteckt" ;
VAL_ 1312 AB_Gurtschloss_Reihe3_MI 0 "nicht_verbaut" 1 "nicht_verfügbar (Fehler oder Init)" 2 "nicht_gesteckt" 3 "gesteckt" ;
VAL_ 1312 AB_Gurtschloss_Reihe3_BF 0 "nicht_verbaut" 1 "nicht_verfügbar (Fehler oder Init)" 2 "nicht_gesteckt" 3 "gesteckt" ;
VAL_ 1312 AB_Sitzpos_Sens_FA 0 "nicht verfügbar" 1 "Fehler" 2 "Sitz nicht vorne" 3 "Sitz vorne" ;
VAL_ 1312 AB_Sitzpos_Sens_BF 0 "nicht verfügbar" 1 "Fehler" 2 "Sitz nicht vorne" 3 "Sitz vorne" ;
VAL_ 1312 AB_Wickelklappung_Reihe2_BF 0 "nicht_verbaut" 1 "nicht_verfuegbar__Fehler_oder_Init" 2 "nicht_verriegelt" 3 "verriegelt" ;
VAL_ 1312 AB_Wickelklappung_Reihe2_FA 0 "nicht_verbaut" 1 "nicht_verfuegbar__Fehler_oder_Init" 2 "nicht_verriegelt" 3 "verriegelt" ;
VAL_ 65 AB_DeltaV_X_eCall 0 "Init/no_DeltaV_X_detected" 1 "DeltaV_X_less_than_neg126km/h" 255 "DeltaV_X_larger_than_pos126km/h" ;
VAL_ 65 AB_DeltaV_Y_eCall 0 "Init/no_DeltaV_Y_detected" 1 "DeltaV_Y_less_than_neg126km/h" 255 "DeltaV_Y_larger_than_pos126km/h" ;
VAL_ 65 AB_MKB_Safing 0 "Multikollisionsbremsung_nicht_bestaetigt" 1 "Multikollisionsbremsung_bestaetigt" ;
VAL_ 2527679722 AB_Gurtschloss_Reihe4_FA 0 "nicht_verbaut" 1 "nicht_verfügbar (Fehler oder Init)" 2 "nicht_gesteckt" 3 "gesteckt" ;
VAL_ 2527679722 AB_Gurtschloss_Reihe4_BF 0 "nicht_verbaut" 1 "nicht_verfügbar (Fehler oder Init)" 2 "nicht_gesteckt" 3 "gesteckt" ;
VAL_ 2527679722 AB_Gurtschloss_Reihe4_MI 0 "nicht_verbaut" 1 "nicht_verfügbar (Fehler oder Init)" 2 "nicht_gesteckt" 3 "gesteckt" ;
VAL_ 2527679722 AB_wSBR_Batteriestatus 0 "Batterien_OK" 1 "mindestens_eine_Batterie_schwach" ;
VAL_ 2527679722 AB_Gurtwarn_VM 0 "keine_Warnung" 1 "Gurtwarnung_ausloesen" ;
VAL_ 2527679722 AB_Gurtschloss_MI 0 "nicht_verbaut" 1 "nicht_verfügbar (Fehler oder Init)" 2 "nicht_gesteckt" 3 "gesteckt" ;
VAL_ 2527679722 AB_Anzeige_Komfort_HBFS 0 "keine_Statusanzeige" 1 "Anzeige_Lehne_ein" 2 "Anzeige_SNV_ein" 3 "Anzeige_Lehne_UND_SNV_ein" ;
VAL_ 2527679722 AB_Anzeige_Komfort_HFS 0 "keine_Statusanzeige" 1 "Anzeige_Lehne_ein" 2 "Anzeige_SNV_ein" 3 "Anzeige_Lehne_UND_SNV_ein" ;
VAL_ 2527679722 AB_Anzeige_Sitz_Komfort_HBFS 0 "keine_Statusanzeige" 1 "Anzeige_Lehne_ein" 2 "Anzeige_SNV_ein" 3 "Anzeige_Lehne_UND_SNV_ein" ;
VAL_ 2527679722 AB_Anzeige_Sitz_Komfort_HFS 0 "keine_Statusanzeige" 1 "Anzeige_Lehne_ein" 2 "Anzeige_SNV_ein" 3 "Anzeige_Lehne_UND_SNV_ein" ;
VAL_ 2527679722 AB_Status_Sitz_SRAB_HBFS 0 "Einschaltung_SRAB" 1 "Abschaltung_SRAB" 2 "Init" 3 "Fehler" ;
VAL_ 2527679722 AB_Status_Sitz_SRAB_HFS 0 "Einschaltung_SRAB" 1 "Abschaltung_SRAB" 2 "Init" 3 "Fehler" ;
VAL_ 2527679722 AB_Anzeige_Kombi_SRAB 0 "keine_Statusanzeige" 1 "HFS_EIN_HFBS_EIN" 2 "HFS_AUS_HFBS_AUS" 3 "HFS_EIN_HFBS_AUS" 4 "HFS_AUS_HFBS_EIN" ;
VAL_ 1633 AAG_AVS_Fehler_02_inv 0 "Fehler" 1 "kein_Fehler" ;
VAL_ 1633 AAG_Bremsl_durch_ECD 0 "Bremslicht_ist_aus" 1 "Bremslicht_durch_ECD_aktiv" ;
VAL_ 1633 AAG_Anhaenger_abgesteckt 1 "Anhaenger_wurde_bei_KL15_aus_abgesteckt" ;
VAL_ 1633 AAG_NSL_aktiv 0 "Init" 1 "Anhaenger_Nebelschusslicht_aktiv" ;
VAL_ 1633 AAG_Anhaenger_erkannt 0 "kein_Anhaenger_erkannt" 1 "AAG_Anhaenger_erkannt" ;
VAL_ 1633 AAG_Blinker_H_aktiv 0 "Init" 1 "Anhaenger_Blinker_aktiv" ;
VAL_ 1633 AAG_Blinker_HL_def 0 "Init" 1 "Anhaenger_Blinker_links_defekt" ;
VAL_ 1633 AAG_Blinker_HR_def 0 "Init" 1 "Anhaenger_Blinker_rechts_defekt" ;
VAL_ 1633 AAG_Bremslicht_H_def 0 "Init" 1 "Anhaenger_Bremslicht_defekt" ;
VAL_ 1633 AAG_Schlusslicht_HL_def 0 "Init" 1 "Anhaenger_Schlusslicht_links_defekt" ;
VAL_ 1633 AAG_Schlusslicht_HR_def 0 "Init" 1 "Anhaenger_Schlusslicht_rechts_defekt" ;
VAL_ 1633 AAG_Bremslicht_Reku 0 "inaktiv" 1 "aktiv" ;
VAL_ 1633 AAG_AVS_Fehler_02 0 "kein_Fehler" 1 "Fehler" ;
VAL_ 1633 AAG_LED_aktiv 0 "Lampen" 1 "LED" ;
VAL_ 1633 AAG_AVS_Stati 0 "endlage_eingefahren_erreicht" 1 "endlage_ausgefahren_erreicht" 2 "ausfahren_automatik" 3 "einfahren_automatik" 4 "ausfahren_manuell" 5 "einfahren_manuell" 6 "zwischenposition" 7 "nicht_initialisiert" ;
